VERSION "ChassisFusionCANFD"

NS_ :

BS_:

BU_: ADD BCP BCS EPS FZCU SCU SWM VECU XCD

BO_ 186 BCS_ChassisFusion_0xBA: 32 BCS
 SG_ ABSAvailability : 108|1@0+ (1,0) [0|1] ""  BCP,XCD
 SG_ BCSFxTargetMod : 135|14@0+ (8,-131008) [-131008|0] ""  BCP,XCD
 SG_ BCSModBrakeActType : 101|3@0+ (1,0) [0|4] ""  BCP,XCD
 SG_ BCSRecuFxRedTarget : 118|15@0+ (8,-131008) [-131008|131072] "bar"  BCP,XCD
 SG_ BCSRecuStatusMod : 105|2@0+ (1,0) [0|2] ""  BCP,XCD
 SG_ BrkSysAbsActv : 85|1@0+ (1,0) [0|1] ""  BCP,XCD
 SG_ BrkSysCtrlBkpSigGrpChks : 7|8@0+ (1,0) [0|255] ""  BCP,FZCU,XCD
 SG_ BrkSysCtrlBkpSigGrpCntr : 11|4@0+ (1,0) [0|15] ""  BCP,FZCU,XCD
 SG_ BrkSysDrvrPrsnt : 84|1@0+ (1,0) [0|1] ""  BCP,XCD
 SG_ BrkSysIndcnBkpSigGrpChks : 71|8@0+ (1,0) [0|255] ""  BCP,XCD
 SG_ BrkSysIndcnBkpSigGrpCntr : 75|4@0+ (1,0) [0|15] ""  BCP,XCD
 SG_ BrkSysLdmGlbStsMod : 87|2@0+ (1,0) [0|3] ""  BCP,XCD
 SG_ BrkSysMstCylP : 23|10@0+ (0.3,-30) [-27.3|276.6] "bar"  BCP,FZCU,XCD
 SG_ BrkSysMstCylPVld : 15|3@0+ (1,0) [0|7] ""  BCP,FZCU,XCD
 SG_ BrkSysPEstimnMax : 95|8@0+ (1,0) [0|250] "bar"  BCP,XCD
 SG_ BrkSysPRedActv : 12|1@0+ (1,0) [0|1] ""  BCP,FZCU,XCD
 SG_ BrkSysPSysTar : 40|9@0+ (0.25,0) [0|120] "bar"  BCP,FZCU,XCD
 SG_ BrkSysRntSpprtAvl : 44|1@0+ (1,0) [0|1] ""  BCP,FZCU,XCD
 SG_ BrkSysVehDirInfo : 29|2@0+ (1,0) [0|3] ""  BCP,FZCU,XCD
 SG_ BrkSysVehDirInfoVld : 27|3@0+ (1,0) [0|7] ""  BCP,FZCU,XCD
 SG_ BrkSysVehSpd : 39|8@0+ (0.4,0) [0|100] "m/s"  BCP,FZCU,XCD
 SG_ BrkSysVehSpdVld : 47|3@0+ (1,0) [0|7] ""  BCP,FZCU,XCD
 SG_ BrkSysVolSuctnActv : 43|1@0+ (1,0) [0|1] ""  BCP,FZCU,XCD
 SG_ MaxTarSpdBkpSigGrpChks : 151|8@0+ (1,0) [0|255] ""  FZCU,XCD
 SG_ MaxTarSpdBkpSigGrpCntr : 155|4@0+ (1,0) [0|15] ""  FZCU,XCD
 SG_ MaxTarSpdFrntAxle : 175|15@0+ (1,0) [0|30000] "rpm"  FZCU,XCD
 SG_ MaxTarSpdFrntAxleRels : 165|2@0+ (1,0) [0|3] ""  FZCU,XCD
 SG_ MaxTarSpdReAxle : 191|15@0+ (1,0) [0|30000] "rpm"  FZCU,XCD
 SG_ MaxTarSpdReAxleRels : 167|2@0+ (1,0) [0|3] ""  FZCU,XCD
 SG_ VehicleStandStill : 24|1@0+ (1,0) [0|1] ""  BCP,FZCU,XCD
 SG_ VehicleStandStillQ : 42|2@0+ (1,0) [0|2] ""  BCP,FZCU,XCD
 SG_ VehVrnt : 207|8@0+ (1,0) [0|255] ""  FZCU,XCD

BO_ 190 BCS_ChassisFusion_0xBE: 32 BCS
 SG_ BrkSysAPCBkpStgyReqCom2 : 220|1@0+ (1,0) [0|1] ""  BCP,XCD
 SG_ BrkSysAPCMain2BkpStCom2 : 219|4@0+ (1,0) [0|15] ""  BCP,XCD
 SG_ BrkSysAPCMain2BkpStCom2SigGrpChk : 207|8@0+ (1,0) [0|255] ""  BCP,XCD
 SG_ BrkSysAPCMain2BkpStCom2SigGrpCnt : 211|4@0+ (1,0) [0|15] ""  BCP,XCD
 SG_ RpbCtrlBkpSigGrpChks : 7|8@0+ (1,0) [0|255] ""  BCP,XCD
 SG_ RpbCtrlBkpSigGrpCntr : 11|4@0+ (1,0) [0|15] ""  BCP,XCD
 SG_ RPBHpsAck : 21|1@0+ (1,0) [0|1] ""  BCP,XCD
 SG_ RPBHpsAvl : 20|1@0+ (1,0) [0|1] ""  BCP,XCD
 SG_ RPBMstCylP : 17|10@0+ (0.3,-30) [-30|276.6] "bar"  BCP,XCD
 SG_ RPBMstCylPVld : 23|2@0+ (1,0) [0|3] ""  BCP,XCD
 SG_ RPBWhlPFrntLe : 39|8@0+ (1,0) [0|180] "bar"  BCP,XCD
 SG_ RPBWhlPFrntLeVld : 15|1@0+ (1,0) [0|1] ""  BCP,XCD
 SG_ RPBWhlPFrntRi : 47|8@0+ (1,0) [0|180] "bar"  BCP,XCD
 SG_ RPBWhlPFrntRiVld : 14|1@0+ (1,0) [0|1] ""  BCP,XCD
 SG_ RPBWhlPReLe : 55|8@0+ (1,0) [0|180] "bar"  BCP,XCD
 SG_ RPBWhlPReLeVld : 13|1@0+ (1,0) [0|1] ""  BCP,XCD
 SG_ RPBWhlPReRi : 63|8@0+ (1,0) [0|180] "bar"  BCP,XCD
 SG_ RPBWhlPReRiVld : 12|1@0+ (1,0) [0|1] ""  BCP,XCD
 SG_ RPBWhlSpdFrntLe : 103|16@0+ (0.05625,0) [0|360] "kph"  BCP,FZCU,XCD
 SG_ RPBWhlSpdFrntLeVld : 95|1@0+ (1,0) [0|1] ""  BCP,FZCU,XCD
 SG_ RPBWhlSpdFrntRi : 119|16@0+ (0.05625,0) [0|360] "kph"  BCP,FZCU,XCD
 SG_ RPBWhlSpdFrntRiVld : 94|1@0+ (1,0) [0|1] ""  BCP,FZCU,XCD
 SG_ RPBWhlSpdReLe : 135|16@0+ (0.05625,0) [0|360] "kph"  BCP,FZCU,XCD
 SG_ RPBWhlSpdReLeVld : 93|1@0+ (1,0) [0|1] ""  BCP,FZCU,XCD
 SG_ RPBWhlSpdReRi : 151|16@0+ (0.05625,0) [0|360] "kph"  BCP,FZCU,XCD
 SG_ RPBWhlSpdReRiVld : 92|1@0+ (1,0) [0|1] ""  BCP,FZCU,XCD
 SG_ RPBWhlSpdSigGrpChks : 79|8@0+ (1,0) [0|255] ""  BCP,FZCU,XCD
 SG_ RPBWhlSpdSigGrpCntr : 83|4@0+ (1,0) [0|15] ""  BCP,FZCU,XCD
 SG_ WhlPulFrntLe : 167|8@0+ (1,0) [0|255] ""  BCP,FZCU,XCD
 SG_ WhlPulFrntRi : 175|8@0+ (1,0) [0|255] ""  BCP,FZCU,XCD
 SG_ WhlPulReLe : 183|8@0+ (1,0) [0|255] ""  BCP,FZCU,XCD
 SG_ WhlPulReRi : 191|8@0+ (1,0) [0|255] ""  BCP,FZCU,XCD

BO_ 1315 BCSChassisFusionNMFr: 8 BCS
 SG_ BCSChassisBkpActiveWakeup : 12|1@0+ (1,0) [0|1] "" Vector__XXX
 SG_ BCSChassisBkpNodeAddress : 7|8@0+ (1,0) [0|255] "" Vector__XXX
 SG_ BCSChassisBkpRepeatMsgReq : 8|1@0+ (1,0) [0|1] "" Vector__XXX
 SG_ BCSChassisBkpRepeatMsgSt : 16|1@0+ (1,0) [0|1] "" Vector__XXX
 SG_ NMKeepAwkRsnBCS : 48|9@0+ (1,0) [0|511] "" Vector__XXX
 SG_ UDB17BCS : 17|1@0+ (1,0) [0|1] "" Vector__XXX
 SG_ UDB18BCS : 18|1@0+ (1,0) [0|1] "" Vector__XXX
 SG_ UDB19BCS : 19|1@0+ (1,0) [0|1] "" Vector__XXX
 SG_ UDB20BCS : 20|1@0+ (1,0) [0|1] "" Vector__XXX
 SG_ UDB21BCS : 21|1@0+ (1,0) [0|1] "" Vector__XXX
 SG_ UDB22BCS : 22|1@0+ (1,0) [0|1] "" Vector__XXX
 SG_ UDB23BCS : 23|1@0+ (1,0) [0|1] "" Vector__XXX
 SG_ UDB24BCS : 24|1@0+ (1,0) [0|1] "" Vector__XXX
 SG_ UDB25BCS : 25|1@0+ (1,0) [0|1] "" Vector__XXX
 SG_ UDB26BCS : 26|1@0+ (1,0) [0|1] "" Vector__XXX
 SG_ UDB27BCS : 27|1@0+ (1,0) [0|1] "" Vector__XXX
 SG_ UDB28BCS : 28|1@0+ (1,0) [0|1] "" Vector__XXX
 SG_ UDB29BCS : 29|1@0+ (1,0) [0|1] "" Vector__XXX
 SG_ UDB30BCS : 30|1@0+ (1,0) [0|1] "" Vector__XXX
 SG_ UDB31BCS : 31|1@0+ (1,0) [0|1] "" Vector__XXX
 SG_ UDB32BCS : 32|1@0+ (1,0) [0|1] "" Vector__XXX
 SG_ UDB33BCS : 33|1@0+ (1,0) [0|1] "" Vector__XXX
 SG_ UDB34BCS : 34|1@0+ (1,0) [0|1] "" Vector__XXX
 SG_ UDB35BCS : 35|1@0+ (1,0) [0|1] "" Vector__XXX
 SG_ UDB36BCS : 36|1@0+ (1,0) [0|1] "" Vector__XXX
 SG_ UDB37BCS : 37|1@0+ (1,0) [0|1] "" Vector__XXX
 SG_ UDB38BCS : 38|1@0+ (1,0) [0|1] "" Vector__XXX
 SG_ UDB39BCS : 39|1@0+ (1,0) [0|1] "" Vector__XXX
 SG_ UDB40BCS : 40|1@0+ (1,0) [0|1] "" Vector__XXX
 SG_ UDB41BCS : 41|1@0+ (1,0) [0|1] "" Vector__XXX
 SG_ UDB42BCS : 42|1@0+ (1,0) [0|1] "" Vector__XXX
 SG_ UDB43BCS : 43|1@0+ (1,0) [0|1] "" Vector__XXX
 SG_ UDB44BCS : 44|1@0+ (1,0) [0|1] "" Vector__XXX
 SG_ UDB45BCS : 45|1@0+ (1,0) [0|1] "" Vector__XXX
 SG_ UDB46BCS : 46|1@0+ (1,0) [0|1] "" Vector__XXX
 SG_ UDB47BCS : 47|1@0+ (1,0) [0|1] "" Vector__XXX

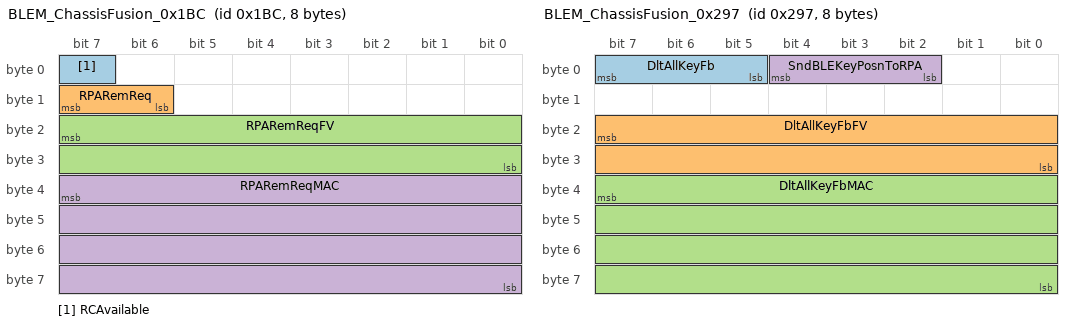
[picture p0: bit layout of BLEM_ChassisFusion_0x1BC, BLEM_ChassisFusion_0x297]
BO_ 444 BLEM_ChassisFusion_0x1BC: 8 XCD
 SG_ RCAvailable : 7|1@0+ (1,0) [0|1] ""  ADD
 SG_ RPARemReq : 15|2@0+ (1,0) [0|3] ""  ADD
 SG_ RPARemReqFV : 23|16@0+ (1,0) [0|65535] ""  ADD
 SG_ RPARemReqMAC : 39|32@0+ (1,0) [0|0] ""  ADD

BO_ 657 BLEM_ChassisFusion_0x291: 64 XCD
 SG_ BLEM2VCCDForLocn10 : 7|32@0+ (1,0) [0|4294967295] ""  ADD
 SG_ BLEM2VCCDForLocn11 : 39|32@0+ (1,0) [0|4294967295] ""  ADD
 SG_ BLEM2VCCDForLocn12 : 71|32@0+ (1,0) [0|4294967295] ""  ADD
 SG_ BLEM2VCCDForLocn13 : 103|32@0+ (1,0) [0|4294967295] ""  ADD
 SG_ BLEM2VCCDForLocn14 : 135|32@0+ (1,0) [0|4294967295] ""  ADD
 SG_ BLEM2VCCDForLocn15 : 167|32@0+ (1,0) [0|4294967295] ""  ADD
 SG_ BLEM2VCCDForLocn16 : 199|32@0+ (1,0) [0|4294967295] ""  ADD
 SG_ BLEM2VCCDForLocn17 : 231|32@0+ (1,0) [0|4294967295] ""  ADD
 SG_ BLEM2VCCDForLocn18 : 263|32@0+ (1,0) [0|4294967295] ""  ADD
 SG_ BLEM2VCCDForLocn19 : 295|32@0+ (1,0) [0|4294967295] ""  ADD
 SG_ BLEM2VCCDForLocn1A : 327|32@0+ (1,0) [0|4294967295] ""  ADD
 SG_ BLEM2VCCDForLocn1B : 359|32@0+ (1,0) [0|4294967295] ""  ADD
 SG_ BLEM2VCCDForLocn1C : 391|32@0+ (1,0) [0|4294967295] ""  ADD
 SG_ BLEM2VCCDForLocn1D : 423|32@0+ (1,0) [0|4294967295] ""  ADD
 SG_ BLEM2VCCDForLocn1F : 455|16@0+ (1,0) [0|65535] ""  ADD
 SG_ BLEM2VCCDForLocn1FV : 471|16@0+ (1,0) [0|65535] ""  ADD
 SG_ BLEM2VCCDForLocn1MAC : 487|32@0+ (1,0) [0|0] ""  ADD

BO_ 663 BLEM_ChassisFusion_0x297: 8 XCD
 SG_ DltAllKeyFb : 7|3@0+ (1,0) [0|7] "" Vector__XXX
 SG_ DltAllKeyFbFV : 23|16@0+ (1,0) [0|65535] ""  ADD
 SG_ DltAllKeyFbMAC : 39|32@0+ (1,0) [0|0] ""  ADD
 SG_ SndBLEKeyPosnToRPA : 4|3@0+ (1,0) [0|7] ""  ADD

BO_ 665 BLEM_ChassisFusion_0x299: 64 XCD
 SG_ BLEM2VCCDForLocn20 : 7|32@0+ (1,0) [0|4294967295] ""  ADD
 SG_ BLEM2VCCDForLocn21 : 39|32@0+ (1,0) [0|4294967295] ""  ADD
 SG_ BLEM2VCCDForLocn22 : 71|32@0+ (1,0) [0|4294967295] ""  ADD
 SG_ BLEM2VCCDForLocn23 : 103|32@0+ (1,0) [0|4294967295] ""  ADD
 SG_ BLEM2VCCDForLocn24 : 135|32@0+ (1,0) [0|4294967295] ""  ADD
 SG_ BLEM2VCCDForLocn25 : 167|32@0+ (1,0) [0|4294967295] ""  ADD
 SG_ BLEM2VCCDForLocn26 : 199|32@0+ (1,0) [0|4294967295] ""  ADD
 SG_ BLEM2VCCDForLocn27 : 231|32@0+ (1,0) [0|4294967295] ""  ADD
 SG_ BLEM2VCCDForLocn28 : 263|32@0+ (1,0) [0|4294967295] ""  ADD
 SG_ BLEM2VCCDForLocn29 : 295|32@0+ (1,0) [0|4294967295] ""  ADD
 SG_ BLEM2VCCDForLocn2A : 327|32@0+ (1,0) [0|4294967295] ""  ADD
 SG_ BLEM2VCCDForLocn2B : 359|32@0+ (1,0) [0|4294967295] ""  ADD
 SG_ BLEM2VCCDForLocn2C : 391|32@0+ (1,0) [0|4294967295] ""  ADD
 SG_ BLEM2VCCDForLocn2D : 423|32@0+ (1,0) [0|4294967295] ""  ADD
 SG_ BLEM2VCCDForLocn2F : 455|16@0+ (1,0) [0|65535] ""  ADD
 SG_ BLEM2VCCDForLocn2FV : 471|16@0+ (1,0) [0|65535] ""  ADD
 SG_ BLEM2VCCDForLocn2MAC : 487|32@0+ (1,0) [0|0] ""  ADD

BO_ 758 BLEM_ChassisFusion_0x2F6: 16 XCD
 SG_ FrntLeTyrePSnsrLoBattWarn : 47|1@0+ (1,0) [0|1] "" Vector__XXX
 SG_ FrntLeTyrePSnsrLostWarn : 46|1@0+ (1,0) [0|1] "" Vector__XXX
 SG_ FrntLeTyrePSnsrLrngSts : 57|2@0+ (1,0) [0|3] "" Vector__XXX
 SG_ FrntLeTyrePVal : 31|8@0+ (2.75,0) [0|698.5] "kpa"  ADD
 SG_ FrntLeTyrePWarn : 19|2@0+ (1,0) [0|3] ""  ADD
 SG_ FrntLeTyreTWarn : 55|2@0+ (1,0) [0|3] "" Vector__XXX
 SG_ FrntRiTyrePSnsrLoBattWarn : 45|1@0+ (1,0) [0|1] "" Vector__XXX
 SG_ FrntRiTyrePSnsrLostWarn : 44|1@0+ (1,0) [0|1] "" Vector__XXX
 SG_ FrntRiTyrePSnsrLrngSts : 63|2@0+ (1,0) [0|3] "" Vector__XXX
 SG_ FrntRiTyrePVal : 39|8@0+ (2.75,0) [0|698.5] "kpa"  ADD
 SG_ FrntRiTyrePWarn : 17|2@0+ (1,0) [0|3] ""  ADD
 SG_ FrntRiTyreTWarn : 53|2@0+ (1,0) [0|3] "" Vector__XXX
 SG_ ReLeTyrePSnsrLoBattWarn : 43|1@0+ (1,0) [0|1] "" Vector__XXX
 SG_ ReLeTyrePSnsrLostWarn : 42|1@0+ (1,0) [0|1] "" Vector__XXX
 SG_ ReLeTyrePSnsrLrngSts : 61|2@0+ (1,0) [0|3] "" Vector__XXX
 SG_ ReLeTyrePVal : 7|8@0+ (2.75,0) [0|698.5] "kpa"  ADD
 SG_ ReLeTyrePWarn : 23|2@0+ (1,0) [0|3] ""  ADD
 SG_ ReLeTyreTWarn : 51|2@0+ (1,0) [0|3] "" Vector__XXX
 SG_ ReRiTyrePSnsrLoBattWarn : 41|1@0+ (1,0) [0|1] "" Vector__XXX
 SG_ ReRiTyrePSnsrLostWarn : 40|1@0+ (1,0) [0|1] "" Vector__XXX
 SG_ ReRiTyrePSnsrLrngSts : 59|2@0+ (1,0) [0|3] "" Vector__XXX
 SG_ ReRiTyrePVal : 15|8@0+ (2.75,0) [0|698.5] "kpa"  ADD
 SG_ ReRiTyrePWarn : 21|2@0+ (1,0) [0|3] ""  ADD
 SG_ ReRiTyreTWarn : 49|2@0+ (1,0) [0|3] "" Vector__XXX
 SG_ TyrePWarnFV : 87|16@0+ (1,0) [0|65535] ""  ADD
 SG_ TyrePWarnMAC : 103|32@0+ (1,0) [0|4294967295] ""  ADD
 SG_ TyrePwarnSts : 71|2@0+ (1,0) [0|3] "" Vector__XXX

BO_ 817 BLEM_ChassisFusion_0x331: 64 XCD
 SG_ BLEM2VCCDForLocn40 : 135|32@0+ (1,0) [0|4294967295] ""  ADD
 SG_ BLEM2VCCDForLocn41 : 167|32@0+ (1,0) [0|4294967295] ""  ADD
 SG_ BLEM2VCCDForLocn42 : 199|32@0+ (1,0) [0|4294967295] ""  ADD
 SG_ BLEM2VCCDForLocn43 : 231|32@0+ (1,0) [0|4294967295] ""  ADD
 SG_ BLEM2VCCDForLocn44 : 7|32@0+ (1,0) [0|4294967295] ""  ADD
 SG_ BLEM2VCCDForLocn45 : 39|32@0+ (1,0) [0|4294967295] ""  ADD
 SG_ BLEM2VCCDForLocn46 : 71|32@0+ (1,0) [0|4294967295] ""  ADD
 SG_ BLEM2VCCDForLocn47 : 103|32@0+ (1,0) [0|4294967295] ""  ADD
 SG_ BLEM2VCCDForLocn48 : 263|32@0+ (1,0) [0|4294967295] ""  ADD
 SG_ BLEM2VCCDForLocn49 : 295|32@0+ (1,0) [0|4294967295] ""  ADD
 SG_ BLEM2VCCDForLocn4A : 327|32@0+ (1,0) [0|4294967295] ""  ADD
 SG_ BLEM2VCCDForLocn4B : 359|32@0+ (1,0) [0|4294967295] ""  ADD
 SG_ BLEM2VCCDForLocn4C : 391|32@0+ (1,0) [0|4294967295] ""  ADD
 SG_ BLEM2VCCDForLocn4D : 423|32@0+ (1,0) [0|4294967295] ""  ADD
 SG_ BLEM2VCCDForLocn4F : 455|16@0+ (1,0) [0|65535] ""  ADD
 SG_ BLEM2VCCDForLocn4FV : 471|16@0+ (1,0) [0|65535] ""  ADD
 SG_ BLEM2VCCDForLocn4MAC : 487|32@0+ (1,0) [0|0] ""  ADD

BO_ 825 BLEM_ChassisFusion_0x339: 32 XCD
 SG_ BLEM2ADDForRPA00 : 7|64@0+ (1,0) [0|1.84467440737096E+019] ""  ADD
 SG_ BLEM2ADDForRPA00FV : 215|16@0+ (1,0) [0|65535] ""  ADD
 SG_ BLEM2ADDForRPA00MAC : 231|32@0+ (1,0) [0|0] ""  ADD
 SG_ BLEM2ADDForRPA01 : 71|64@0+ (1,0) [0|1.84467440737096E+019] ""  ADD
 SG_ BLEM2ADDForRPA02 : 135|64@0+ (1,0) [0|1.84467440737096E+019] ""  ADD
 SG_ BLEM2ADDForRPA03 : 199|16@0+ (1,0) [0|65535] ""  ADD

BO_ 826 BLEM_ChassisFusion_0x33A: 64 XCD
 SG_ BLEM2VCCDForLocn30 : 7|32@0+ (1,0) [0|4294967295] ""  ADD
 SG_ BLEM2VCCDForLocn31 : 39|32@0+ (1,0) [0|4294967295] ""  ADD
 SG_ BLEM2VCCDForLocn32 : 71|32@0+ (1,0) [0|4294967295] ""  ADD
 SG_ BLEM2VCCDForLocn33 : 103|32@0+ (1,0) [0|4294967295] ""  ADD
 SG_ BLEM2VCCDForLocn34 : 135|32@0+ (1,0) [0|4294967295] ""  ADD
 SG_ BLEM2VCCDForLocn35 : 167|32@0+ (1,0) [0|4294967295] ""  ADD
 SG_ BLEM2VCCDForLocn36 : 199|32@0+ (1,0) [0|4294967295] ""  ADD
 SG_ BLEM2VCCDForLocn37 : 231|32@0+ (1,0) [0|4294967295] ""  ADD
 SG_ BLEM2VCCDForLocn38 : 263|32@0+ (1,0) [0|4294967295] ""  ADD
 SG_ BLEM2VCCDForLocn39 : 295|32@0+ (1,0) [0|4294967295] ""  ADD
 SG_ BLEM2VCCDForLocn3A : 327|32@0+ (1,0) [0|4294967295] ""  ADD
 SG_ BLEM2VCCDForLocn3B : 359|32@0+ (1,0) [0|4294967295] ""  ADD
 SG_ BLEM2VCCDForLocn3C : 391|32@0+ (1,0) [0|4294967295] ""  ADD
 SG_ BLEM2VCCDForLocn3D : 423|32@0+ (1,0) [0|4294967295] ""  ADD
 SG_ BLEM2VCCDForLocn3F : 455|16@0+ (1,0) [0|65535] ""  ADD
 SG_ BLEM2VCCDForLocn3FV : 471|16@0+ (1,0) [0|65535] ""  ADD
 SG_ BLEM2VCCDForLocn3MAC : 487|32@0+ (1,0) [0|0] ""  ADD

BO_ 827 BLEM_ChassisFusion_0x33B: 64 XCD
 SG_ BLEM2VCCDForRkeReq00 : 7|32@0+ (1,0) [0|4294967295] ""  ADD,FZCU
 SG_ BLEM2VCCDForRkeReq01 : 39|32@0+ (1,0) [0|4294967295] ""  ADD,FZCU
 SG_ BLEM2VCCDForRkeReq02 : 71|32@0+ (1,0) [0|4294967295] ""  ADD,FZCU
 SG_ BLEM2VCCDForRkeReq03 : 103|32@0+ (1,0) [0|4294967295] ""  ADD,FZCU
 SG_ BLEM2VCCDForRkeReq04 : 135|32@0+ (1,0) [0|4294967295] ""  ADD,FZCU
 SG_ BLEM2VCCDForRkeReq05 : 167|32@0+ (1,0) [0|4294967295] ""  ADD,FZCU
 SG_ BLEM2VCCDForRkeReq06 : 199|32@0+ (1,0) [0|4294967295] ""  ADD,FZCU
 SG_ BLEM2VCCDForRkeReq07 : 231|32@0+ (1,0) [0|4294967295] ""  ADD,FZCU
 SG_ BLEM2VCCDForRkeReq08 : 263|32@0+ (1,0) [0|4294967295] ""  ADD,FZCU
 SG_ BLEM2VCCDForRkeReq09 : 295|32@0+ (1,0) [0|4294967295] ""  ADD,FZCU
 SG_ BLEM2VCCDForRkeReq10 : 327|32@0+ (1,0) [0|4294967295] ""  ADD,FZCU
 SG_ BLEM2VCCDForRkeReq11 : 359|32@0+ (1,0) [0|4294967295] ""  ADD,FZCU
 SG_ BLEM2VCCDForRkeReq12 : 391|32@0+ (1,0) [0|4294967295] ""  ADD,FZCU
 SG_ BLEM2VCCDForRkeReq13 : 423|32@0+ (1,0) [0|4294967295] ""  ADD,FZCU
 SG_ BLEM2VCCDForRkeReq14 : 455|16@0+ (1,0) [0|65535] ""  ADD,FZCU
 SG_ BLEM2VCCDForRkeReqFV : 471|16@0+ (1,0) [0|65535] ""  ADD,FZCU
 SG_ BLEM2VCCDForRkeReqMAC : 487|32@0+ (1,0) [0|0] ""  ADD,FZCU

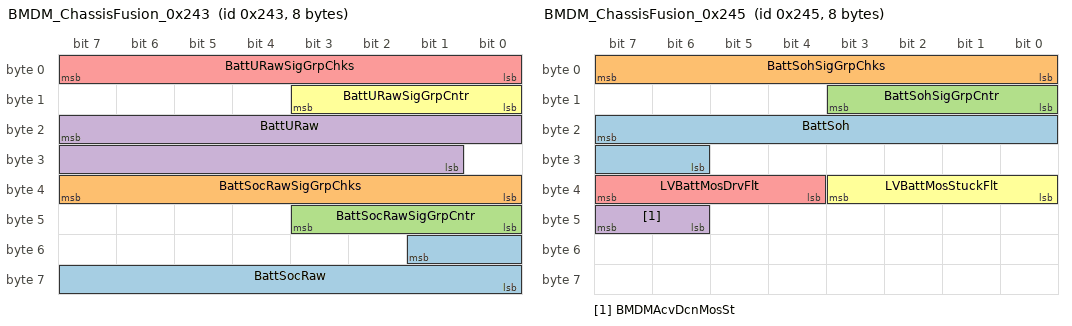
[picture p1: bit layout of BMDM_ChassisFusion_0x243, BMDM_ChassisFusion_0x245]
BO_ 579 BMDM_ChassisFusion_0x243: 8 XCD
 SG_ BattSocRaw : 49|10@0+ (0.1,0) [0|102.3] "%"  SCU,SWM
 SG_ BattSocRawSigGrpChks : 39|8@0+ (1,0) [0|255] ""  SCU,SWM
 SG_ BattSocRawSigGrpCntr : 43|4@0+ (1,0) [0|15] ""  SCU,SWM
 SG_ BattURaw : 23|15@0+ (0.001,0) [0|18] "V"  SCU,SWM
 SG_ BattURawSigGrpChks : 7|8@0+ (1,0) [0|255] ""  SCU,SWM
 SG_ BattURawSigGrpCntr : 11|4@0+ (1,0) [0|15] ""  SCU,SWM

BO_ 581 BMDM_ChassisFusion_0x245: 8 XCD
 SG_ BattSoh : 23|10@0+ (0.1,0) [0|102.3] "%"  ADD
 SG_ BattSohSigGrpChks : 7|8@0+ (1,0) [0|255] ""  ADD
 SG_ BattSohSigGrpCntr : 11|4@0+ (1,0) [0|15] ""  ADD
 SG_ BMDMAcvDcnMosSt : 47|2@0+ (1,0) [0|3] ""  ADD
 SG_ LVBattMosDrvFlt : 39|4@0+ (1,0) [0|15] "" Vector__XXX
 SG_ LVBattMosStuckFlt : 35|4@0+ (1,0) [0|15] "" Vector__XXX

BO_ 912 BMS_ChassisFusion_0x390: 32 XCD
 SG_ BalOnCellNumb : 207|8@0+ (1,0) [0|255] "" Vector__XXX
 SG_ CMU1ComErrTi : 87|8@0+ (0.5,0) [0|127.5] "s" Vector__XXX
 SG_ CMU2ComErrTi : 95|8@0+ (0.5,0) [0|127.5] "s" Vector__XXX
 SG_ CMU3ComErrTi : 103|8@0+ (0.5,0) [0|127.5] "s" Vector__XXX
 SG_ HvBattCellAvrgSocErr : 135|11@0+ (0.05,0) [0|100] "%" Vector__XXX
 SG_ HvBattCellMaxSoc : 114|11@0+ (0.05,0) [0|100] "%" Vector__XXX
 SG_ HvBattCellMaxSocErr : 183|11@0+ (0.05,0) [0|100] "%" Vector__XXX
 SG_ HvBattCellMaxSocErrIdx : 175|8@0+ (1,0) [1|255] "" Vector__XXX
 SG_ HvBattCellMaxSocIdx : 159|8@0+ (1,0) [1|255] "" Vector__XXX
 SG_ HvBattCellMinSoc : 186|11@0+ (0.05,0) [0|100] "%" Vector__XXX
 SG_ HvBattCellMinSocIdx : 167|8@0+ (1,0) [1|255] "" Vector__XXX
 SG_ HvBattEgyAvlForChrgnToTarSoC : 55|13@0+ (20,0) [0|163000] "Wh" Vector__XXX
 SG_ HvBattEgyAvlForDchrgnToTarSoC : 39|13@0+ (20,0) [0|163000] "Wh" Vector__XXX
 SG_ HvBattPressureInsdPack : 71|12@0+ (0.1,0) [0|409.4] "kPa"  SCU
 SG_ HvBattSoCLimMax : 7|11@0+ (0.05,0) [0|100] "%" Vector__XXX
 SG_ HvBattSoCLimMin : 23|11@0+ (0.05,0) [0|100] "%" Vector__XXX
 SG_ HvPrechargeTimer : 140|13@0+ (1,0) [0|8191] "" Vector__XXX

BO_ 355 EPS_ChassisFusion_0x163: 16 EPS
 SG_ AVPHPPCtrlAvlStsBkp : 71|2@0+ (1,0) [0|3] ""  ADD,XCD
 SG_ AVPHPPCtrStsBkp : 56|1@0+ (1,0) [0|1] ""  ADD,XCD
 SG_ AVPHPPReqFbStsBkp : 59|3@0+ (1,0) [0|7] ""  ADD,XCD
 SG_ AVPHPPReqFltStsBkp : 63|4@0+ (1,0) [0|15] ""  ADD,XCD
 SG_ EPSAVPHPPCtrlStsBkpSigGrpChks : 47|8@0+ (1,0) [0|255] ""  ADD,XCD
 SG_ EPSAVPHPPCtrlStsBkpSigGrpCntr : 51|4@0+ (1,0) [0|15] ""  ADD,XCD
 SG_ EPSBkpFaultInfoFlag : 7|1@0+ (1,0) [0|1] ""  XCD
 SG_ FailrStsBkp : 38|3@0+ (1,0) [0|7] ""  ADD,XCD
 SG_ FailrStsBkpSigGrpChks : 31|8@0+ (1,0) [0|255] ""  ADD,XCD
 SG_ FailrStsBkpSigGrpCntr : 35|4@0+ (1,0) [0|15] ""  ADD,XCD

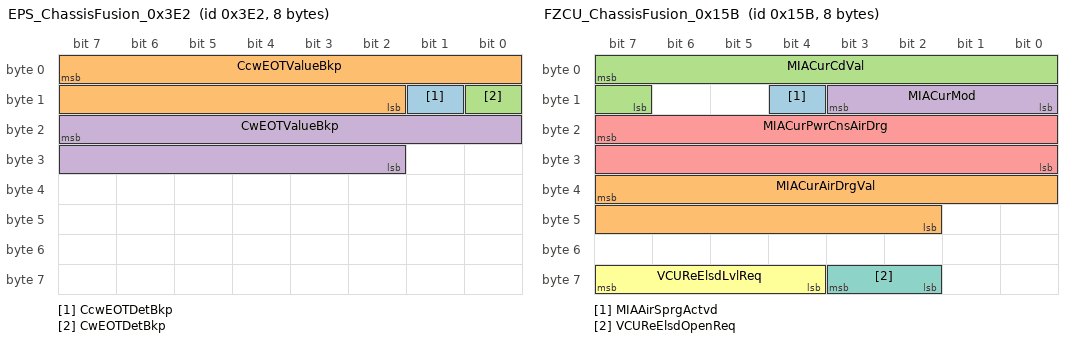
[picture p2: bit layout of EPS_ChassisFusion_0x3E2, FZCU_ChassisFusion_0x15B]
BO_ 994 EPS_ChassisFusion_0x3E2: 8 EPS
 SG_ CcwEOTDetBkp : 9|1@0+ (1,0) [0|1] ""  ADD,XCD
 SG_ CcwEOTValueBkp : 7|14@0+ (0.0625,0) [0|780] ""  ADD,XCD
 SG_ CwEOTDetBkp : 8|1@0+ (1,0) [0|1] ""  ADD,XCD
 SG_ CwEOTValueBkp : 23|14@0+ (0.0625,-780) [-780|0] "deg"  ADD,XCD

BO_ 181 EPS_ChassisFusion_0xB5: 32 XCD
 SG_ AdasReqCtrlADDSigGrpChks : 39|8@0+ (1,0) [0|255] "" Vector__XXX
 SG_ AdasReqCtrlADDSigGrpCntr : 43|4@0+ (1,0) [0|15] "" Vector__XXX
 SG_ ADASReqFbStsADD : 50|3@0+ (1,0) [0|7] "" Vector__XXX
 SG_ ADASReqFltStsADD : 53|3@0+ (1,0) [0|7] "" Vector__XXX
 SG_ ADASReqOvlySteerWhlTqADD : 63|11@0- (0.01,0) [-10.24|10.23] "Nm" Vector__XXX
 SG_ ADASReqOvlyTqADD : 79|14@0- (0.00390625,0) [-30|30] "Nm" Vector__XXX
 SG_ DrvrSteerActvADD : 55|1@0+ (1,0) [0|1] "" Vector__XXX
 SG_ ElecPwrCns : 231|11@0+ (0.1,0) [0|140] "A" Vector__XXX
 SG_ EPSMotTqCmd : 7|11@0- (0.01,0) [-10.24|10.23] "Nm" Vector__XXX
 SG_ EstimdRkF : 247|16@0- (1,0) [-32768|32767] "N" Vector__XXX
 SG_ EstimdRkFVld : 236|1@0+ (1,0) [0|1] "" Vector__XXX
 SG_ PinionAglSpdV2C : 199|12@0- (1,0) [-2048|2047] "deg/s"  SCU
 SG_ PinionSteerAgl : 151|15@0- (0.0625,0) [-780|780] "°(deg)"  SCU
 SG_ PinionSteerAglSpd : 183|12@0- (1,0) [-2048|2047] "deg/s"  SCU
 SG_ PinionSteerAglSpdVld : 187|1@0+ (1,0) [0|1] ""  SCU
 SG_ PinionSteerAglSpdVldV2C : 186|1@0+ (1,0) [0|1] ""  SCU
 SG_ PinionSteerAglV2C : 215|15@0- (0.0625,0) [-780|780] "°（deg）"  SCU
 SG_ PinionSteerAglVld : 152|1@0+ (1,0) [0|1] ""  SCU
 SG_ PinionSteerAglVldV2C : 185|1@0+ (1,0) [0|1] ""  SCU
 SG_ PinionSteerSigGrpChks : 135|8@0+ (1,0) [0|255] ""  SCU
 SG_ PinionSteerSigGrpCntr : 139|4@0+ (1,0) [0|15] ""  SCU
 SG_ SteerWhlTq : 167|11@0- (0.01,0) [-10.24|10.23] "Nm"  SCU
 SG_ SteerWhlTqVld : 172|1@0+ (1,0) [0|1] ""  SCU
 SG_ SteerWhlVibStsADD : 54|1@0+ (1,0) [0|1] "" Vector__XXX
 SG_ VehSpdEPSInUse : 23|16@0+ (0.05625,0) [0|360] "kph" Vector__XXX

BO_ 200 EPS_ChassisFusion_0xC8: 16 EPS
 SG_ PinionAglSpdBkpV2C : 71|12@0- (1,0) [-2048|2047] "deg/s"  ADD,FZCU,VECU
 SG_ PinionSteerAglBkp : 22|15@0- (0.0625,0) [-780|780] "°(deg)"  ADD,FZCU,VECU
 SG_ PinionSteerAglBkpV2C : 87|15@0- (0.0625,0) [-780|780] "°（deg）"  ADD,FZCU,VECU
 SG_ PinionSteerAglSpdBkp : 55|12@0- (1,0) [-2048|2047] "deg/s"  ADD,FZCU,VECU
 SG_ PinionSteerAglSpdVldBkp : 59|1@0+ (1,0) [0|1] ""  ADD,FZCU,VECU
 SG_ PinionSteerAglSpdVldBkpV2C : 75|1@0+ (1,0) [0|1] ""  ADD,FZCU,VECU
 SG_ PinionSteerAglVldBkp : 23|1@0+ (1,0) [0|1] ""  ADD,FZCU,VECU
 SG_ PinionSteerAglVldBkpV2C : 74|1@0+ (1,0) [0|1] ""  ADD,FZCU,VECU
 SG_ SteeringWhlSignalBkpSigGrpChks : 7|8@0+ (1,0) [0|255] ""  ADD,FZCU,VECU
 SG_ SteeringWhlSignalBkpSigGrpCntr : 11|4@0+ (1,0) [0|15] ""  ADD,FZCU,VECU
 SG_ SteerWhlTqBkp : 39|11@0- (0.01,0) [-10.24|10.23] "Nm"  ADD,FZCU,VECU
 SG_ SteerWhlTqVldBkp : 44|1@0+ (1,0) [0|1] ""  ADD,FZCU,VECU

BO_ 1322 EPSChassisFusionNMFr: 8 EPS
 SG_ EPSChassisBkpActiveWakeup : 12|1@0+ (1,0) [0|1] "" Vector__XXX
 SG_ EPSChassisBkpNodeAddress : 7|8@0+ (1,0) [0|255] "" Vector__XXX
 SG_ EPSChassisBkpRepeatMsgReq : 8|1@0+ (1,0) [0|1] "" Vector__XXX
 SG_ EPSChassisBkpRepeatMsgSt : 16|1@0+ (1,0) [0|1] "" Vector__XXX
 SG_ NMKeepAwkRsnEPS : 48|9@0+ (1,0) [0|511] "" Vector__XXX
 SG_ UDB17EPS : 17|1@0+ (1,0) [0|1] "" Vector__XXX
 SG_ UDB18EPS : 18|1@0+ (1,0) [0|1] "" Vector__XXX
 SG_ UDB19EPS : 19|1@0+ (1,0) [0|1] "" Vector__XXX
 SG_ UDB20EPS : 20|1@0+ (1,0) [0|1] "" Vector__XXX
 SG_ UDB21EPS : 21|1@0+ (1,0) [0|1] "" Vector__XXX
 SG_ UDB22EPS : 22|1@0+ (1,0) [0|1] "" Vector__XXX
 SG_ UDB23EPS : 23|1@0+ (1,0) [0|1] "" Vector__XXX
 SG_ UDB24EPS : 24|1@0+ (1,0) [0|1] "" Vector__XXX
 SG_ UDB25EPS : 25|1@0+ (1,0) [0|1] "" Vector__XXX
 SG_ UDB26EPS : 26|1@0+ (1,0) [0|1] "" Vector__XXX
 SG_ UDB27EPS : 27|1@0+ (1,0) [0|1] "" Vector__XXX
 SG_ UDB28EPS : 28|1@0+ (1,0) [0|1] "" Vector__XXX
 SG_ UDB29EPS : 29|1@0+ (1,0) [0|1] "" Vector__XXX
 SG_ UDB30EPS : 30|1@0+ (1,0) [0|1] "" Vector__XXX
 SG_ UDB31EPS : 31|1@0+ (1,0) [0|1] "" Vector__XXX
 SG_ UDB32EPS : 32|1@0+ (1,0) [0|1] "" Vector__XXX
 SG_ UDB33EPS : 33|1@0+ (1,0) [0|1] "" Vector__XXX
 SG_ UDB34EPS : 34|1@0+ (1,0) [0|1] "" Vector__XXX
 SG_ UDB35EPS : 35|1@0+ (1,0) [0|1] "" Vector__XXX
 SG_ UDB36EPS : 36|1@0+ (1,0) [0|1] "" Vector__XXX
 SG_ UDB37EPS : 37|1@0+ (1,0) [0|1] "" Vector__XXX
 SG_ UDB38EPS : 38|1@0+ (1,0) [0|1] "" Vector__XXX
 SG_ UDB39EPS : 39|1@0+ (1,0) [0|1] "" Vector__XXX
 SG_ UDB40EPS : 40|1@0+ (1,0) [0|1] "" Vector__XXX
 SG_ UDB41EPS : 41|1@0+ (1,0) [0|1] "" Vector__XXX
 SG_ UDB42EPS : 42|1@0+ (1,0) [0|1] "" Vector__XXX
 SG_ UDB43EPS : 43|1@0+ (1,0) [0|1] "" Vector__XXX
 SG_ UDB44EPS : 44|1@0+ (1,0) [0|1] "" Vector__XXX
 SG_ UDB45EPS : 45|1@0+ (1,0) [0|1] "" Vector__XXX
 SG_ UDB46EPS : 46|1@0+ (1,0) [0|1] "" Vector__XXX
 SG_ UDB47EPS : 47|1@0+ (1,0) [0|1] "" Vector__XXX

BO_ 1576 EPSToXCDChassisFusionDiagRespFr: 64 EPS
 SG_ EPSToVCCDChassisBkpDiagResp : 7|512@0+ (1,0) [0|0] ""  XCD

BO_ 347 FZCU_ChassisFusion_0x15B: 8 FZCU
 SG_ MIAAirSprgActvd : 12|1@0+ (1,0) [0|1] ""  SCU
 SG_ MIACurAirDrgVal : 39|14@0+ (1,-1000) [-1000|4000] "N"  XCD
 SG_ MIACurCdVal : 7|9@0+ (0.001,0) [0|0.4] ""  XCD
 SG_ MIACurMod : 11|4@0+ (1,0) [0|7] ""  SCU
 SG_ MIACurPwrCnsAirDrg : 23|16@0+ (0.1,-1000) [-1000|5553.5] "W"  XCD
 SG_ VCUReElsdLvlReq : 63|4@0+ (1,0) [0|15] "" Vector__XXX
 SG_ VCUReElsdOpenReq : 59|2@0+ (1,0) [0|3] "" Vector__XXX

BO_ 515 FZCU_ChassisFusion_0x203: 16 FZCU
 SG_ VCUExtmPfmncMod : 28|1@0+ (1,0) [0|1] ""  ADD,SCU,XCD
 SG_ VCULnchPlusSts : 26|2@0+ (1,0) [0|2] ""  SCU
 SG_ VCUTrlrModStSts : 39|1@0+ (1,0) [0|1] ""  ADD,BCP,BCS,SCU,XCD
 SG_ VCUWashModStSts : 27|1@0+ (1,0) [0|1] ""  ADD,BCP,BCS,SCU,XCD
 SG_ VDMMueEstdForADD : 38|4@0+ (0.1,0) [0|1.5] ""  ADD

BO_ 533 FZCU_ChassisFusion_0x215: 8 FZCU
 SG_ FZCUSyncFVReq1 : 7|32@0+ (1,0) [0|4294967295] ""  XCD

BO_ 656 FZCU_ChassisFusion_0x290: 32 FZCU
 SG_ ADDCooltCircFlowEstimd : 119|10@0+ (0.05,0) [0|51.15] "L/min"  ADD
 SG_ AmbTEstimd : 103|16@0+ (0.01,-80) [-80|175] "degC"  ADD,EPS,SCU
 SG_ AmbTEstimdVld : 91|1@0+ (1,0) [0|1] ""  ADD,EPS,SCU
 SG_ AmbTRaw : 135|16@0+ (0.01,-80) [-80|175] "degC"  BCP,BCS,SCU
 SG_ AmbTRawVld : 90|1@0+ (1,0) [0|1] ""  BCP,BCS,SCU
 SG_ EdsCircCooltT : 151|16@0+ (0.01,-80) [-80|175] "degC"  ADD
 SG_ EdsCircCooltTSnsrU : 167|16@0+ (0.1,0) [0|5000] "mV"  ADD
 SG_ EdsCircCooltTVld : 89|1@0+ (1,0) [0|1] ""  ADD
 SG_ InsEgyCnsSigGrpChks : 7|8@0+ (1,0) [0|255] ""  ADD
 SG_ InsEgyCnsSigGrpCntr : 11|4@0+ (1,0) [0|15] ""  ADD
 SG_ LRRLoPwrSplySts : 88|1@0+ (1,0) [0|1] ""  ADD
 SG_ VCUBattOverHeatWarn : 201|1@0+ (1,0) [0|1] ""  ADD
 SG_ VCUChrgnModSts : 95|4@0+ (1,0) [0|15] ""  SCU
 SG_ VCUDrvMotFltWarn : 200|1@0+ (1,0) [0|1] ""  ADD
 SG_ VCUDrvMotOverHeatWarn : 215|1@0+ (1,0) [0|1] ""  ADD
 SG_ VCUDrvSysLimdWarn : 214|1@0+ (1,0) [0|1] ""  ADD
 SG_ VCUEgyCnsInCurDrvCyc : 23|18@0+ (0.01,-200) [-200|200] "kwh"  ADD
 SG_ VCUEstimdCrsRng : 71|11@0+ (1,0) [0|2046] ""  ADD
 SG_ VCUEstimdCrsRngForCltc : 74|11@0+ (1,0) [0|2047] ""  ADD
 SG_ VCUEstimdCrsRngVld : 76|1@0+ (1,0) [0|1] ""  ADD
 SG_ VCUGearChgFailInde : 207|4@0+ (1,0) [0|15] ""  ADD
 SG_ VCUHvBattSysFltIndcr : 213|1@0+ (1,0) [0|1] ""  ADD
 SG_ VCUHvBattSysFltWarn : 212|1@0+ (1,0) [0|1] ""  ADD
 SG_ VCUHvPwrSysCutOff : 211|1@0+ (1,0) [0|1] ""  ADD
 SG_ VCUHVSysFltWarnSts : 199|4@0+ (1,0) [0|15] ""  ADD
 SG_ VCUInsEgyCnsDurgDrvg : 55|11@0+ (0.1,-100) [-100|100] ""  ADD
 SG_ VCUInsEgyCnsDurgStsl : 32|9@0+ (0.1,0) [0|50] ""  ADD
 SG_ VCUInsEgyCnsFlg : 60|1@0+ (1,0) [0|1] ""  ADD
 SG_ VCULoSocWarngMsg : 203|2@0+ (1,0) [0|2] ""  ADD
 SG_ VCUPrpsnPwrDrt : 210|1@0+ (1,0) [0|1] ""  ADD
 SG_ VCUThermRunawayErrAlrm : 209|1@0+ (1,0) [0|1] ""  ADD
 SG_ VCUVehSysFltWarn : 208|1@0+ (1,0) [0|1] ""  ADD
 SG_ VehSysFltWarnSigGrpChks : 191|8@0+ (1,0) [0|255] ""  ADD
 SG_ VehSysFltWarnSigGrpCntr : 195|4@0+ (1,0) [0|15] ""  ADD

BO_ 144 FZCU_ChassisFusion_0x90: 24 FZCU
 SG_ CarModSts : 126|3@0+ (1,0) [0|7] ""  BCP,BCS,EPS,SCU,SWM
 SG_ PwrModSigGrpChks : 7|8@0+ (1,0) [0|255] ""  BCP,BCS,EPS,SCU,SWM
 SG_ PwrModSigGrpCntr : 11|4@0+ (1,0) [0|15] ""  BCP,BCS,EPS,SCU,SWM
 SG_ PwrModSts : 23|3@0+ (1,0) [0|7] ""  BCP,BCS,EPS,SCU,SWM
 SG_ PwrModVld : 20|1@0+ (1,0) [0|1] ""  BCP,BCS,EPS,SCU,SWM
 SG_ VCUAccrPedlRat : 87|15@0+ (0.004,0) [0|100] "pct"  BCP,BCS,SCU
 SG_ VCUAccrPedlRatVld : 111|1@0+ (1,0) [0|1] ""  BCP,BCS,SCU
 SG_ VCUActDrvMod : 123|4@0+ (1,0) [0|15] ""  BCP,BCS,SCU
 SG_ VCUActGearLvr : 55|3@0+ (1,0) [0|7] ""  BCP,BCS,SCU,SWM
 SG_ VCUActGearLvrVld : 52|1@0+ (1,0) [0|1] ""  BCP,BCS,SCU,SWM
 SG_ VCUActGearSigGrpChks : 47|8@0+ (1,0) [0|255] ""  BCP,BCS,SCU,SWM
 SG_ VCUActGearSigGrpCntr : 51|4@0+ (1,0) [0|15] ""  BCP,BCS,SCU,SWM
 SG_ VCUDrvModSteerAsstPrmSts : 143|3@0+ (1,0) [0|7] ""  BCP,BCS,SCU
 SG_ VCUDrvModSuspDampgPrmSts : 140|2@0+ (1,0) [0|3] ""  BCP,BCS,SCU
 SG_ VCUDrvModSuspLvlgPrmSts : 134|3@0+ (1,0) [0|5] ""  SCU
 SG_ VCUDrvOffFcnLim : 119|1@0+ (1,0) [0|1] ""  BCP,BCS,SCU
 SG_ VCUFrntEmTqRdy : 110|1@0+ (1,0) [0|1] ""  BCP,BCS,SCU
 SG_ VCUGearLvrAvail : 118|1@0+ (1,0) [0|1] ""  BCP,BCS,SCU
 SG_ VcuInpSigGrpChks : 63|8@0+ (1,0) [0|255] ""  BCP,BCS,SCU
 SG_ VcuInpSigGrpCntr : 67|4@0+ (1,0) [0|15] ""  BCP,BCS,SCU
 SG_ VCUPrkgBtnPsd : 88|1@0+ (1,0) [0|1] ""  BCP,BCS,SCU
 SG_ VCUPrkgBtnPsdVld : 135|1@0+ (1,0) [0|1] ""  BCP,BCS
 SG_ VCUPtRdyFlg : 127|1@0+ (1,0) [0|1] ""  BCP,BCS,SCU,SWM
 SG_ VCUReEmTqRdy : 109|1@0+ (1,0) [0|1] ""  BCP,BCS,SCU
 SG_ VCURgnTqCorrnFac : 71|4@0+ (0.1,0) [0|1] ""  BCP,BCS,SCU
 SG_ VCUShifterMoveFlg : 104|1@0+ (1,0) [0|1] ""  BCP,BCS,SCU
 SG_ VCUStsModCst : 79|8@0+ (1,0) [0|255] ""  BCP,BCS,SCU
 SG_ VCUTarGearLvr : 108|3@0+ (1,0) [0|7] ""  BCP,BCS,SCU
 SG_ VCUTarGearLvrVld : 96|1@0+ (1,0) [0|1] ""  BCP,BCS,SCU
 SG_ VCUVirtAccrPedl : 103|7@0+ (1,0) [0|100] "%"  BCP,BCS,SCU
 SG_ VCUVirtAccrPedlVld : 105|1@0+ (1,0) [0|1] ""  BCP,BCS,SCU

BO_ 188 FZCU_ChassisFusion_0xBC: 64 FZCU
 SG_ DmcModMonSigGrpChks : 327|8@0+ (1,0) [0|255] ""  BCS,XCD
 SG_ DmcModMonSigGrpCntr : 331|4@0+ (1,0) [0|15] ""  BCS,XCD
 SG_ FrntMotCtrlSigGrpChks : 23|8@0+ (1,0) [0|255] ""  ADD,BCP,BCS,SCU,XCD
 SG_ FrntMotCtrlSigGrpCntr : 27|4@0+ (1,0) [0|15] ""  ADD,BCP,BCS,SCU,XCD
 SG_ PreDampgCtrlReqFL : 511|1@0+ (1,0) [0|1] ""  SCU
 SG_ PreDampgCtrlReqFR : 510|1@0+ (1,0) [0|1] ""  SCU
 SG_ PreDampgCtrlReqRL : 509|1@0+ (1,0) [0|1] ""  SCU
 SG_ PreDampgCtrlReqRR : 508|1@0+ (1,0) [0|1] ""  SCU
 SG_ RdRghnessLvl : 507|3@0+ (1,0) [0|4] ""  SCU
 SG_ ReMotCtrlSigGrpChks : 135|8@0+ (1,0) [0|255] ""  ADD,BCP,BCS,SCU,XCD
 SG_ ReMotCtrlSigGrpCntr : 139|4@0+ (1,0) [0|15] ""  ADD,BCP,BCS,SCU,XCD
 SG_ SuspRoadConditionForADD : 399|8@0+ (1,0) [0|255] ""  ADD
 SG_ VCUAccrPedlRatGrdt : 6|15@0- (0.0625,0) [-1000|1000] ""  SCU
 SG_ VCUFrntDesTqWoIntv : 39|15@0+ (1,-16383) [-16383|16384] "Nm"  ADD,BCP,BCS,SCU,XCD
 SG_ VCUFrntDesTqWoIntvVld : 40|1@0+ (1,0) [0|1] ""  ADD,BCP,BCS,SCU,XCD
 SG_ VCUFrntMotActSpd : 55|16@0+ (1,-32767) [-32767|32768] "rpm"  ADD,BCP,BCS,SCU,XCD
 SG_ VCUFrntMotActSpdVld : 72|1@0+ (1,0) [0|1] ""  ADD,BCP,BCS,SCU,XCD
 SG_ VCUFrntMotActTq : 71|15@0+ (1,-16383) [-16383|16384] "Nm"  ADD,BCP,BCS,SCU,XCD
 SG_ VCUFrntMotActTqVld : 88|1@0+ (1,0) [0|1] ""  ADD,BCP,BCS,SCU,XCD
 SG_ VCUFrntMotWhlTqReq : 87|15@0+ (1,-16383) [-16383|16383] "Nm"  ADD,BCP,BCS,SCU,XCD
 SG_ VCUFrntMotWhlTqReqVld : 104|1@0+ (1,0) [0|1] ""  ADD,BCP,BCS,SCU,XCD
 SG_ VCUFrntWhlTqMaxAvl : 103|14@0+ (1,0) [0|16383] "Nm"  ADD,BCP,BCS,SCU,XCD
 SG_ VCUFrntWhlTqMaxAvlVld : 105|1@0+ (1,0) [0|1] ""  ADD,BCP,BCS,SCU,XCD
 SG_ VCUFrntWhlTqMinAvl : 119|14@0+ (1,-16383) [-16383|0] "Nm"  ADD,BCP,BCS,SCU,XCD
 SG_ VCUFrntWhlTqMinAvlVld : 121|1@0+ (1,0) [0|1] ""  ADD,BCP,BCS,SCU,XCD
 SG_ VCULnchPlusAcvFlg : 504|1@0+ (1,0) [0|1] ""  SCU
 SG_ VCUOperModFAOfDMC : 343|4@0+ (1,0) [0|15] ""  BCS,XCD
 SG_ VCUOperModRAOfDMC : 339|4@0+ (1,0) [0|15] ""  BCS,XCD
 SG_ VCUReDesTqWoIntv : 167|15@0+ (1,-16383) [-16383|16384] "Nm"  ADD,BCP,BCS,SCU,XCD
 SG_ VCUReDesTqWoIntvVld : 168|1@0+ (1,0) [0|1] ""  ADD,BCP,BCS,SCU,XCD
 SG_ VCUReMotActSpd : 183|16@0+ (1,-32767) [-32767|32768] "rpm"  ADD,BCP,BCS,SCU,XCD
 SG_ VCUReMotActSpdVld : 200|1@0+ (1,0) [0|1] ""  ADD,BCP,BCS,SCU,XCD
 SG_ VCUReMotActTq : 199|15@0+ (1,-16383) [-16383|16384] "Nm"  ADD,BCP,BCS,SCU,XCD
 SG_ VCUReMotActTqVld : 216|1@0+ (1,0) [0|1] ""  ADD,BCP,BCS,SCU,XCD
 SG_ VCUReMotWhlTqReq : 215|15@0+ (1,-16383) [-16383|16383] "Nm"  ADD,BCP,BCS,SCU,XCD
 SG_ VCUReMotWhlTqReqVld : 233|1@0+ (1,0) [0|1] ""  ADD,BCP,BCS,SCU,XCD
 SG_ VCUReWhlTqMaxAvl : 231|14@0+ (1,0) [0|16383] "Nm"  ADD,BCP,BCS,SCU,XCD
 SG_ VCUReWhlTqMaxAvlVld : 232|1@0+ (1,0) [0|1] ""  ADD,BCP,BCS,SCU,XCD
 SG_ VCUReWhlTqMinAvl : 151|14@0+ (1,-16383) [-16383|0] "Nm"  ADD,BCP,BCS,SCU,XCD
 SG_ VCUReWhlTqMinAvlVld : 153|1@0+ (1,0) [0|1] ""  ADD,BCP,BCS,SCU,XCD
 SG_ VCUSWVersOfDMC : 351|16@0+ (1,0) [0|65535] ""  BCS,XCD
 SG_ VCUTarTqFAAOfDMC : 367|16@0- (1,0) [-30000|30000] ""  BCS,XCD
 SG_ VCUTarTqRAOfDMC : 383|16@0- (1,0) [-30000|30000] ""  BCS,XCD
 SG_ VCUWhlTqMaxAvl : 311|15@0+ (1,0) [0|32767] "N.m"  ADD,BCP,BCS,SCU,XCD
 SG_ VCUWhlTqMaxAvlVld : 312|1@0+ (1,0) [0|1] ""  ADD,BCP,BCS,SCU,XCD
 SG_ VDMLgtWhlSpdFL : 425|10@0+ (0.1,0) [0|100] "mps"  ADD,EPS,SCU,XCD
 SG_ VDMLgtWhlSpdFR : 447|10@0+ (0.1,0) [0|100] "mps"  ADD,EPS,SCU,XCD
 SG_ VDMLgtWhlSpdRL : 449|10@0+ (0.1,0) [0|100] "mps"  ADD,EPS,SCU,XCD
 SG_ VDMLgtWhlSpdRR : 471|10@0+ (0.1,0) [0|100] "mps"  ADD,EPS,SCU,XCD
 SG_ VDMVehSpdEstmGrpChks : 407|8@0+ (1,0) [0|255] ""  ADD,EPS,SCU,XCD
 SG_ VDMVehSpdEstmGrpCntr : 411|4@0+ (1,0) [0|15] ""  ADD,EPS,SCU,XCD
 SG_ VehBodySideSlipAng : 475|12@0+ (0.01,-6) [-6|6] "deg"  ADD,EPS,SCU,XCD
 SG_ VehLatSpdEstd : 495|10@0+ (0.1,0) [0|100] "m/s"  ADD,EPS,SCU,XCD
 SG_ VehLatSpdEstdVld : 501|1@0+ (1,0) [0|1] ""  ADD,EPS,SCU,XCD
 SG_ VehLgtSpdEstd : 423|10@0+ (0.1,0) [0|100] "m/s"  ADD,EPS,SCU,XCD
 SG_ VehLgtSpdEstdVld : 429|1@0+ (1,0) [0|1] ""  ADD,EPS,SCU,XCD

BO_ 1403 FZCUChassisFusionNMFra: 8 FZCU
 SG_ NMKeepAwkRsnFZCU : 48|9@0+ (1,0) [0|511] "" Vector__XXX
 SG_ UDB17FZCU : 17|1@0+ (1,0) [0|1] "" Vector__XXX
 SG_ UDB18FZCU : 18|1@0+ (1,0) [0|1] "" Vector__XXX
 SG_ UDB19FZCU : 19|1@0+ (1,0) [0|1] "" Vector__XXX
 SG_ UDB20FZCU : 20|1@0+ (1,0) [0|1] "" Vector__XXX
 SG_ UDB21FZCU : 21|1@0+ (1,0) [0|1] "" Vector__XXX
 SG_ UDB22FZCU : 22|1@0+ (1,0) [0|1] "" Vector__XXX
 SG_ UDB23FZCU : 23|1@0+ (1,0) [0|1] "" Vector__XXX
 SG_ UDB24FZCU : 24|1@0+ (1,0) [0|1] "" Vector__XXX
 SG_ UDB25FZCU : 25|1@0+ (1,0) [0|1] "" Vector__XXX
 SG_ UDB26FZCU : 26|1@0+ (1,0) [0|1] "" Vector__XXX
 SG_ UDB27FZCU : 27|1@0+ (1,0) [0|1] "" Vector__XXX
 SG_ UDB28FZCU : 28|1@0+ (1,0) [0|1] "" Vector__XXX
 SG_ UDB29FZCU : 29|1@0+ (1,0) [0|1] "" Vector__XXX
 SG_ UDB30FZCU : 30|1@0+ (1,0) [0|1] "" Vector__XXX
 SG_ UDB31FZCU : 31|1@0+ (1,0) [0|1] "" Vector__XXX
 SG_ UDB32FZCU : 32|1@0+ (1,0) [0|1] "" Vector__XXX
 SG_ UDB33FZCU : 33|1@0+ (1,0) [0|1] "" Vector__XXX
 SG_ UDB34FZCU : 34|1@0+ (1,0) [0|1] "" Vector__XXX
 SG_ UDB35FZCU : 35|1@0+ (1,0) [0|1] "" Vector__XXX
 SG_ UDB36FZCU : 36|1@0+ (1,0) [0|1] "" Vector__XXX
 SG_ UDB37FZCU : 37|1@0+ (1,0) [0|1] "" Vector__XXX
 SG_ UDB38FZCU : 38|1@0+ (1,0) [0|1] "" Vector__XXX
 SG_ UDB39FZCU : 39|1@0+ (1,0) [0|1] "" Vector__XXX
 SG_ UDB40FZCU : 40|1@0+ (1,0) [0|1] "" Vector__XXX
 SG_ UDB41FZCU : 41|1@0+ (1,0) [0|1] "" Vector__XXX
 SG_ UDB42FZCU : 42|1@0+ (1,0) [0|1] "" Vector__XXX
 SG_ UDB43FZCU : 43|1@0+ (1,0) [0|1] "" Vector__XXX
 SG_ UDB44FZCU : 44|1@0+ (1,0) [0|1] "" Vector__XXX
 SG_ UDB45FZCU : 45|1@0+ (1,0) [0|1] "" Vector__XXX
 SG_ UDB46FZCU : 46|1@0+ (1,0) [0|1] "" Vector__XXX
 SG_ UDB47FZCU : 47|1@0+ (1,0) [0|1] "" Vector__XXX

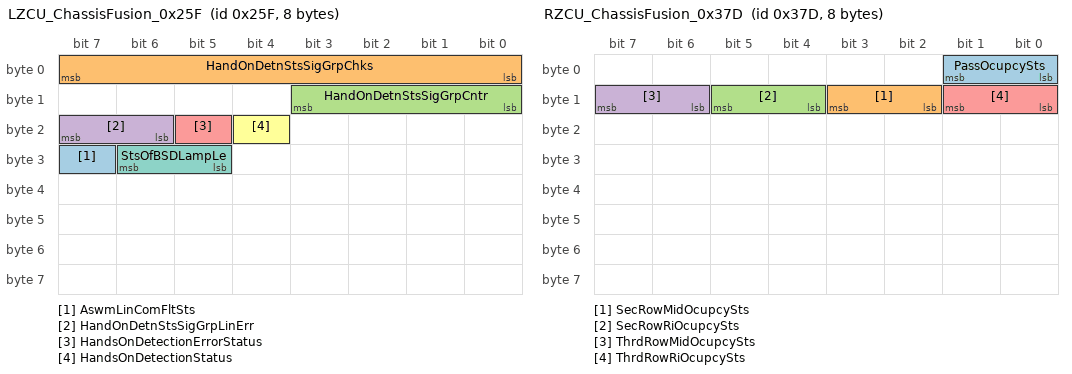
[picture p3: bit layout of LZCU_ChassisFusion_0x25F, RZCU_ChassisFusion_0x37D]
BO_ 607 LZCU_ChassisFusion_0x25F: 8 XCD
 SG_ AswmLinComFltSts : 31|1@0+ (1,0) [0|1] ""  ADD
 SG_ HandOnDetnStsSigGrpChks : 7|8@0+ (1,0) [0|255] ""  ADD
 SG_ HandOnDetnStsSigGrpCntr : 11|4@0+ (1,0) [0|15] ""  ADD
 SG_ HandOnDetnStsSigGrpLinErr : 23|2@0+ (1,0) [0|3] ""  ADD
 SG_ HandsOnDetectionErrorStatus : 21|1@0+ (1,0) [0|1] ""  ADD
 SG_ HandsOnDetectionStatus : 20|1@0+ (1,0) [0|1] ""  ADD
 SG_ StsOfBSDLampLe : 30|2@0+ (1,0) [0|3] ""  ADD

BO_ 892 LZCU_ChassisFusion_0x37C: 32 XCD
 SG_ DrvrOcupcySts : 23|2@0+ (1,0) [0|3] ""  ADD,BCS,SCU
 SG_ DrvrOcupcyStsGroupChks : 7|8@0+ (1,0) [0|255] ""  ADD,BCS,SCU
 SG_ DrvrOcupcyStsGroupCntr : 11|4@0+ (1,0) [0|15] ""  ADD,BCS,SCU
 SG_ HfaftActPosn : 95|16@0+ (1,0) [0|65535] "" Vector__XXX
 SG_ HfaftAdrSts : 47|8@0+ (1,0) [0|255] "" Vector__XXX
 SG_ HfaftApplyHldCurSts : 55|2@0+ (1,0) [0|3] "" Vector__XXX
 SG_ HfaftElecDfctErr : 53|2@0+ (1,0) [0|3] "" Vector__XXX
 SG_ HfaftEmgyRunOccurred : 51|2@0+ (1,0) [0|3] "" Vector__XXX
 SG_ HfaftEmgyRunPosnSts : 49|2@0+ (1,0) [0|3] "" Vector__XXX
 SG_ HfaftEmgyRunRelsSts : 63|2@0+ (1,0) [0|3] "" Vector__XXX
 SG_ HfaftLinComFltSts : 61|2@0+ (1,0) [0|3] "" Vector__XXX
 SG_ HfaftMoveDir : 59|2@0+ (1,0) [0|3] "" Vector__XXX
 SG_ HfaftOverTempErr : 57|2@0+ (1,0) [0|3] "" Vector__XXX
 SG_ HfaftPosnSpcnSts : 71|2@0+ (1,0) [0|3] "" Vector__XXX
 SG_ HfaftRespErr : 69|1@0+ (1,0) [0|1] "" Vector__XXX
 SG_ HfaftRotDirSts : 68|2@0+ (1,0) [0|3] "" Vector__XXX
 SG_ HfaftRst : 66|2@0+ (1,0) [0|3] "" Vector__XXX
 SG_ HfaftSelfHldTq : 79|2@0+ (1,0) [0|3] "" Vector__XXX
 SG_ HfaftSpclFcns : 77|2@0+ (1,0) [0|3] "" Vector__XXX
 SG_ HfaftSpdSts : 75|4@0+ (1,0) [0|15] "" Vector__XXX
 SG_ HfaftSplyVoltErr : 87|2@0+ (1,0) [0|3] "" Vector__XXX
 SG_ HfaftStallDetnRelsSts : 85|2@0+ (1,0) [0|3] "" Vector__XXX
 SG_ HfaftStallOccurred : 83|2@0+ (1,0) [0|3] "" Vector__XXX
 SG_ HfaftStopModSts : 81|2@0+ (1,0) [0|3] "" Vector__XXX
 SG_ SecRowLeOcupcySts : 31|2@0+ (1,0) [0|3] "" Vector__XXX

BO_ 616 RZCU_ChassisFusion_0x268: 24 XCD
 SG_ RlsAutWinWipgSpdCmd : 23|3@0+ (1,0) [0|7] ""  ADD
 SG_ RlsAutWinWipgSpdCmdSigGrpChks : 7|8@0+ (1,0) [0|255] ""  ADD
 SG_ RlsAutWinWipgSpdCmdSigGrpCntr : 11|4@0+ (1,0) [0|15] ""  ADD
 SG_ RlsFwdLiSnsrVal : 47|15@0+ (6,0) [0|196602] ""  ADD
 SG_ RlsFwdLiSnsrValUnit : 87|2@0+ (1,0) [0|3] ""  ADD
 SG_ RlsHudSnsrVal : 63|15@0+ (6,0) [0|196602] ""  ADD
 SG_ RlsHudSnsrValUnit : 85|2@0+ (1,0) [0|3] ""  ADD
 SG_ RlsIRVal : 79|8@0+ (400,0) [0|101600] ""  ADD
 SG_ RlsLiSig1GrpChks : 31|8@0+ (1,0) [0|255] ""  ADD
 SG_ RlsLiSig1GrpCntr : 35|4@0+ (1,0) [0|15] ""  ADD
 SG_ RlsLiSig2GrpChks : 95|8@0+ (1,0) [0|255] ""  ADD
 SG_ RlsLiSig2GrpCntr : 99|4@0+ (1,0) [0|15] ""  ADD
 SG_ RlsLiSigGrpLinErr : 111|2@0+ (1,0) [0|3] ""  ADD
 SG_ RlsLiSnsrFwdFlt : 83|1@0+ (1,0) [0|1] ""  ADD
 SG_ RlsLiSnsrIRFlt : 82|1@0+ (1,0) [0|1] ""  ADD
 SG_ RlsLiSnsrTopFlt : 81|1@0+ (1,0) [0|1] ""  ADD
 SG_ RlsLiSwtReq : 109|2@0+ (1,0) [0|3] ""  ADD
 SG_ RlsOutdBriSts : 107|3@0+ (1,0) [0|7] ""  ADD
 SG_ RlsSts : 135|3@0+ (1,0) [0|7] ""  ADD
 SG_ RlsTopLiSnsrVal : 119|15@0+ (20,0) [0|655340] ""  ADD
 SG_ RlsTopLiSnsrValUnit : 132|2@0+ (1,0) [0|3] ""  ADD
 SG_ StsOfBSDLampRi : 149|2@0+ (1,0) [0|3] ""  ADD

BO_ 893 RZCU_ChassisFusion_0x37D: 8 XCD
 SG_ PassOcupcySts : 1|2@0+ (1,0) [0|3] ""  ADD
 SG_ SecRowMidOcupcySts : 11|2@0+ (1,0) [0|3] "" Vector__XXX
 SG_ SecRowRiOcupcySts : 13|2@0+ (1,0) [0|3] "" Vector__XXX
 SG_ ThrdRowMidOcupcySts : 15|2@0+ (1,0) [0|3] "" Vector__XXX
 SG_ ThrdRowRiOcupcySts : 9|2@0+ (1,0) [0|3] "" Vector__XXX

BO_ 342 SCU_ChassisFusion_0x156: 32 SCU
 SG_ AirPResv : 71|16@0+ (1,0) [0|3000] "KPa"  XCD
 SG_ AirPResvSts : 104|1@0+ (1,0) [0|1] ""  XCD
 SG_ ASCFltSts : 207|2@0+ (1,0) [0|3] ""  ADD,BCS,XCD
 SG_ BatDamprModAllwd : 87|1@0+ (1,0) [0|1] ""  XCD
 SG_ CDCFltSts : 205|2@0+ (1,0) [0|3] ""  ADD,BCS,XCD
 SG_ CmftDamprModAllwd : 141|1@0+ (1,0) [0|1] ""  XCD
 SG_ CurDampgCtrlMod : 124|2@0+ (1,0) [0|3] ""  ADD,XCD
 SG_ EasyEntryEnaSts : 131|1@0+ (1,0) [0|1] ""  XCD
 SG_ EasyEntryHeiSetSts : 127|3@0+ (1,0) [0|7] ""  XCD
 SG_ EasyEntrySts : 130|1@0+ (1,0) [0|1] ""  XCD
 SG_ EasyLoadEnaSts : 129|1@0+ (1,0) [0|1] ""  XCD
 SG_ EasyLoadgFuncCouplAct : 143|1@0+ (1,0) [0|1] ""  XCD
 SG_ EasyLoadSts : 128|1@0+ (1,0) [0|1] ""  XCD
 SG_ ESPEnaReq : 203|1@0+ (1,0) [0|1] ""  ADD,BCS,XCD
 SG_ FrntLeAirSprgP : 7|16@0+ (1,0) [0|3000] "KPa"  XCD
 SG_ FrntLeAirSprgPSts : 115|1@0+ (1,0) [0|1] ""  XCD
 SG_ FrntRiAirSprgP : 23|16@0+ (1,0) [0|3000] "KPa"  XCD
 SG_ FrntRiAirSprgPSts : 116|1@0+ (1,0) [0|1] ""  XCD
 SG_ HiLvlMod1Allwd : 85|1@0+ (1,0) [0|1] ""  XCD
 SG_ HiLvlMod1RestrcnRsn : 151|4@0+ (1,0) [0|15] ""  XCD
 SG_ HiLvlMod2Allwd : 86|1@0+ (1,0) [0|1] ""  XCD
 SG_ HiLvlMod2RestrcnRsn : 147|4@0+ (1,0) [0|15] ""  XCD
 SG_ JackModEnaSts : 114|1@0+ (1,0) [0|1] ""  XCD
 SG_ JackModSts : 113|1@0+ (1,0) [0|1] ""  ADD,XCD
 SG_ LoLvlMod1Allwd : 83|1@0+ (1,0) [0|1] ""  XCD
 SG_ LoLvlMod1RestrcnRsn : 159|4@0+ (1,0) [0|15] ""  XCD
 SG_ LoLvlMod2Allwd : 82|1@0+ (1,0) [0|1] ""  XCD
 SG_ LoLvlMod2RestrcnRsn : 155|4@0+ (1,0) [0|15] ""  XCD
 SG_ LvlAdjmtSts : 91|4@0+ (1,0) [0|15] ""  ADD,XCD
 SG_ LvlCtrlCalCompl : 160|1@0+ (1,0) [0|1] ""  XCD
 SG_ LvlModAct : 135|3@0+ (1,0) [0|7] ""  ADD,XCD
 SG_ NormDamprModAllwd : 142|1@0+ (1,0) [0|1] ""  XCD
 SG_ NormLvlModAllwd : 84|1@0+ (1,0) [0|1] ""  XCD
 SG_ NormLvlModRestrcnRsn : 103|4@0+ (1,0) [0|15] ""  XCD
 SG_ ReLeAirSprgP : 39|16@0+ (1,0) [0|3000] "KPa"  XCD
 SG_ ReLeAirSprgPSts : 117|1@0+ (1,0) [0|1] ""  XCD
 SG_ ReRiAirSprgP : 55|16@0+ (1,0) [0|3000] "KPa"  XCD
 SG_ ReRiAirSprgPSts : 118|1@0+ (1,0) [0|1] ""  XCD
 SG_ SCUExtmHeiSts : 202|2@0+ (1,0) [0|3] ""  ADD,BCS,XCD
 SG_ SCULimSpdTqReq : 215|1@0+ (1,0) [0|1] ""  ADD,BCS,XCD
 SG_ SCUSelfAwkLvlAdjmt : 92|1@0+ (1,0) [0|1] ""  XCD
 SG_ SCUWarnLampReq : 214|2@0+ (1,0) [0|3] ""  ADD,BCS,XCD
 SG_ SCUWarnMsgASC : 212|3@0+ (1,0) [0|7] ""  ADD,BCS,XCD
 SG_ SCUWarnMsgCDC : 209|2@0+ (1,0) [0|3] ""  ADD,BCS,XCD
 SG_ SCUWarnSigGrpChks : 191|8@0+ (1,0) [0|255] ""  ADD,BCS,XCD
 SG_ SCUWarnSigGrpCntr : 195|4@0+ (1,0) [0|15] ""  ADD,BCS,XCD
 SG_ SprgRateSts : 81|2@0+ (1,0) [0|3] ""  XCD
 SG_ SprgRateStsVld : 96|1@0+ (1,0) [0|1] ""  XCD
 SG_ SptDamprModAllwd : 140|1@0+ (1,0) [0|1] ""  XCD
 SG_ StdLvlSpdSwtSts : 165|1@0+ (1,0) [0|1] ""  XCD
 SG_ StdLvlSpdSwtVld : 166|1@0+ (1,0) [0|1] ""  XCD
 SG_ SuspHeiAdjmtReqSrc : 99|3@0+ (1,0) [0|7] ""  XCD
 SG_ SuspHeiSetSts : 139|3@0+ (1,0) [0|7] ""  XCD
 SG_ TarLvlChg : 95|3@0+ (1,0) [0|7] ""  XCD

BO_ 359 SCU_ChassisFusion_0x167: 32 SCU
 SG_ ASCFltSts2 : 207|2@0+ (1,0) [0|3] ""  FZCU
 SG_ BatDamprModAllwd2 : 87|1@0+ (1,0) [0|1] ""  FZCU
 SG_ CDCFltSts2 : 205|2@0+ (1,0) [0|3] ""  FZCU
 SG_ CmftDamprModAllwd2 : 141|1@0+ (1,0) [0|1] ""  FZCU
 SG_ CurDampgCtrlMod2 : 124|2@0+ (1,0) [0|3] ""  FZCU
 SG_ ESPEnaReq2 : 203|1@0+ (1,0) [0|1] ""  FZCU
 SG_ LvlCtrlCalCompl2 : 160|1@0+ (1,0) [0|1] ""  FZCU
 SG_ LvlModAct2 : 135|3@0+ (1,0) [0|7] ""  FZCU
 SG_ NormDamprModAllwd2 : 142|1@0+ (1,0) [0|1] ""  FZCU
 SG_ SCUActvAwakeReq : 119|1@0+ (1,0) [0|1] ""  FZCU
 SG_ SCUExtmHeiSts2 : 202|2@0+ (1,0) [0|3] ""  FZCU
 SG_ SCULimSpdTqReq2 : 215|1@0+ (1,0) [0|1] ""  FZCU
 SG_ SCUWarnLampReq2 : 214|2@0+ (1,0) [0|3] ""  FZCU
 SG_ SCUWarnMsgASC2 : 212|3@0+ (1,0) [0|7] ""  FZCU
 SG_ SCUWarnMsgCDC2 : 209|2@0+ (1,0) [0|3] ""  FZCU
 SG_ SCUWarnSigGrp2Chks : 191|8@0+ (1,0) [0|255] ""  FZCU
 SG_ SCUWarnSigGrp2Cntr : 195|4@0+ (1,0) [0|15] ""  FZCU
 SG_ SprgRateSts2 : 81|2@0+ (1,0) [0|3] ""  FZCU
 SG_ SprgRateStsVld2 : 96|1@0+ (1,0) [0|1] ""  FZCU
 SG_ SptDamprModAllwd2 : 140|1@0+ (1,0) [0|1] ""  FZCU

BO_ 699 SCU_ChassisFusion_0x2BB: 8 SCU
 SG_ SCUBFaultInfoFlag : 15|1@0+ (1,0) [0|1] ""  XCD

BO_ 1000 SCU_ChassisFusion_0x3E8: 64 SCU
 SG_ AccumIntkAirM : 7|12@0+ (1,0) [0|4095] "barL"  XCD
 SG_ AccumNrFillg : 39|10@0+ (1,0) [0|1023] ""  XCD
 SG_ AccumWtrIntkWght : 31|8@0+ (0.1,0) [0|25.5] "g"  XCD
 SG_ AsuCrtlDataClctReq : 463|1@0+ (1,0) [0|1] ""  XCD
 SG_ AsuCrtlDataClctSts : 439|3@0+ (1,0) [0|7] ""  XCD
 SG_ ASULftDataClctReq : 462|1@0+ (1,0) [0|1] ""  XCD
 SG_ CmpOperModCntrDwnLvlg : 335|16@0+ (1,0) [0|65535] ""  XCD
 SG_ CmpOperModCntrOvfDwnLvlg : 367|14@0+ (1,0) [0|16383] ""  XCD
 SG_ CmpOperModCntrOvfUpLvlg : 383|14@0+ (1,0) [0|16383] ""  XCD
 SG_ CmpOperModCntrResvFillg : 399|11@0+ (1,0) [0|2047] ""  XCD
 SG_ CmpOperModCntrUpLvlg : 351|16@0+ (1,0) [0|65535] ""  XCD
 SG_ CmpRtCntrDwnLvlg : 287|9@0+ (1,0) [0|511] "h"  XCD
 SG_ CmpRtCntrTot : 289|10@0+ (1,0) [0|1023] "h"  XCD
 SG_ CmpRtCntrTotResvFillg : 311|9@0+ (1,0) [0|511] "h"  XCD
 SG_ CmpRtCntrUpLvlg : 312|9@0+ (1,0) [0|511] "h"  XCD
 SG_ CtrlActnFbAvFL : 436|1@0+ (1,0) [0|1] ""  XCD
 SG_ CtrlActnFbAvFR : 435|1@0+ (1,0) [0|1] ""  XCD
 SG_ CtrlActnFbAvRL : 434|1@0+ (1,0) [0|1] ""  XCD
 SG_ CtrlActnFbAvRR : 433|1@0+ (1,0) [0|1] ""  XCD
 SG_ CtrlActnFbEv : 432|1@0+ (1,0) [0|1] ""  XCD
 SG_ CtrlActnFbMot : 455|1@0+ (1,0) [0|1] ""  XCD
 SG_ CtrlActnFbSv1 : 454|1@0+ (1,0) [0|1] ""  XCD
 SG_ CtrlActnFbSv2 : 453|1@0+ (1,0) [0|1] ""  XCD
 SG_ CtrlActnFbSv3 : 452|1@0+ (1,0) [0|1] ""  XCD
 SG_ CtrlActnFbSv4 : 451|1@0+ (1,0) [0|1] ""  XCD
 SG_ NrActvnAv1Vlv : 103|20@0+ (1,0) [0|1048575] ""  XCD
 SG_ NrActvnAv2Vlv : 115|20@0+ (1,0) [0|1048575] ""  XCD
 SG_ NrActvnAv3Vlv : 143|20@0+ (1,0) [0|1048575] ""  XCD
 SG_ NrActvnAv4Vlv : 155|20@0+ (1,0) [0|1048575] ""  XCD
 SG_ NrActvnCmp : 415|18@0+ (1,0) [0|262143] ""  XCD
 SG_ NrActvnEvVlv : 183|20@0+ (1,0) [0|1048575] ""  XCD
 SG_ NrActvnSv1Vlv : 195|20@0+ (1,0) [0|1048575] ""  XCD
 SG_ NrActvnSv2Vlv : 223|20@0+ (1,0) [0|1048575] ""  XCD
 SG_ NrActvnSv3Vlv : 235|20@0+ (1,0) [0|1048575] ""  XCD
 SG_ NrActvnSv4Vlv : 263|20@0+ (1,0) [0|1048575] ""  XCD
 SG_ PrsntAirMData : 41|11@0+ (0.1,0) [0|204.7] "barL"  XCD
 SG_ PrsntLoadData : 11|12@0+ (1,0) [0|4095] "kg"  XCD
 SG_ ScuAcMode : 447|8@0+ (1,0) [0|255] ""  XCD
 SG_ SuspAirMDataClctReq : 461|1@0+ (1,0) [0|1] ""  XCD
 SG_ SuspAirMDataClctSts : 45|4@0+ (1,0) [0|15] ""  XCD
 SG_ SuspClctCurAmbHum : 62|7@0+ (1,0) [0|100] "%"  XCD
 SG_ SuspClctCurAmbPSOA : 79|7@0+ (1,0) [0|120] "kPa"  XCD
 SG_ SuspClctCurAmbT : 71|8@0+ (1,-80) [-80|99] "°C"  XCD
 SG_ SuspClctCurAmbTSOA : 87|8@0+ (1,-80) [-80|99] "°C"  XCD
 SG_ SuspWthrFcstAuthnSts : 72|1@0+ (1,0) [0|1] ""  XCD

BO_ 1446 SCU_ChassisFusion_0x5A6: 32 SCU
 SG_ SCUEvntTrackFrame1Byte0to3 : 7|32@0+ (1,0) [0|4294967295] ""  XCD
 SG_ SCUEvntTrackFrame1Byte12to15 : 103|32@0+ (1,0) [0|4294967295] ""  XCD
 SG_ SCUEvntTrackFrame1Byte16to19 : 135|32@0+ (1,0) [0|4294967295] ""  XCD
 SG_ SCUEvntTrackFrame1Byte20to23 : 167|32@0+ (1,0) [0|4294967295] ""  XCD
 SG_ SCUEvntTrackFrame1Byte24to27 : 199|32@0+ (1,0) [0|4294967295] ""  XCD
 SG_ SCUEvntTrackFrame1Byte28to31 : 231|32@0+ (1,0) [0|4294967295] ""  XCD
 SG_ SCUEvntTrackFrame1Byte4to7 : 39|32@0+ (1,0) [0|4294967295] ""  XCD
 SG_ SCUEvntTrackFrame1Byte8to11 : 71|32@0+ (1,0) [0|4294967295] ""  XCD

BO_ 156 SCU_ChassisFusion_0x9C: 32 SCU
 SG_ RtcWake1AjustStsFL : 0|1@0+ (1,0) [0|1] ""  XCD
 SG_ RtcWake1AjustStsFR : 1|1@0+ (1,0) [0|1] ""  XCD
 SG_ RtcWake1AjustStsRL : 2|1@0+ (1,0) [0|1] ""  XCD
 SG_ RtcWake1AjustStsRR : 3|1@0+ (1,0) [0|1] ""  XCD
 SG_ RtcWake1DateTimeDay : 12|5@0+ (1,0) [0|31] ""  XCD
 SG_ RtcWake1DateTimeHr : 20|5@0+ (1,0) [0|23] ""  XCD
 SG_ RtcWake1DateTimeMins : 29|6@0+ (1,0) [0|59] ""  XCD
 SG_ RtcWake1DateTimeMth : 35|4@0+ (1,0) [0|12] ""  XCD
 SG_ RtcWake1DateTimeYr : 47|8@0+ (1,2000) [2000|2254] ""  XCD
 SG_ RtcWake1HeightFL : 55|8@0+ (1,-127) [-127|128] "mm"  XCD
 SG_ RtcWake1HeightFR : 63|8@0+ (1,-127) [-127|128] "mm"  XCD
 SG_ RtcWake1HeightRL : 71|8@0+ (1,-127) [-127|128] "mm"  XCD
 SG_ RtcWake1HeightRR : 79|8@0+ (1,-127) [-127|128] "mm"  XCD
 SG_ RtcWake1Valid : 36|1@0+ (1,0) [0|1] ""  XCD
 SG_ RtcWake2AjustStsFL : 37|1@0+ (1,0) [0|1] ""  XCD
 SG_ RtcWake2AjustStsFR : 80|1@0+ (1,0) [0|1] ""  XCD
 SG_ RtcWake2AjustStsRL : 81|1@0+ (1,0) [0|1] ""  XCD
 SG_ RtcWake2AjustStsRR : 82|1@0+ (1,0) [0|1] ""  XCD
 SG_ RtcWake2DateTimeDay : 87|5@0+ (1,0) [0|31] ""  XCD
 SG_ RtcWake2DateTimeHr : 92|5@0+ (1,0) [0|23] ""  XCD
 SG_ RtcWake2DateTimeMins : 101|6@0+ (1,0) [0|59] ""  XCD
 SG_ RtcWake2DateTimeMth : 107|4@0+ (1,0) [0|12] ""  XCD
 SG_ RtcWake2DateTimeYr : 119|8@0+ (1,2000) [2000|2254] ""  XCD
 SG_ RtcWake2HeightFL : 127|8@0+ (1,-127) [-127|128] "mm"  XCD
 SG_ RtcWake2HeightFR : 135|8@0+ (1,-127) [-127|128] "mm"  XCD
 SG_ RtcWake2HeightRL : 143|8@0+ (1,-127) [-127|128] "mm"  XCD
 SG_ RtcWake2HeightRR : 151|8@0+ (1,-127) [-127|128] "mm"  XCD
 SG_ RtcWake2Valid : 152|1@0+ (1,0) [0|1] ""  XCD
 SG_ RtcWake3AjustStsFL : 153|1@0+ (1,0) [0|1] ""  XCD
 SG_ RtcWake3AjustStsFR : 154|1@0+ (1,0) [0|1] ""  XCD
 SG_ RtcWake3AjustStsRL : 160|1@0+ (1,0) [0|1] ""  XCD
 SG_ RtcWake3AjustStsRR : 161|1@0+ (1,0) [0|1] ""  XCD
 SG_ RtcWake3DateTimeDay : 159|5@0+ (1,0) [0|31] ""  XCD
 SG_ RtcWake3DateTimeHr : 167|5@0+ (1,0) [0|23] ""  XCD
 SG_ RtcWake3DateTimeMins : 213|6@0+ (1,0) [0|59] ""  XCD
 SG_ RtcWake3DateTimeMth : 219|4@0+ (1,0) [0|12] ""  XCD
 SG_ RtcWake3DateTimeYr : 175|8@0+ (1,2000) [2000|2254] ""  XCD
 SG_ RtcWake3HeightFL : 183|8@0+ (1,-127) [-127|128] "mm"  XCD
 SG_ RtcWake3HeightFR : 191|8@0+ (1,-127) [-127|128] "mm"  XCD
 SG_ RtcWake3HeightRL : 199|8@0+ (1,-127) [-127|128] "mm"  XCD
 SG_ RtcWake3HeightRR : 207|8@0+ (1,-127) [-127|128] "mm"  XCD
 SG_ RtcWake3Valid : 162|1@0+ (1,0) [0|1] ""  XCD

BO_ 157 SCU_ChassisFusion_0x9D: 16 SCU
 SG_ ScuIGOffDateTimeDay : 4|5@0+ (1,0) [0|31] ""  XCD
 SG_ ScuIGOffDateTimeHr : 12|5@0+ (1,0) [0|23] ""  XCD
 SG_ ScuIGOffDateTimeMins : 21|6@0+ (1,0) [0|59] ""  XCD
 SG_ ScuIGOffDateTimeMth : 28|4@0+ (1,0) [0|12] ""  XCD
 SG_ ScuIGOffDateTimeYr : 39|8@0+ (1,2000) [2000|2254] ""  XCD
 SG_ ScuIGOffTargetFront : 47|8@0+ (1,-127) [-127|128] "mm"  XCD
 SG_ ScuIGOffTargetRear : 55|8@0+ (1,-127) [-127|128] "mm"  XCD
 SG_ ScuIGOffTime : 63|18@0+ (0.125,0) [0|32767] "min"  XCD

BO_ 182 SCU_ChassisFusion_0xB6: 32 SCU
 SG_ AccrSnsrAzFrntLe : 87|10@0+ (0.01,-1.6) [-1.6|1.6] ""  XCD
 SG_ AccrSnsrAzFrntRi : 103|10@0+ (0.01,-1.6) [-1.6|1.6] ""  XCD
 SG_ AccrSnsrAzRe : 119|10@0+ (0.01,-1.6) [-1.6|1.6] ""  XCD
 SG_ BodyVertVFL : 175|13@0+ (0.001,-4) [-4|4] "mps"  XCD
 SG_ BodyVertVFR : 191|13@0+ (0.001,-4) [-4|4] "mps"  XCD
 SG_ BodyVertVRL : 207|13@0+ (0.001,-4) [-4|4] "mps"  XCD
 SG_ BodyVertVRR : 223|13@0+ (0.001,-4) [-4|4] "mps"  XCD
 SG_ CurHeiSigGrpChks : 7|8@0+ (1,0) [0|255] ""  XCD
 SG_ CurHeiSigGrpCntr : 11|4@0+ (1,0) [0|15] ""  XCD
 SG_ DamprCurFrntLe : 135|8@0+ (0.01,0) [0|2] "A"  XCD
 SG_ DamprCurFrntRi : 143|8@0+ (0.01,0) [0|2] "A"  XCD
 SG_ DamprCurReLe : 151|8@0+ (0.01,0) [0|2] "A"  XCD
 SG_ DamprCurReqFL : 159|8@0+ (0.01,0) [0|2] "A"  XCD
 SG_ DamprCurReqFR : 167|8@0+ (0.01,0) [0|2] "A"  XCD
 SG_ DamprCurReqRL : 239|8@0+ (0.01,0) [0|2] "A"  XCD
 SG_ DamprCurReqRR : 247|8@0+ (0.01,0) [0|2] ""  XCD
 SG_ DamprCurReRi : 255|8@0+ (0.01,0) [0|2] "A"  XCD
 SG_ FrntLeCurHei : 23|8@0+ (1,-127) [-127|128] "mm"  XCD
 SG_ FrntLeCurHeiSts : 15|1@0+ (1,0) [0|1] ""  XCD
 SG_ FrntRiCurHei : 39|8@0+ (1,-127) [-127|128] "mm"  XCD
 SG_ FrntRiCurHeiSts : 13|1@0+ (1,0) [0|1] ""  XCD
 SG_ ReLeCurHei : 31|8@0+ (1,-127) [-127|128] "mm"  XCD
 SG_ ReLeCurHeiSts : 14|1@0+ (1,0) [0|1] ""  XCD
 SG_ ReRiCurHei : 47|8@0+ (1,-127) [-127|128] "mm"  XCD
 SG_ ReRiCurHeiSts : 12|1@0+ (1,0) [0|1] ""  XCD
 SG_ SCUAccrSnsrChks : 71|8@0+ (1,0) [0|255] ""  XCD
 SG_ SCUAccrSnsrCntr : 75|4@0+ (1,0) [0|15] ""  XCD

BO_ 192 SCU_ChassisFusion_0xC0: 32 SCU
 SG_ BodyVertVFL2 : 175|13@0+ (0.001,-4) [-4|4] "mps"  FZCU
 SG_ BodyVertVFR2 : 191|13@0+ (0.001,-4) [-4|4] "mps"  FZCU
 SG_ BodyVertVRL2 : 207|13@0+ (0.001,-4) [-4|4] "mps"  FZCU
 SG_ BodyVertVRR2 : 223|13@0+ (0.001,-4) [-4|4] "mps"  FZCU
 SG_ CurHeiSigGrp2Chks : 7|8@0+ (1,0) [0|255] ""  FZCU
 SG_ CurHeiSigGrp2Cntr : 11|4@0+ (1,0) [0|15] ""  FZCU
 SG_ FrntLeCurHei2 : 23|8@0+ (1,-127) [-127|128] "mm"  FZCU
 SG_ FrntLeCurHeiSts2 : 15|1@0+ (1,0) [0|1] ""  FZCU
 SG_ FrntRiCurHei2 : 39|8@0+ (1,-127) [-127|128] "mm"  FZCU
 SG_ FrntRiCurHeiSts2 : 13|1@0+ (1,0) [0|1] ""  FZCU
 SG_ ReLeCurHei2 : 31|8@0+ (1,-127) [-127|128] "mm"  FZCU
 SG_ ReLeCurHeiSts2 : 14|1@0+ (1,0) [0|1] ""  FZCU
 SG_ ReRiCurHei2 : 47|8@0+ (1,-127) [-127|128] "mm"  FZCU
 SG_ ReRiCurHeiSts2 : 12|1@0+ (1,0) [0|1] ""  FZCU

BO_ 1323 SCUChassisFusionNMFr: 8 SCU
 SG_ NMKeepAwkRsnSCUB : 48|9@0+ (1,0) [0|511] "" Vector__XXX
 SG_ SCUChassisCanfdActiveWakeup : 12|1@0+ (1,0) [0|1] "" Vector__XXX
 SG_ SCUChassisCanfdNodeAddress : 7|8@0+ (1,0) [0|255] "" Vector__XXX
 SG_ SCUChassisCanfdRepeatMsgReq : 8|1@0+ (1,0) [0|1] "" Vector__XXX
 SG_ SCUChassisCanfdRepeatMsgSt : 16|1@0+ (1,0) [0|1] "" Vector__XXX
 SG_ UDB17SCU : 17|1@0+ (1,0) [0|1] "" Vector__XXX
 SG_ UDB18SCU : 18|1@0+ (1,0) [0|1] "" Vector__XXX
 SG_ UDB19SCU : 19|1@0+ (1,0) [0|1] "" Vector__XXX
 SG_ UDB20SCU : 20|1@0+ (1,0) [0|1] "" Vector__XXX
 SG_ UDB21SCU : 21|1@0+ (1,0) [0|1] "" Vector__XXX
 SG_ UDB22SCU : 22|1@0+ (1,0) [0|1] "" Vector__XXX
 SG_ UDB23SCU : 23|1@0+ (1,0) [0|1] "" Vector__XXX
 SG_ UDB24SCU : 24|1@0+ (1,0) [0|1] "" Vector__XXX
 SG_ UDB25SCU : 25|1@0+ (1,0) [0|1] "" Vector__XXX
 SG_ UDB26SCU : 26|1@0+ (1,0) [0|1] "" Vector__XXX
 SG_ UDB27SCU : 27|1@0+ (1,0) [0|1] "" Vector__XXX
 SG_ UDB28SCU : 28|1@0+ (1,0) [0|1] "" Vector__XXX
 SG_ UDB29SCU : 29|1@0+ (1,0) [0|1] "" Vector__XXX
 SG_ UDB30SCU : 30|1@0+ (1,0) [0|1] "" Vector__XXX
 SG_ UDB31SCU : 31|1@0+ (1,0) [0|1] "" Vector__XXX
 SG_ UDB32SCU : 32|1@0+ (1,0) [0|1] "" Vector__XXX
 SG_ UDB33SCU : 33|1@0+ (1,0) [0|1] "" Vector__XXX
 SG_ UDB34SCU : 34|1@0+ (1,0) [0|1] "" Vector__XXX
 SG_ UDB35SCU : 35|1@0+ (1,0) [0|1] "" Vector__XXX
 SG_ UDB36SCU : 36|1@0+ (1,0) [0|1] "" Vector__XXX
 SG_ UDB37SCU : 37|1@0+ (1,0) [0|1] "" Vector__XXX
 SG_ UDB38SCU : 38|1@0+ (1,0) [0|1] "" Vector__XXX
 SG_ UDB39SCU : 39|1@0+ (1,0) [0|1] "" Vector__XXX
 SG_ UDB40SCU : 40|1@0+ (1,0) [0|1] "" Vector__XXX
 SG_ UDB41SCU : 41|1@0+ (1,0) [0|1] "" Vector__XXX
 SG_ UDB42SCU : 42|1@0+ (1,0) [0|1] "" Vector__XXX
 SG_ UDB43SCU : 43|1@0+ (1,0) [0|1] "" Vector__XXX
 SG_ UDB44SCU : 44|1@0+ (1,0) [0|1] "" Vector__XXX
 SG_ UDB45SCU : 45|1@0+ (1,0) [0|1] "" Vector__XXX
 SG_ UDB46SCU : 46|1@0+ (1,0) [0|1] "" Vector__XXX
 SG_ UDB47SCU : 47|1@0+ (1,0) [0|1] "" Vector__XXX

BO_ 1572 SCUToXCDChassisFusionDiagRespFr: 64 SCU
 SG_ SCUToVCCDDiagResp : 7|512@0+ (1,0) [0|0] ""  XCD

BO_ 419 SWM_ChassisFusion_0x1A3: 16 SWM
 SG_ ColShiftLvrDiagc : 2|3@0+ (1,0) [0|7] ""  BCP,BCS,FZCU,XCD
 SG_ DrvrGearShiftParkReq : 105|2@0+ (1,0) [0|3] ""  BCP,BCS,FZCU,XCD
 SG_ DrvrGearShiftParkReqSigGrpChks : 95|8@0+ (1,0) [0|255] ""  BCP,BCS,FZCU,XCD
 SG_ DrvrGearShiftParkReqSigGrpCntr : 99|4@0+ (1,0) [0|15] ""  BCP,BCS,FZCU,XCD
 SG_ GearShiftPosReq : 74|3@0+ (1,0) [0|7] ""  FZCU,XCD
 SG_ GearShiftPosReqSigGrpChks : 63|8@0+ (1,0) [0|255] ""  FZCU,XCD
 SG_ GearShiftPosReqSigGrpCntr : 67|4@0+ (1,0) [0|15] ""  FZCU,XCD
 SG_ RearWiprPushSwt : 13|4@0+ (1,0) [0|15] ""  XCD
 SG_ SWMFaultInfoFlag : 7|1@0+ (1,0) [0|1] ""  XCD
 SG_ SwtHiBeam : 6|2@0+ (1,0) [0|3] ""  FZCU,XCD
 SG_ SwtIndcrRaw : 42|3@0+ (1,0) [0|7] ""  FZCU,XCD
 SG_ SwtIndcrRawSigGrpChks : 31|8@0+ (1,0) [0|255] ""  FZCU,XCD
 SG_ SwtIndcrRawSigGrpCntr : 35|4@0+ (1,0) [0|15] ""  FZCU,XCD
 SG_ WiprPushSwt : 9|2@0+ (1,0) [0|3] ""  FZCU,XCD

BO_ 1319 SWMChassisFusionNMFr: 8 SWM
 SG_ NMKeepAwkRsnSWM : 48|9@0+ (1,0) [0|511] ""  VECU
 SG_ SWMActiveWakeup : 12|1@0+ (1,0) [0|1] ""  VECU
 SG_ SWMNodeAddress : 7|8@0+ (1,0) [0|255] ""  VECU
 SG_ SWMRepeatMsgReq : 8|1@0+ (1,0) [0|1] ""  VECU
 SG_ SWMRepeatMsgSt : 16|1@0+ (1,0) [0|1] ""  VECU
 SG_ UDB17SWM : 17|1@0+ (1,0) [0|1] ""  VECU
 SG_ UDB18SWM : 18|1@0+ (1,0) [0|1] ""  VECU
 SG_ UDB19SWM : 19|1@0+ (1,0) [0|1] ""  VECU
 SG_ UDB20SWM : 20|1@0+ (1,0) [0|1] ""  VECU
 SG_ UDB21SWM : 21|1@0+ (1,0) [0|1] ""  VECU
 SG_ UDB22SWM : 22|1@0+ (1,0) [0|1] ""  VECU
 SG_ UDB23SWM : 23|1@0+ (1,0) [0|1] ""  VECU
 SG_ UDB24SWM : 24|1@0+ (1,0) [0|1] ""  VECU
 SG_ UDB25SWM : 25|1@0+ (1,0) [0|1] ""  VECU
 SG_ UDB26SWM : 26|1@0+ (1,0) [0|1] ""  VECU
 SG_ UDB27SWM : 27|1@0+ (1,0) [0|1] ""  VECU
 SG_ UDB28SWM : 28|1@0+ (1,0) [0|1] ""  VECU
 SG_ UDB29SWM : 29|1@0+ (1,0) [0|1] ""  VECU
 SG_ UDB30SWM : 30|1@0+ (1,0) [0|1] ""  VECU
 SG_ UDB31SWM : 31|1@0+ (1,0) [0|1] ""  VECU
 SG_ UDB32SWM : 32|1@0+ (1,0) [0|1] ""  VECU
 SG_ UDB33SWM : 33|1@0+ (1,0) [0|1] ""  VECU
 SG_ UDB34SWM : 34|1@0+ (1,0) [0|1] ""  VECU
 SG_ UDB35SWM : 35|1@0+ (1,0) [0|1] ""  VECU
 SG_ UDB36SWM : 36|1@0+ (1,0) [0|1] ""  VECU
 SG_ UDB37SWM : 37|1@0+ (1,0) [0|1] ""  VECU
 SG_ UDB38SWM : 38|1@0+ (1,0) [0|1] ""  VECU
 SG_ UDB39SWM : 39|1@0+ (1,0) [0|1] ""  VECU
 SG_ UDB40SWM : 40|1@0+ (1,0) [0|1] ""  VECU
 SG_ UDB41SWM : 41|1@0+ (1,0) [0|1] ""  VECU
 SG_ UDB42SWM : 42|1@0+ (1,0) [0|1] ""  VECU
 SG_ UDB43SWM : 43|1@0+ (1,0) [0|1] ""  VECU
 SG_ UDB44SWM : 44|1@0+ (1,0) [0|1] ""  VECU
 SG_ UDB45SWM : 45|1@0+ (1,0) [0|1] ""  VECU
 SG_ UDB46SWM : 46|1@0+ (1,0) [0|1] ""  VECU
 SG_ UDB47SWM : 47|1@0+ (1,0) [0|1] ""  VECU

BO_ 1573 SWMToXCDChassisFusionDiagRespFr: 64 SWM
 SG_ SWMToVCCDDiagResp : 7|512@0+ (1,0) [0|0] ""  XCD

BO_ 1761 SWMToXCDRespFr: 64 SWM
 SG_ SWMToVCCDResp : 7|512@0+ (1,0) [0|0] ""  XCD

BO_ 1286 VECUChassisFusionNMFr: 8 VECU

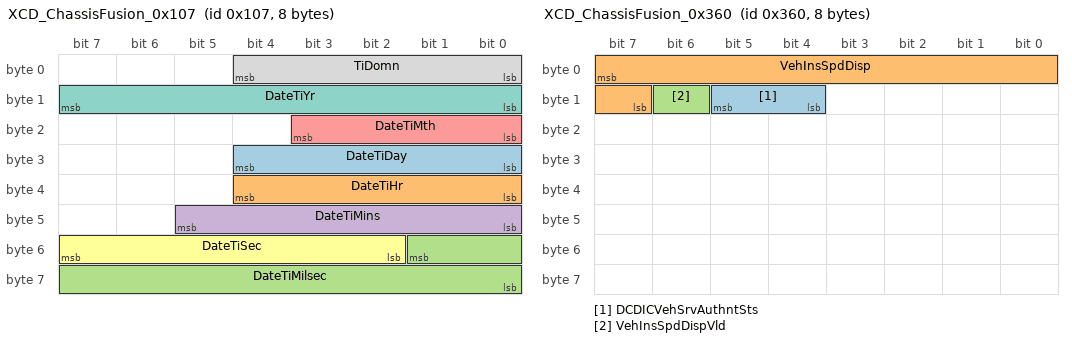
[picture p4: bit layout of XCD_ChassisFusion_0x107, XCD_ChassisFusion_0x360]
BO_ 263 XCD_ChassisFusion_0x107: 8 XCD
 SG_ DateTiDay : 28|5@0+ (1,0) [0|31] ""  SCU,SWM
 SG_ DateTiHr : 36|5@0+ (1,0) [0|24] "hour"  SCU,SWM
 SG_ DateTiMilsec : 49|10@0+ (1,0) [0|1000] "Msec"  SCU,SWM
 SG_ DateTiMins : 45|6@0+ (1,0) [0|59] "minute"  SCU,SWM
 SG_ DateTiMth : 19|4@0+ (1,0) [0|12] ""  SCU,SWM
 SG_ DateTiSec : 55|6@0+ (1,0) [0|59] "second"  SCU,SWM
 SG_ DateTiYr : 15|8@0+ (1,2000) [2000|2254] "year"  SCU,SWM
 SG_ TiDomn : 4|5@0+ (1,0) [0|31] ""  SCU

BO_ 345 XCD_ChassisFusion_0x159: 8 XCD
 SG_ DiagcExtActv : 6|1@0+ (1,0) [0|1] ""  ADD,FZCU
 SG_ profileRestoreFactoryReqSoa : 7|1@0+ (1,0) [0|1] ""  SCU

BO_ 529 XCD_ChassisFusion_0x211: 16 XCD
 SG_ SecOCMAC1 : 47|32@0+ (1,0) [0|4294967295] ""  ADD,FZCU
 SG_ SecOCMAC2 : 79|32@0+ (1,0) [0|4294967295] ""  ADD,FZCU
 SG_ SecOCMAC3 : 111|24@0+ (1,0) [0|16777215] ""  ADD,FZCU
 SG_ SecOCResetCnt : 31|16@0+ (1,0) [0|65535] ""  ADD,FZCU
 SG_ SecOCTripCnt : 7|24@0+ (1,0) [0|16777215] ""  ADD,FZCU

BO_ 549 XCD_ChassisFusion_0x225: 16 XCD
 SG_ ADSELKSwtSet : 46|2@0+ (1,0) [0|3] ""  ADD
 SG_ ADSFltQuitReqFrmDCD : 44|2@0+ (1,0) [0|3] ""  ADD
 SG_ DCDAvmCamE2ESigGrpChks : 55|8@0+ (1,0) [0|255] ""  ADD
 SG_ DCDAvmCamE2ESigGrpCntr : 59|4@0+ (1,0) [0|15] ""  ADD
 SG_ DCDAvmFrCamSts : 62|3@0+ (1,0) [0|7] ""  ADD
 SG_ DCDAvmLeCamSts : 71|3@0+ (1,0) [0|7] ""  ADD
 SG_ DCDAvmReCamSts : 68|3@0+ (1,0) [0|7] ""  ADD
 SG_ DCDAvmRiCamSts : 79|3@0+ (1,0) [0|7] ""  ADD
 SG_ DCDDisplayFailSts : 42|3@0+ (1,0) [0|7] ""  ADD
 SG_ DCDDltAllKeyCmd : 47|1@0+ (1,0) [0|1] "" Vector__XXX
 SG_ DCDDltAllKeyCmdFV : 87|16@0+ (1,0) [0|65535] ""  ADD
 SG_ DCDDltAllKeyCmdMAC : 103|32@0+ (1,0) [0|0] ""  ADD
 SG_ ExtrLiFcnSet : 23|3@0+ (1,0) [0|4] ""  VECU
 SG_ ExtrLiFcnSetSigGrpChks : 7|8@0+ (1,0) [0|255] ""  VECU
 SG_ ExtrLiFcnSetSigGrpCntr : 11|4@0+ (1,0) [0|15] ""  VECU
 SG_ WiprSpdAdjCfgSet : 20|5@0+ (1,0) [0|31] ""  VECU

BO_ 864 XCD_ChassisFusion_0x360: 8 XCD
 SG_ DCDICVehSrvAuthntSts : 13|2@0+ (1,0) [0|3] ""  SCU
 SG_ VehInsSpdDisp : 7|9@0+ (1,0) [0|504] "kph"  SCU
 SG_ VehInsSpdDispVld : 14|1@0+ (1,0) [0|1] ""  SCU

BO_ 910 XCD_ChassisFusion_0x38E: 8 XCD
 SG_ SuspHeiSetSoa : 7|4@0+ (1,0) [0|15] ""  SCU

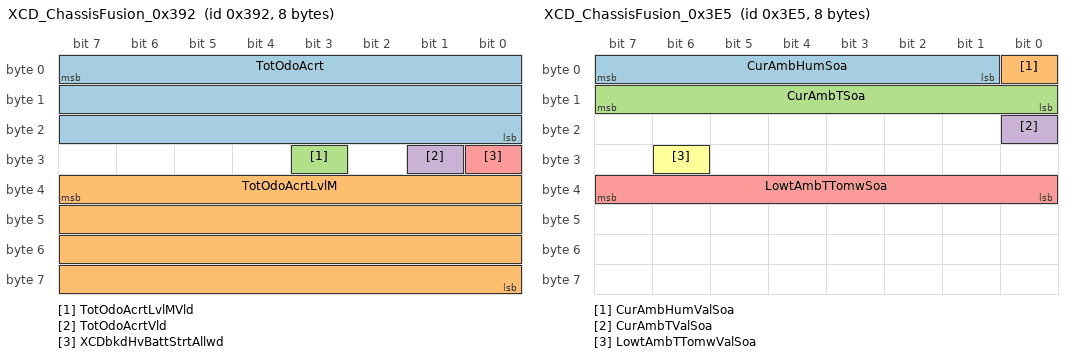
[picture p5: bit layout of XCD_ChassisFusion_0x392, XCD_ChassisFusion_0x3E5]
BO_ 914 XCD_ChassisFusion_0x392: 8 XCD
 SG_ TotOdoAcrt : 7|24@0+ (0.1,0) [0|1677721.5] "km"  SCU,SWM
 SG_ TotOdoAcrtLvlM : 39|32@0+ (1,0) [0|4294967295] "m" Vector__XXX
 SG_ TotOdoAcrtLvlMVld : 27|1@0+ (1,0) [0|1] "" Vector__XXX
 SG_ TotOdoAcrtVld : 25|1@0+ (1,0) [0|1] ""  SCU
 SG_ XCDbkdHvBattStrtAllwd : 24|1@0+ (1,0) [0|1] "" Vector__XXX

BO_ 931 XCD_ChassisFusion_0x3A3: 16 XCD
 SG_ AVHBtn : 0|1@0+ (1,0) [0|1] ""  BCS
 SG_ AVHSet : 5|2@0+ (1,0) [0|3] ""  BCS
 SG_ CSTOnOffBtn : 8|1@0+ (1,0) [0|1] ""  BCS
 SG_ CSTOnOffSet : 13|2@0+ (1,0) [0|3] ""  BCS
 SG_ DCDBattHlthMngtFcnSwt : 7|2@0+ (1,0) [0|3] "" Vector__XXX
 SG_ DCDEasyEntryHeiSet : 20|3@0+ (1,0) [0|7] ""  SCU
 SG_ DCDHDCSet : 31|2@0+ (1,0) [0|3] ""  BCS
 SG_ DCDJackModSet : 61|2@0+ (1,0) [0|3] ""  SCU
 SG_ DCDStdLvlSpdSwt : 22|2@0+ (1,0) [0|3] ""  SCU
 SG_ EasyEntryModReqBtn : 40|1@0+ (1,0) [0|1] ""  SCU
 SG_ EasyEntryModSet : 45|2@0+ (1,0) [0|3] ""  SCU
 SG_ EasyLoadgFuncCouplSet : 49|2@0+ (1,0) [0|3] ""  SCU
 SG_ EasyLoadgModReqBtn : 32|1@0+ (1,0) [0|1] ""  SCU
 SG_ EasyLoadgModSet : 37|2@0+ (1,0) [0|3] ""  SCU
 SG_ EPBSwtSet : 17|2@0+ (1,0) [0|3] ""  BCP,BCS
 SG_ ESCOffSet : 25|2@0+ (1,0) [0|3] ""  BCS
 SG_ SuspHeiSet : 59|4@0+ (1,0) [0|15] ""  SCU

BO_ 997 XCD_ChassisFusion_0x3E5: 8 XCD
 SG_ CurAmbHumSoa : 7|7@0+ (1,0) [0|100] "%"  FZCU,SCU
 SG_ CurAmbHumValSoa : 0|1@0+ (1,0) [0|1] ""  FZCU,SCU
 SG_ CurAmbTSoa : 15|8@0+ (1,-80) [-80|99] "°C"  FZCU,SCU
 SG_ CurAmbTValSoa : 16|1@0+ (1,0) [0|1] ""  FZCU,SCU
 SG_ LowtAmbTTomwSoa : 39|8@0+ (1,-80) [-80|99] "°C"  SCU
 SG_ LowtAmbTTomwValSoa : 30|1@0+ (1,0) [0|1] ""  SCU

BO_ 1023 XCD_ChassisFusion_0x3FF: 16 XCD
 SG_ VidBlkId : 71|8@0+ (1,0) [0|255] ""  ADD
 SG_ VidSignalPos1 : 79|8@0+ (1,0) [0|255] ""  ADD
 SG_ VidSignalPos2 : 87|8@0+ (1,0) [0|255] ""  ADD
 SG_ VidSignalPos3 : 95|8@0+ (1,0) [0|255] ""  ADD
 SG_ VidSignalPos4 : 103|8@0+ (1,0) [0|255] ""  ADD
 SG_ VidSignalPos5 : 111|8@0+ (1,0) [0|255] ""  ADD
 SG_ VidSignalPos6 : 119|8@0+ (1,0) [0|255] ""  ADD
 SG_ VidSignalPos7 : 127|8@0+ (1,0) [0|255] ""  ADD
 SG_ VinVINBlkID : 7|8@0+ (1,0) [0|255] ""  ADD
 SG_ VinVINSignalPos1 : 15|8@0+ (1,0) [0|255] ""  ADD
 SG_ VinVINSignalPos2 : 23|8@0+ (1,0) [0|255] ""  ADD
 SG_ VinVINSignalPos3 : 31|8@0+ (1,0) [0|255] ""  ADD
 SG_ VinVINSignalPos4 : 39|8@0+ (1,0) [0|255] ""  ADD
 SG_ VinVINSignalPos5 : 47|8@0+ (1,0) [0|255] ""  ADD
 SG_ VinVINSignalPos6 : 55|8@0+ (1,0) [0|255] ""  ADD
 SG_ VinVINSignalPos7 : 63|8@0+ (1,0) [0|255] ""  ADD

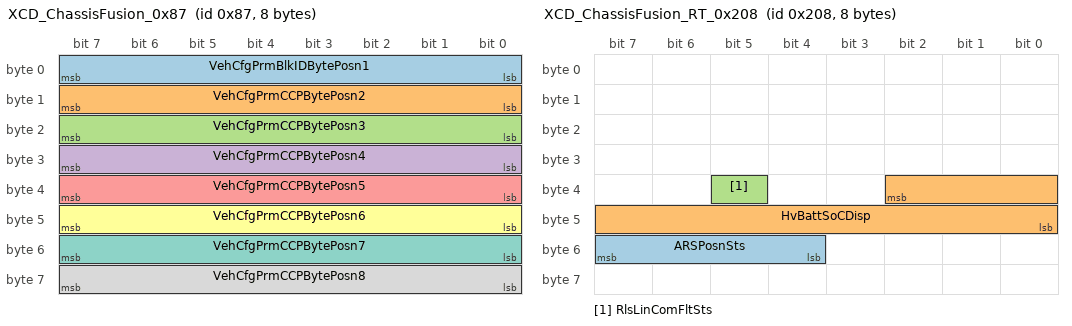
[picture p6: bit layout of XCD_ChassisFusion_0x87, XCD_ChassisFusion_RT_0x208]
BO_ 135 XCD_ChassisFusion_0x87: 8 XCD
 SG_ VehCfgPrmBlkIDBytePosn1 : 7|8@0+ (1,0) [0|150] ""  ADD,SCU,SWM
 SG_ VehCfgPrmCCPBytePosn2 : 15|8@0+ (1,0) [0|255] ""  ADD,SCU,SWM
 SG_ VehCfgPrmCCPBytePosn3 : 23|8@0+ (1,0) [0|255] ""  ADD,SCU,SWM
 SG_ VehCfgPrmCCPBytePosn4 : 31|8@0+ (1,0) [0|255] ""  ADD,SCU,SWM
 SG_ VehCfgPrmCCPBytePosn5 : 39|8@0+ (1,0) [0|255] ""  ADD,SCU,SWM
 SG_ VehCfgPrmCCPBytePosn6 : 47|8@0+ (1,0) [0|255] ""  ADD,SCU,SWM
 SG_ VehCfgPrmCCPBytePosn7 : 55|8@0+ (1,0) [0|255] ""  ADD,SCU,SWM
 SG_ VehCfgPrmCCPBytePosn8 : 63|8@0+ (1,0) [0|255] ""  ADD,SCU,SWM

BO_ 389 XCD_ChassisFusion_RT_0x185: 16 XCD
 SG_ AdasSwt : 23|2@0+ (1,0) [0|3] ""  ADD
 SG_ AdasSwtSigGrpChks : 7|8@0+ (1,0) [0|255] ""  ADD
 SG_ AdasSwtSigGrpCntr : 11|4@0+ (1,0) [0|15] ""  ADD
 SG_ AdasSwtSigGrpLinErr : 21|2@0+ (1,0) [0|3] ""  ADD
 SG_ ChrgLidSts : 53|2@0+ (1,0) [0|3] ""  SCU
 SG_ DoorDrvrSts : 63|2@0+ (1,0) [0|3] ""  SCU
 SG_ DoorLeReSts : 61|2@0+ (1,0) [0|3] ""  SCU
 SG_ DoorPassSts : 59|2@0+ (1,0) [0|3] ""  SCU
 SG_ DoorRiReSts : 57|2@0+ (1,0) [0|3] ""  SCU
 SG_ HoodOpenClsSts : 51|2@0+ (1,0) [0|3] ""  ADD,SCU
 SG_ LeKnobCounter : 39|8@0+ (1,0) [0|254] ""  ADD
 SG_ LeKnobRotDir : 47|2@0+ (1,0) [0|3] ""  ADD
 SG_ LeMFctActSgCe : 45|2@0+ (1,0) [0|3] ""  ADD
 SG_ LeMFctActSgLe : 43|2@0+ (1,0) [0|3] ""  ADD
 SG_ LeMFctActSgRi : 41|2@0+ (1,0) [0|3] ""  ADD
 SG_ RiMFctActSgCe : 55|2@0+ (1,0) [0|3] ""  ADD
 SG_ TrOpenClsSts : 71|2@0+ (1,0) [0|3] ""  ADD,SCU

BO_ 520 XCD_ChassisFusion_RT_0x208: 8 XCD
 SG_ ARSPosnSts : 55|4@0+ (1,0) [0|15] ""  ADD,SCU
 SG_ HvBattSoCDisp : 34|11@0+ (0.05,0) [0|100] "%"  ADD
 SG_ RlsLinComFltSts : 37|1@0+ (1,0) [0|1] ""  ADD

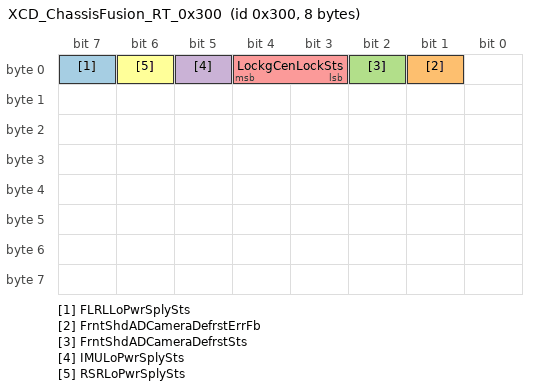
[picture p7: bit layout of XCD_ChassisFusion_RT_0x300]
BO_ 768 XCD_ChassisFusion_RT_0x300: 8 XCD
 SG_ FLRLLoPwrSplySts : 7|1@0+ (1,0) [0|1] ""  ADD
 SG_ FrntShdADCameraDefrstErrFb : 1|1@0+ (1,0) [0|1] ""  ADD
 SG_ FrntShdADCameraDefrstSts : 2|1@0+ (1,0) [0|1] ""  ADD
 SG_ IMULoPwrSplySts : 5|1@0+ (1,0) [0|1] ""  ADD
 SG_ LockgCenLockSts : 4|2@0+ (1,0) [0|3] ""  ADD,SCU
 SG_ RSRLoPwrSplySts : 6|1@0+ (1,0) [0|1] ""  ADD

BO_ 1313 XCDChassisFusionNMFr: 8 XCD
 SG_ NMKeepAwkRsnVCCD : 48|9@0+ (1,0) [0|511] ""  BCP,BCS,EPS,FZCU,SCU,SWM,VECU
 SG_ UDB17VCCD : 17|1@0+ (1,0) [0|1] ""  ADD,BCP,BCS,EPS,FZCU,SCU,SWM,VECU
 SG_ UDB18VCCD : 18|1@0+ (1,0) [0|1] ""  BCP,BCS,EPS,FZCU,SCU,SWM,VECU
 SG_ UDB19VCCD : 19|1@0+ (1,0) [0|1] ""  BCP,BCS,EPS,FZCU,SCU,SWM,VECU
 SG_ UDB20VCCD : 20|1@0+ (1,0) [0|1] ""  BCP,BCS,EPS,FZCU,SCU,SWM,VECU
 SG_ UDB21VCCD : 21|1@0+ (1,0) [0|1] ""  BCP,BCS,EPS,FZCU,SCU,SWM,VECU
 SG_ UDB22VCCD : 22|1@0+ (1,0) [0|1] ""  BCP,BCS,EPS,FZCU,SCU,SWM,VECU
 SG_ UDB23VCCD : 23|1@0+ (1,0) [0|1] ""  BCP,BCS,EPS,FZCU,SCU,SWM,VECU
 SG_ UDB24VCCD : 24|1@0+ (1,0) [0|1] ""  BCP,BCS,EPS,FZCU,SCU,SWM,VECU
 SG_ UDB25VCCD : 25|1@0+ (1,0) [0|1] ""  BCP,BCS,EPS,FZCU,SCU,SWM,VECU
 SG_ UDB26VCCD : 26|1@0+ (1,0) [0|1] ""  BCP,BCS,EPS,FZCU,SCU,SWM,VECU
 SG_ UDB27VCCD : 27|1@0+ (1,0) [0|1] ""  BCP,BCS,EPS,FZCU,SCU,SWM,VECU
 SG_ UDB28VCCD : 28|1@0+ (1,0) [0|1] ""  BCP,BCS,EPS,FZCU,SCU,SWM,VECU
 SG_ UDB29VCCD : 29|1@0+ (1,0) [0|1] ""  BCP,BCS,EPS,FZCU,SCU,SWM,VECU
 SG_ UDB30VCCD : 30|1@0+ (1,0) [0|1] ""  BCP,BCS,EPS,FZCU,SCU,SWM,VECU
 SG_ UDB31VCCD : 31|1@0+ (1,0) [0|1] ""  ADD,BCP,BCS,EPS,FZCU,SCU,SWM,VECU
 SG_ UDB32VCCD : 32|1@0+ (1,0) [0|1] ""  BCP,BCS,EPS,FZCU,SCU,SWM,VECU
 SG_ UDB33VCCD : 33|1@0+ (1,0) [0|1] ""  BCP,BCS,EPS,FZCU,SCU,SWM,VECU
 SG_ UDB34VCCD : 34|1@0+ (1,0) [0|1] ""  BCP,BCS,EPS,FZCU,SCU,SWM,VECU
 SG_ UDB35VCCD : 35|1@0+ (1,0) [0|1] ""  BCP,BCS,EPS,FZCU,SCU,SWM,VECU
 SG_ UDB36VCCD : 36|1@0+ (1,0) [0|1] ""  BCP,BCS,EPS,FZCU,SCU,SWM,VECU
 SG_ UDB37VCCD : 37|1@0+ (1,0) [0|1] ""  BCP,BCS,EPS,FZCU,SCU,SWM,VECU
 SG_ UDB38VCCD : 38|1@0+ (1,0) [0|1] ""  BCP,BCS,EPS,FZCU,SCU,SWM,VECU
 SG_ UDB39VCCD : 39|1@0+ (1,0) [0|1] ""  BCP,BCS,EPS,FZCU,SCU,SWM,VECU
 SG_ UDB40VCCD : 40|1@0+ (1,0) [0|1] ""  BCP,BCS,EPS,FZCU,SCU,SWM,VECU
 SG_ UDB41VCCD : 41|1@0+ (1,0) [0|1] ""  BCP,BCS,EPS,FZCU,SCU,SWM,VECU
 SG_ UDB42VCCD : 42|1@0+ (1,0) [0|1] ""  BCP,BCS,EPS,FZCU,SCU,SWM,VECU
 SG_ UDB43VCCD : 43|1@0+ (1,0) [0|1] ""  ADD,BCP,BCS,EPS,FZCU,SCU,SWM,VECU
 SG_ UDB44VCCD : 44|1@0+ (1,0) [0|1] ""  BCP,BCS,EPS,FZCU,SCU,SWM,VECU
 SG_ UDB45VCCD : 45|1@0+ (1,0) [0|1] ""  BCP,BCS,EPS,FZCU,SCU,SWM,VECU
 SG_ UDB46VCCD : 46|1@0+ (1,0) [0|1] ""  BCP,BCS,EPS,FZCU,SCU,SWM,VECU
 SG_ UDB47VCCD : 47|1@0+ (1,0) [0|1] ""  BCP,BCS,EPS,FZCU,SCU,SWM,VECU
 SG_ UDB49VCCD : 49|1@0+ (1,0) [0|1] ""  BCP,BCS,EPS,FZCU,SCU,SWM,VECU
 SG_ UDB50VCCD : 50|1@0+ (1,0) [0|1] ""  BCP,BCS,EPS,FZCU,SCU,SWM,VECU
 SG_ UDB51VCCD : 51|1@0+ (1,0) [0|1] ""  BCP,BCS,EPS,FZCU,SCU,SWM,VECU
 SG_ UDB52VCCD : 52|1@0+ (1,0) [0|1] ""  BCP,BCS,EPS,FZCU,SCU,SWM,VECU
 SG_ UDB53VCCD : 53|1@0+ (1,0) [0|1] ""  BCP,BCS,EPS,FZCU,SCU,SWM,VECU
 SG_ VCCDChassisBkpActiveWakeup : 12|1@0+ (1,0) [0|1] ""  BCP,BCS,EPS,FZCU,SCU,SWM,VECU
 SG_ VCCDChassisBkpNodeAddress : 7|8@0+ (1,0) [0|255] ""  BCP,BCS,EPS,FZCU,SCU,SWM,VECU
 SG_ VCCDChassisBkpRepeatMsgReq : 8|1@0+ (1,0) [0|1] ""  BCP,BCS,EPS,FZCU,SCU,SWM,VECU
 SG_ VCCDChassisBkpRepeatMsgSt : 16|1@0+ (1,0) [0|1] ""  BCP,BCS,EPS,FZCU,SCU,SWM,VECU

BO_ 2047 XCDToChassisFusionFuncDiagReqFr: 8 XCD
 SG_ VCCDToChassisBkpFuncDiagReq : 7|64@0+ (1,0) [0|1.84467440737096E+019] ""  EPS,SCU,SWM

BO_ 1832 XCDToEPSChassisFusionDiagReqFr: 64 XCD
 SG_ VCCDToEPSChassisBkpDiagReq : 7|512@0+ (1,0) [0|0] ""  EPS

BO_ 1828 XCDToSCUChassisFusionDiagReqFr: 64 XCD
 SG_ VCCDToSCUDiagReq : 7|512@0+ (1,0) [0|0] ""  SCU

BO_ 1829 XCDToSWMChassisFusionDiagReqFr: 64 XCD
 SG_ VCCDToSWMReq : 7|512@0+ (1,0) [0|0] ""  SWM

BO_ 1760 XCDToSWMDiagReqFr: 64 XCD
 SG_ VCCDToSWMDiagReq : 7|512@0+ (1,0) [0|0] ""  SWM

CM_ SG_ 186 ABSAvailability "ABS is available or not";
CM_ SG_ 186 BCSFxTargetMod "Signal shall show arbitrated brake request which will dominate the brake request with recuperation";
CM_ SG_ 186 BCSModBrakeActType "Actuation type of the final brake request is sent from Modulation to Actuation";
CM_ SG_ 186 BCSRecuFxRedTarget "Target pressure reduction";
CM_ SG_ 186 BCSRecuStatusMod "This signal shall provide the status of CRB in the secondary actuator";
CM_ SG_ 186 BrkSysAbsActv "Indicates that at least one wheel ABS is in control.";
CM_ SG_ 186 BrkSysDrvrPrsnt "Indicate whether driver is present";
CM_ SG_ 186 BrkSysLdmGlbStsMod "status from BCS LDM";
CM_ SG_ 186 BrkSysMstCylP "Pressure of master cylinder in the BCS. (without offset
 compensation)";
CM_ SG_ 186 BrkSysMstCylPVld "Qualifier for Pressure of master cylinder in the BCS signal";
CM_ SG_ 186 BrkSysPEstimnMax "Maximum of the estimated wheel pressures";
CM_ SG_ 186 BrkSysPRedActv "CRB Pressure Reduction Active";
CM_ SG_ 186 BrkSysPSysTar "Target brake system pressure";
CM_ SG_ 186 BrkSysRntSpprtAvl "Whether BCS have runout support capacity";
CM_ SG_ 186 BrkSysVehDirInfo "Vehicle speed direction for brake system used";
CM_ SG_ 186 BrkSysVehDirInfoVld "Qualifier for Vehicle speed direction for brake system used signal";
CM_ SG_ 186 BrkSysVehSpd "Averaged wheel speed";
CM_ SG_ 186 BrkSysVehSpdVld "Qualifier for BCS_BCP2_VehSpd signal";
CM_ SG_ 186 BrkSysVolSuctnActv "BCS is doing an active pressure build up";
CM_ SG_ 186 MaxTarSpdFrntAxle "Max speed for front axle  an absolute value irrespective of forward or reverse driving direction";
CM_ SG_ 186 MaxTarSpdFrntAxleRels "Release state of front axle speed control";
CM_ SG_ 186 MaxTarSpdReAxle "Max speed for rear axle  an absolute value irrespective of forward or reverse driving direction";
CM_ SG_ 186 MaxTarSpdReAxleRels "Release state of rear axle speed control";
CM_ SG_ 186 VehicleStandStill "the vehicle is not moving";
CM_ SG_ 186 VehicleStandStillQ "input qualify";
CM_ SG_ 186 VehVrnt "BCS variant info  mainly used for handshake check.";
CM_ SG_ 190 BrkSysAPCBkpStgyReqCom2 "APC Backup Strategy Request from main actuator to backup actuator on Com2";
CM_ SG_ 190 BrkSysAPCMain2BkpStCom2 "Parking function status from Main controller to backup controller";
CM_ SG_ 190 RPBHpsAck "Confirmation that hydraulic pressure support  HPS  is achieved by the hydraulics";
CM_ SG_ 190 RPBHpsAvl "Availability of hydraulic pressure support  HPS";
CM_ SG_ 190 RPBMstCylP "Current pressure of the master cylinder in the BCS for RPB used";
CM_ SG_ 190 RPBMstCylPVld "Qualifier for pressure of the master cylinder in the BCS";
CM_ SG_ 190 RPBWhlPFrntLe "Estimated or modeled wheel pressure of front left wheel brake for RPB used";
CM_ SG_ 190 RPBWhlPFrntLeVld "Qualifier for estimated front left wheel pressure signals";
CM_ SG_ 190 RPBWhlPFrntRi "Estimated or modeled wheel pressure of front right wheel brake for RPB used";
CM_ SG_ 190 RPBWhlPFrntRiVld "Qualifier for estimated front right wheel pressure signals";
CM_ SG_ 190 RPBWhlPReLe "Estimated or modeled wheel pressure of rear left wheel brake for RPB used";
CM_ SG_ 190 RPBWhlPReLeVld "Qualifier for estimated rear left wheel pressure signals";
CM_ SG_ 190 RPBWhlPReRi "Estimated or modeled wheel pressure of rear right wheel brake for RPB used";
CM_ SG_ 190 RPBWhlPReRiVld "Qualifier for estimated rear right wheel pressure signals";
CM_ SG_ 190 RPBWhlSpdFrntLe "Wheelspeedfrontleft";
CM_ SG_ 190 RPBWhlSpdFrntLeVld "Statusofwheelspeedfrontleft";
CM_ SG_ 190 RPBWhlSpdFrntRi "Wheelspeedfrontright";
CM_ SG_ 190 RPBWhlSpdFrntRiVld "Statusofwheelspeedfrontright";
CM_ SG_ 190 RPBWhlSpdReLe "Wheelspeedrearleft";
CM_ SG_ 190 RPBWhlSpdReLeVld "Statusofwheelspeedrearleft";
CM_ SG_ 190 RPBWhlSpdReRi "Wheelspeedrearright";
CM_ SG_ 190 RPBWhlSpdReRiVld "Statusofwheelspeedrearright";
CM_ SG_ 190 WhlPulFrntLe "Wheelplusefrontleft";
CM_ SG_ 190 WhlPulFrntRi "Wheelplusefrontright";
CM_ SG_ 190 WhlPulReLe "Wheelpluserearleft";
CM_ SG_ 190 WhlPulReRi "Wheelpluserearright";
CM_ SG_ 1315 BCSChassisBkpActiveWakeup "Active Wakeup Bit";
CM_ SG_ 1315 BCSChassisBkpNodeAddress "Node source address";
CM_ SG_ 1315 BCSChassisBkpRepeatMsgReq "Repeat Message Request Bit";
CM_ SG_ 1315 BCSChassisBkpRepeatMsgSt "Repeat Message State indication";
CM_ SG_ 444 RCAvailable "远控设备可用";
CM_ SG_ 444 RPARemReq "遥控泊车APP开关";
CM_ SG_ 657 BLEM2VCCDForLocn10 "BLEM to VCCD For Phone1 location";
CM_ SG_ 657 BLEM2VCCDForLocn11 "BLEM to VCCD For Phone1 location";
CM_ SG_ 657 BLEM2VCCDForLocn12 "BLEM to VCCD For Phone1 location";
CM_ SG_ 657 BLEM2VCCDForLocn13 "BLEM to VCCD For Phone1 location";
CM_ SG_ 657 BLEM2VCCDForLocn14 "BLEM to VCCD For Phone1 location";
CM_ SG_ 657 BLEM2VCCDForLocn15 "BLEM to VCCD For Phone1 location";
CM_ SG_ 657 BLEM2VCCDForLocn16 "BLEM to VCCD For Phone1 location";
CM_ SG_ 657 BLEM2VCCDForLocn17 "BLEM to VCCD For Phone1 location";
CM_ SG_ 657 BLEM2VCCDForLocn18 "BLEM to VCCD For Phone1 location";
CM_ SG_ 657 BLEM2VCCDForLocn19 "BLEM to VCCD For Phone1 location";
CM_ SG_ 657 BLEM2VCCDForLocn1A "BLEM to VCCD For Phone1 location";
CM_ SG_ 657 BLEM2VCCDForLocn1B "BLEM to VCCD For Phone1 location";
CM_ SG_ 657 BLEM2VCCDForLocn1C "BLEM to VCCD For Phone1 location";
CM_ SG_ 657 BLEM2VCCDForLocn1D "BLEM to VCCD For Phone1 location";
CM_ SG_ 657 BLEM2VCCDForLocn1F "BLEM to VCCD For Phone1 location";
CM_ SG_ 663 DltAllKeyFb "Delete all key feedback";
CM_ SG_ 663 SndBLEKeyPosnToRPA "Send BLE key message to RPA module";
CM_ SG_ 665 BLEM2VCCDForLocn20 "BLEM to VCCD For Phone2 location";
CM_ SG_ 665 BLEM2VCCDForLocn21 "BLEM to VCCD For Phone2 location";
CM_ SG_ 665 BLEM2VCCDForLocn22 "BLEM to VCCD For Phone2 location";
CM_ SG_ 665 BLEM2VCCDForLocn23 "BLEM to VCCD For Phone2  location";
CM_ SG_ 665 BLEM2VCCDForLocn24 "BLEM to VCCD For Phone2 location";
CM_ SG_ 665 BLEM2VCCDForLocn25 "BLEM to VCCD For Phone2 location";
CM_ SG_ 665 BLEM2VCCDForLocn26 "BLEM to VCCD For Phone2 location";
CM_ SG_ 665 BLEM2VCCDForLocn27 "BLEM to VCCD For Phone2 location";
CM_ SG_ 665 BLEM2VCCDForLocn28 "BLEM to VCCD For Phone2 location";
CM_ SG_ 665 BLEM2VCCDForLocn29 "BLEM to VCCD For Phone2 location";
CM_ SG_ 665 BLEM2VCCDForLocn2A "BLEM to VCCD For Phone2 location";
CM_ SG_ 665 BLEM2VCCDForLocn2B "BLEM to VCCD For Phone2 location";
CM_ SG_ 665 BLEM2VCCDForLocn2C "BLEM to VCCD For Phone2 location";
CM_ SG_ 665 BLEM2VCCDForLocn2D "BLEM to VCCD For Phone2 location";
CM_ SG_ 665 BLEM2VCCDForLocn2F "BLEM to VCCD For Phone2 location";
CM_ SG_ 758 FrntLeTyrePSnsrLoBattWarn "FrontLeftTyrePressureSensorLowBatteryWarning";
CM_ SG_ 758 FrntLeTyrePSnsrLostWarn "FrontLeftTyrePressureSensorLostWarning";
CM_ SG_ 758 FrntLeTyrePSnsrLrngSts "FrontLeftTyrePressureSensorLearningStatus";
CM_ SG_ 758 FrntLeTyrePVal "FrontLeftTyrePressureValue";
CM_ SG_ 758 FrntLeTyrePWarn "FrontLeftTyrePressureWarning";
CM_ SG_ 758 FrntLeTyreTWarn "FrontLeftTyreTemperatureWarning";
CM_ SG_ 758 FrntRiTyrePSnsrLoBattWarn "FrontRightTyrePressureSensorLowBatteryWarning";
CM_ SG_ 758 FrntRiTyrePSnsrLostWarn "FrontRightTyrePressureSensorLostWarning";
CM_ SG_ 758 FrntRiTyrePSnsrLrngSts "FrontRightTyrePressureSensorLearningStatus";
CM_ SG_ 758 FrntRiTyrePVal "FrontRightTyrePressureValue";
CM_ SG_ 758 FrntRiTyrePWarn "FrontRightTyrePressureWarning";
CM_ SG_ 758 FrntRiTyreTWarn "FrontRightTyreTemperatureWarning";
CM_ SG_ 758 ReLeTyrePSnsrLoBattWarn "RearLeftTyrePressureSensorLowBatteryWarning";
CM_ SG_ 758 ReLeTyrePSnsrLostWarn "RearLeftTyrePressureSensorLostWarning";
CM_ SG_ 758 ReLeTyrePSnsrLrngSts "RearLeftTyrePressureSensorLearningStatus";
CM_ SG_ 758 ReLeTyrePVal "RearLeftTyrePressureValue";
CM_ SG_ 758 ReLeTyrePWarn "RearLeftTyrePressureWarning";
CM_ SG_ 758 ReLeTyreTWarn "RearLeftTyreTemperatureWarning";
CM_ SG_ 758 ReRiTyrePSnsrLoBattWarn "RearRightTyrePressureSensorLowBatteryWarning";
CM_ SG_ 758 ReRiTyrePSnsrLostWarn "RearRightTyrePressureSensorLostWarning";
CM_ SG_ 758 ReRiTyrePSnsrLrngSts "RearRightTyrePressureSensorLearningStatus";
CM_ SG_ 758 ReRiTyrePVal "RearRightTyrePressureValue";
CM_ SG_ 758 ReRiTyrePWarn "RearRightTyrePressureWarning";
CM_ SG_ 758 ReRiTyreTWarn "RearRightTyreTemperatureWarning";
CM_ SG_ 758 TyrePwarnSts "TyrePwarn Status
轮胎压力报警状态";
CM_ SG_ 817 BLEM2VCCDForLocn40 "BLEM to VCCD For Phone4 location";
CM_ SG_ 817 BLEM2VCCDForLocn41 "BLEM to VCCD For Phone4 location";
CM_ SG_ 817 BLEM2VCCDForLocn42 "BLEM to VCCD For Phone4 location";
CM_ SG_ 817 BLEM2VCCDForLocn43 "BLEM to VCCD For Phone4 location";
CM_ SG_ 817 BLEM2VCCDForLocn44 "BLEM to VCCD For Phone4 location";
CM_ SG_ 817 BLEM2VCCDForLocn45 "BLEM to VCCD For Phone4 location";
CM_ SG_ 817 BLEM2VCCDForLocn46 "BLEM to VCCD For Phone4 location";
CM_ SG_ 817 BLEM2VCCDForLocn47 "BLEM to VCCD For Phone4 location";
CM_ SG_ 817 BLEM2VCCDForLocn48 "BLEM to VCCD For Phone4 location";
CM_ SG_ 817 BLEM2VCCDForLocn49 "BLEM to VCCD For Phone4 location";
CM_ SG_ 817 BLEM2VCCDForLocn4A "BLEM to VCCD For Phone4 location";
CM_ SG_ 817 BLEM2VCCDForLocn4B "BLEM to VCCD For Phone4 location";
CM_ SG_ 817 BLEM2VCCDForLocn4C "BLEM to VCCD For Phone4 location";
CM_ SG_ 817 BLEM2VCCDForLocn4D "BLEM to VCCD For Phone4 location";
CM_ SG_ 817 BLEM2VCCDForLocn4F "BLEM to VCCD For Phone4 location";
CM_ SG_ 825 BLEM2ADDForRPA00 "RPA路由功能";
CM_ SG_ 825 BLEM2ADDForRPA01 "RPA路由功能";
CM_ SG_ 825 BLEM2ADDForRPA02 "RPA路由功能";
CM_ SG_ 825 BLEM2ADDForRPA03 "RPA路由功能";
CM_ SG_ 826 BLEM2VCCDForLocn30 "BLEM to VCCD For Phone3 location";
CM_ SG_ 826 BLEM2VCCDForLocn31 "BLEM to VCCD For Phone3 location";
CM_ SG_ 826 BLEM2VCCDForLocn32 "BLEM to VCCD For Phone3 location";
CM_ SG_ 826 BLEM2VCCDForLocn33 "BLEM to VCCD For Phone3 location";
CM_ SG_ 826 BLEM2VCCDForLocn34 "BLEM to VCCD For Phone3 location";
CM_ SG_ 826 BLEM2VCCDForLocn35 "BLEM to VCCD For Phone3 location";
CM_ SG_ 826 BLEM2VCCDForLocn36 "BLEM to VCCD For Phone3 location";
CM_ SG_ 826 BLEM2VCCDForLocn37 "BLEM to VCCD For Phone3 location";
CM_ SG_ 826 BLEM2VCCDForLocn38 "BLEM to VCCD For Phone3 location";
CM_ SG_ 826 BLEM2VCCDForLocn39 "BLEM to VCCD For Phone3 location";
CM_ SG_ 826 BLEM2VCCDForLocn3A "BLEM to VCCD For Phone3 location";
CM_ SG_ 826 BLEM2VCCDForLocn3B "BLEM to VCCD For Phone3 location";
CM_ SG_ 826 BLEM2VCCDForLocn3C "BLEM to VCCD For Phone3 location";
CM_ SG_ 826 BLEM2VCCDForLocn3D "BLEM to VCCD For Phone3 location";
CM_ SG_ 826 BLEM2VCCDForLocn3F "BLEM to VCCD For Phone3 location";
CM_ SG_ 827 BLEM2VCCDForRkeReq00 "BLEM发送RKE请求";
CM_ SG_ 827 BLEM2VCCDForRkeReq01 "BLEM发送RKE请求";
CM_ SG_ 827 BLEM2VCCDForRkeReq02 "BLEM发送RKE请求";
CM_ SG_ 827 BLEM2VCCDForRkeReq03 "BLEM发送RKE请求";
CM_ SG_ 827 BLEM2VCCDForRkeReq08 "BLEM发送RKE请求";
CM_ SG_ 827 BLEM2VCCDForRkeReq09 "BLEM发送RKE请求";
CM_ SG_ 827 BLEM2VCCDForRkeReq10 "BLEM发送RKE请求";
CM_ SG_ 827 BLEM2VCCDForRkeReq11 "BLEM发送RKE请求";
CM_ SG_ 827 BLEM2VCCDForRkeReq12 "BLEM发送RKE请求";
CM_ SG_ 827 BLEM2VCCDForRkeReq13 "BLEM发送RKE请求";
CM_ SG_ 827 BLEM2VCCDForRkeReq14 "BLEM发送RKE请求";
CM_ SG_ 579 BattSocRaw "Battery State of charge raw
电池SOC";
CM_ SG_ 579 BattURaw "Battery Voltage raw
电池电压";
CM_ SG_ 581 BattSoh "Battery State of health
电池SOH";
CM_ SG_ 581 BMDMAcvDcnMosSt "BMDM active disconnect Mosfet State
BMDM主动断电Mos状态";
CM_ SG_ 581 LVBattMosDrvFlt "Low Voltage Battery Mosfet Drive Fault 
低压电池Mos粘连故障";
CM_ SG_ 581 LVBattMosStuckFlt "Low Voltage Battery Mosfet Stuck Fault 
低压电池Mos卡滞故障";
CM_ SG_ 912 BalOnCellNumb "当前开启均衡单体数目";
CM_ SG_ 912 CMU1ComErrTi "Accumulated duration of communication error of any AFE on CMU 1";
CM_ SG_ 912 CMU2ComErrTi "Accumulated duration of communication error of any AFE on CMU 2";
CM_ SG_ 912 CMU3ComErrTi "Accumulated duration of communication error of any AFE on CMU 3";
CM_ SG_ 912 HvBattCellAvrgSocErr "单体平均SOC计算误差";
CM_ SG_ 912 HvBattCellMaxSoc "单体最大SOC";
CM_ SG_ 912 HvBattCellMaxSocErr "单体最大SOC计算误差";
CM_ SG_ 912 HvBattCellMaxSocErrIdx "单体最大SOC计算误差 index";
CM_ SG_ 912 HvBattCellMaxSocIdx "单体最大SOC index";
CM_ SG_ 912 HvBattCellMinSoc "单体最小SOC";
CM_ SG_ 912 HvBattCellMinSocIdx "单体最小SOC index";
CM_ SG_ 912 HvBattEgyAvlForChrgnToTarSoC "HV battery energy available for charging to target SoC referring to a user defined charging target SOC 
用于充电场景 最大允许充电SoC在100%";
CM_ SG_ 912 HvBattEgyAvlForDchrgnToTarSoC "HV battery energy available for discharging to target SoC referring to a user defined discharging target SOC 
用于V2X场景 最小允许放电SoC在20%";
CM_ SG_ 912 HvBattPressureInsdPack "HV battery pressure inside the pack.";
CM_ SG_ 912 HvBattSoCLimMax "HV battery state of charge limit max  用于说明DOD的上限";
CM_ SG_ 912 HvBattSoCLimMin "HV battery state of charge limit min 用于说明DOD的下限";
CM_ SG_ 912 HvPrechargeTimer "最近一次预充时间";
CM_ SG_ 355 AVPHPPCtrlAvlStsBkp "EPS AVP/HPP Feature Control Avaliable Status Back Up
EPS对于 AVP/HPP 功能的控制可用状态备份信号";
CM_ SG_ 355 AVPHPPCtrStsBkp "What channel of the EPS is in control back up.
表征EPS目前正在响应的通道备份信号";
CM_ SG_ 355 AVPHPPReqFbStsBkp "EPS feedback for AVP/HPP request back up
EPS 对于AVP/HPP的请求反馈备份信号";
CM_ SG_ 355 AVPHPPReqFltStsBkp "EPS fault status related to execution of AVP/HPP back up
EPS反馈AVP/HPP当前的故障状态备份信号";
CM_ SG_ 355 FailrStsBkp "EPS 故障状态 备份CAN 
EPS Failure Status
 back up";
CM_ SG_ 994 CcwEOTDetBkp "Bkp CANFD:
Counter Clock wise End of Stop Value Learned Flag. 逆时针软止点(末端)位置学习成功标志位";
CM_ SG_ 994 CcwEOTValueBkp "Bkp CANFD:Counter Clock wise End of Stop Value, Direction:Counter Clock wise is.逆时针软止点(末端)位置, 方向:逆时针为正";
CM_ SG_ 994 CwEOTDetBkp "Bkp CANFD:
Clock wise End of Stop Value Learned Flag. 顺时针软止点(末端)位置学习成功标志位";
CM_ SG_ 994 CwEOTValueBkp "BkpCANFD:Clock wise End of Stop Value, Direction: Clock wise is.顺时针软止点(末端)位置, 方向:顺时针为负";
CM_ SG_ 181 ADASReqFbStsADD "Feedback status to ADD driving lateral control request";
CM_ SG_ 181 ADASReqFltStsADD "Feedback fault status to ADD driving lateral control request";
CM_ SG_ 181 ADASReqOvlySteerWhlTqADD "Equivalent steering wheel torque from ADD driving lateral control request
'+' as the equivalent torque generate Anti Clockwise of steering wheel
' ' as the equivalent torque generate Clockwise of steering wheel";
CM_ SG_ 181 ADASReqOvlyTqADD "Overlay Torque  Motor Torque  from ADD driving lateral control request
方向 
顺时针转动方向盘请求  
逆时针转动方向盘请求";
CM_ SG_ 181 DrvrSteerActvADD "Indicate if the driver override or not to ADD driving lateral control request";
CM_ SG_ 181 ElecPwrCns "EPS 电流
EPS battery consumption";
CM_ SG_ 181 EPSMotTqCmd "转向电机请求扭矩 EPS Motor Torque Command 方向：Clockwise: -; Anti-Clockwise: +；
";
CM_ SG_ 181 EstimdRkF "EPS内部估算的齿条力
EPS internal estimated rack force";
CM_ SG_ 181 EstimdRkFVld "EPS内部估算的齿条力有效位
EPS internal estimated rack force valid flag";
CM_ SG_ 181 PinionAglSpdV2C "Convert VGR Pinion Velocity to CGR Velocity. Direction: Clockwise; Counter Clockwise.VGR方向盘转速转成CGR转速.顺时针为负,逆时针为正";
CM_ SG_ 181 PinionSteerAgl "方向盘转角
Steering Wheel Angle
方向 
Anticlockwise direction of steering wheel increase angle output.
Clockwise direction of steering wheel decrease angle output.";
CM_ SG_ 181 PinionSteerAglSpd "方向盘转速
Steering Wheel Velocity
方向  Clockwise     Anti Clockwise";
CM_ SG_ 181 PinionSteerAglSpdVld "方向盘转速有效位
Steering Wheel Velocity Valid Flag";
CM_ SG_ 181 PinionSteerAglSpdVldV2C "Pinion Velocity Valid Flag
方向盘转速有效位";
CM_ SG_ 181 PinionSteerAglV2C "Convert Variable Gear Ratio(VGR) PinionAngle to a Constant Gear Ratio(CGR) Pinion Angle.将VGR方向盘转角转成CGR 转角";
CM_ SG_ 181 PinionSteerAglVld "方向盘转角有效位
Steering Wheel Angle Valid Flag";
CM_ SG_ 181 PinionSteerAglVldV2C "PinionAngle Valid Flag
方向盘转交有效位";
CM_ SG_ 181 SteerWhlTq "方向盘扭矩
Steering Wheel Torque
方向  Clockwise     Anti Clockwise";
CM_ SG_ 181 SteerWhlTqVld "方向盘扭矩有效位
Steering Wheel torque Valid Flag";
CM_ SG_ 181 SteerWhlVibStsADD "Indicate the steering wheel vibration active or not to ADD";
CM_ SG_ 181 VehSpdEPSInUse "Vehicle Speed EPS Internal Use 转向内部使用车速";
CM_ SG_ 200 PinionAglSpdBkpV2C "For BkpCAN: Convert VGR Pinion Velocity to CGR Pinion Velocity.用于备份CAN:将VGR方向盘转速转成CGR转速.方向:顺时针为负,逆时针为正";
CM_ SG_ 200 PinionSteerAglBkp "方向盘转角 备份CAN 
Steering Wheel Angle back up
方向  
Anticlockwise direction of steering wheel increase angle output.
Clockwise direction of steering wheel decrease angle output.";
CM_ SG_ 200 PinionSteerAglBkpV2C "For BkpCAN:Convert VGR pinion angle to CGR pinion angle.用于备份CAN:将VGR方向盘转角转成CGR转角";
CM_ SG_ 200 PinionSteerAglSpdBkp "方向盘转速 备份CAN 
Steering Wheel Velocity back up
方向  Clockwise     Anti Clockwise";
CM_ SG_ 200 PinionSteerAglSpdVldBkp "方向盘转速有效位 备份CAN 
Steering Wheel Velocity Valid Flag back up";
CM_ SG_ 200 PinionSteerAglSpdVldBkpV2C "BkpCAN:PinionVelocity Valid Flag.备份CAN:方向盘转速有效位";
CM_ SG_ 200 PinionSteerAglVldBkp "方向盘转角有效位 备份CAN 
Steering Wheel Angle Valid Flag back up";
CM_ SG_ 200 PinionSteerAglVldBkpV2C "BkpCAN: PinionAngle Valid Flag
备份CAN: 方向盘转交有效位";
CM_ SG_ 200 SteerWhlTqBkp "方向盘扭矩 备份CAN 
Steering Wheel Torque back up
方向  Clockwise     Anti Clockwise";
CM_ SG_ 200 SteerWhlTqVldBkp "方向盘扭矩有效位 备份CAN 
Steering Wheel torque Valid Flag back up";
CM_ SG_ 1322 EPSChassisBkpActiveWakeup "Active Wakeup Bit";
CM_ SG_ 1322 EPSChassisBkpNodeAddress "Node source address";
CM_ SG_ 1322 EPSChassisBkpRepeatMsgReq "Repeat Message Request Bit";
CM_ SG_ 1322 EPSChassisBkpRepeatMsgSt "Repeat Message State indication";
CM_ SG_ 1576 EPSToVCCDChassisBkpDiagResp "EPSToVCCDChassisBkpCanfdDiagRespNpdu";
CM_ SG_ 347 MIAAirSprgActvd "MIA Active Air Spring Control
MIA请求激活空簧随速调节信号";
CM_ SG_ 347 MIACurAirDrgVal "Current Air Drag
实时空气阻力 PE触发后更新";
CM_ SG_ 347 MIACurCdVal "Current Coefficient of Drag
当前车辆形态下的风阻系数Cd";
CM_ SG_ 347 MIACurMod "Micar Intelligent Aerodynamic Current Operating Mode
米车智能空气动力学当前工作模式";
CM_ SG_ 347 MIACurPwrCnsAirDrg "Micar Intelligent Aerodynamic Current Power Consumption of Air Drag
米车智能空气动力学功能结合当前车速 天气 当前AGS开度 尾翼开度计算的实时风阻功耗";
CM_ SG_ 347 VCUReElsdLvlReq "VCU Rear e-LSD Level Request";
CM_ SG_ 347 VCUReElsdOpenReq "VCU Rear e-LSD Clutch Open Request";
CM_ SG_ 515 VCUExtmPfmncMod "VCU extreme performance mode
VCU狂暴模式";
CM_ SG_ 515 VCULnchPlusSts "VCU Launch plus status
VCU弹射模式状态";
CM_ SG_ 515 VCUTrlrModStSts "VCU Trailer Mode Setting Status
VCU反馈拖车模式设置状态";
CM_ SG_ 515 VCUWashModStSts "VCU wash mode setting status 
VCU洗车模式设定状态";
CM_ SG_ 515 VDMMueEstdForADD "Road Mue Estimated for ADD
车端感知道路附着系数";
CM_ SG_ 533 FZCUSyncFVReq1 "1";
CM_ SG_ 656 ADDCooltCircFlowEstimd "Estimated coolant flowrate for ADD coolant circuit.";
CM_ SG_ 656 AmbTEstimd "Estimated ambient temperature.";
CM_ SG_ 656 AmbTEstimdVld "Estimated ambient temperature valid value.";
CM_ SG_ 656 AmbTRaw "Raw ambient temperature";
CM_ SG_ 656 AmbTRawVld "Raw ambient temperature valid value";
CM_ SG_ 656 EdsCircCooltT "Coolant temperature at EDS coolant circuit";
CM_ SG_ 656 EdsCircCooltTSnsrU "Coolant temperature sensor voltage at EDS coolant circuit";
CM_ SG_ 656 EdsCircCooltTVld "Coolant temperature at EDS coolant circuit valid value";
CM_ SG_ 656 LRRLoPwrSplySts "LRR low Power Supply Status
前向毫米波雷达配电状态";
CM_ SG_ 656 VCUBattOverHeatWarn "电池过温时 仪表点亮电池过温报警灯";
CM_ SG_ 656 VCUChrgnModSts "Charging Mode Status";
CM_ SG_ 656 VCUDrvMotFltWarn "当驱动电机发生故障时 仪表点亮驱动电机故障灯";
CM_ SG_ 656 VCUDrvMotOverHeatWarn "驱动电机过热报警";
CM_ SG_ 656 VCUDrvSysLimdWarn "VCU发送点亮跛行故障灯信号 仪表点灯";
CM_ SG_ 656 VCUEgyCnsInCurDrvCyc "显示本次行程的电耗量";
CM_ SG_ 656 VCUEstimdCrsRng "Estimated range
续航里程值显示";
CM_ SG_ 656 VCUEstimdCrsRngForCltc "Cltc公告续航预测值";
CM_ SG_ 656 VCUEstimdCrsRngVld "Estimated range Validty
续航里程有效性";
CM_ SG_ 656 VCUGearChgFailInde "换挡失败提醒";
CM_ SG_ 656 VCUHvBattSysFltIndcr "动力电池故障报警灯 低级";
CM_ SG_ 656 VCUHvBattSysFltWarn "动力电池故障报警灯 严重";
CM_ SG_ 656 VCUHvPwrSysCutOff "VCU发送动力系统切断故障telltale";
CM_ SG_ 656 VCUHVSysFltWarnSts "高压系统故障 分等级";
CM_ SG_ 656 VCUInsEgyCnsDurgDrvg "瞬时电耗 行车状态";
CM_ SG_ 656 VCUInsEgyCnsDurgStsl "瞬时电耗 停车状态";
CM_ SG_ 656 VCUInsEgyCnsFlg "瞬时电耗标志位";
CM_ SG_ 656 VCULoSocWarngMsg "高压电池低电量报警
HV Battery low SOC warnning";
CM_ SG_ 656 VCUPrpsnPwrDrt "VCU发送动力性能降级故障 仪表进行文字显示和声音提醒";
CM_ SG_ 656 VCUThermRunawayErrAlrm "热失控报警";
CM_ SG_ 656 VCUVehSysFltWarn "VCU发送点亮整车系统故障灯信号 仪表点灯";
CM_ SG_ 144 CarModSts "CarMode状态信号";
CM_ SG_ 144 PwrModSts "PowerMode Status";
CM_ SG_ 144 PwrModVld "PowerMode Validty";
CM_ SG_ 144 VCUAccrPedlRat "加速油门踏板开度";
CM_ SG_ 144 VCUAccrPedlRatVld "加速踏板有效性";
CM_ SG_ 144 VCUActDrvMod "VCU actual drive mode 
VCU实际驾驶模式";
CM_ SG_ 144 VCUActGearLvr "Actual gear level 车辆实际档位
P R N D挡位";
CM_ SG_ 144 VCUActGearLvrVld "车辆实际档位有效位";
CM_ SG_ 144 VCUDrvModSteerAsstPrmSts "VCU Drive mode steering assistance parameter Status
驾驶模式转向助力特性参数设置";
CM_ SG_ 144 VCUDrvModSuspDampgPrmSts "VCU Drive mode suspension damping parameter Status
驾驶模式悬架阻尼参数设置";
CM_ SG_ 144 VCUDrvModSuspLvlgPrmSts "VCU Drive mode suspension level parameter Status
驾驶模式悬架高度参数设置";
CM_ SG_ 144 VCUDrvOffFcnLim "VCU send to BCS to identify whether vehcile can drive off or not as powertrain has fault and power limited.
VCU发送给BCS系统,用于判断整车动力系统是否存在故障动力受限不能起步的判断";
CM_ SG_ 144 VCUFrntEmTqRdy "The Front Motor  can be ready to response chassis torque request.
前电机可以响应扭矩请求.";
CM_ SG_ 144 VCUGearLvrAvail "Vehicle Gear Response is available for ADAS
给智驾反馈的挡位可用标志位";
CM_ SG_ 144 VCUPrkgBtnPsd "驾驶员按下P档";
CM_ SG_ 144 VCUPrkgBtnPsdVld "驾驶员长按P挡有效性";
CM_ SG_ 144 VCUPtRdyFlg "驾驶使能";
CM_ SG_ 144 VCUReEmTqRdy "Rear EM is ready to response chassis Torque Request
后电机是否处于Ready状态";
CM_ SG_ 144 VCURgnTqCorrnFac "Regeneration Torque Correction Factor";
CM_ SG_ 144 VCUShifterMoveFlg "驾驶员拨动了换挡杆的标志位";
CM_ SG_ 144 VCUStsModCst "energy recuperation end mode.
能量回收状态模式";
CM_ SG_ 144 VCUTarGearLvr "目标档位  P R N D挡位";
CM_ SG_ 144 VCUTarGearLvrVld "目标档位有效位";
CM_ SG_ 144 VCUVirtAccrPedl "虚拟油门开度 当前模式的pedal map反算";
CM_ SG_ 144 VCUVirtAccrPedlVld "虚拟油门开度有效位";
CM_ SG_ 188 PreDampgCtrlReqFL "Preview suspension damping control request front left
左前悬架阻尼预判控制请求";
CM_ SG_ 188 PreDampgCtrlReqFR "Preview suspension damping control request front right
右前悬架阻尼预判控制请求";
CM_ SG_ 188 PreDampgCtrlReqRL "Preview suspension damping control request rear left
左后悬架阻尼预判控制请求";
CM_ SG_ 188 PreDampgCtrlReqRR "Preview suspension damping control request rear right
右后悬架阻尼预判控制请求";
CM_ SG_ 188 RdRghnessLvl "Road roughness level
路面粗糙度等级";
CM_ SG_ 188 SuspRoadConditionForADD "Road Conditions detected by suspension  transfer to ADD
悬架感知的道路工况";
CM_ SG_ 188 VCUAccrPedlRatGrdt "加速油门踏板开度变化率";
CM_ SG_ 188 VCUFrntDesTqWoIntv "前轴未干预需求扭矩";
CM_ SG_ 188 VCUFrntDesTqWoIntvVld "前轴未干预需求扭矩有效性";
CM_ SG_ 188 VCUFrntMotActSpd "前电机实际转速";
CM_ SG_ 188 VCUFrntMotActSpdVld "前电机实际转速有效位";
CM_ SG_ 188 VCUFrntMotActTq "前电机实际扭矩 明确为轴端扭矩 非电机端扭矩";
CM_ SG_ 188 VCUFrntMotActTqVld "前电机实际扭矩有效位";
CM_ SG_ 188 VCUFrntMotWhlTqReq "Front motor torque request";
CM_ SG_ 188 VCUFrntMotWhlTqReqVld "Front motor torque request Valid";
CM_ SG_ 188 VCUFrntWhlTqMaxAvl "前轮最大可用扭矩";
CM_ SG_ 188 VCUFrntWhlTqMaxAvlVld "前轮最大可用扭矩有效位";
CM_ SG_ 188 VCUFrntWhlTqMinAvl "前轮最小可用扭矩";
CM_ SG_ 188 VCUFrntWhlTqMinAvlVld "前轮最小可用扭矩有效位";
CM_ SG_ 188 VCULnchPlusAcvFlg "Launch Plus function is active
弹射起步功能激活标志位";
CM_ SG_ 188 VCUOperModFAOfDMC "Indicates the status of the DMC.";
CM_ SG_ 188 VCUOperModRAOfDMC "Indicates the status of the DMC.";
CM_ SG_ 188 VCUReDesTqWoIntv "后轴未干预需求扭矩";
CM_ SG_ 188 VCUReDesTqWoIntvVld "后轴未干预需求扭矩有效性";
CM_ SG_ 188 VCUReMotActSpd "后电机实际转速";
CM_ SG_ 188 VCUReMotActSpdVld "后电机实际转速有效位";
CM_ SG_ 188 VCUReMotActTq "后电机实际扭矩 明确为轴端扭矩 非电机端扭矩";
CM_ SG_ 188 VCUReMotActTqVld "后电机实际扭矩有效位";
CM_ SG_ 188 VCUReMotWhlTqReq "Rear motor torque request";
CM_ SG_ 188 VCUReMotWhlTqReqVld "Rear motor torque request Valid";
CM_ SG_ 188 VCUReWhlTqMaxAvl "后轮最大可用扭矩";
CM_ SG_ 188 VCUReWhlTqMaxAvlVld "后轮最大可用扭矩有效位";
CM_ SG_ 188 VCUReWhlTqMinAvl "后轮最小可用扭矩";
CM_ SG_ 188 VCUReWhlTqMinAvlVld "后轮最小可用扭矩有效位";
CM_ SG_ 188 VCUSWVersOfDMC "DMC SWInfo including variant info  mainly used for handshake check.";
CM_ SG_ 188 VCUTarTqFAAOfDMC "DMC torque target FA";
CM_ SG_ 188 VCUTarTqRAOfDMC "DMC torque target RA";
CM_ SG_ 188 VCUWhlTqMaxAvl "Vehicle Total Axle Max ability of Wheel Torque.
整车前后轴总的最大可用扭矩";
CM_ SG_ 188 VCUWhlTqMaxAvlVld "The validation of Vehicle total axle max ability of Wheel Torque.
整车前后轴总的可用回收扭矩的有效位";
CM_ SG_ 188 VDMLgtWhlSpdFL "VDM longitudinal wheel speed front left
左前轮纵向速度";
CM_ SG_ 188 VDMLgtWhlSpdFR "VDM longitudinal wheel speed front right
右前轮纵向速度";
CM_ SG_ 188 VDMLgtWhlSpdRL "VDM longitudinal wheel speed real left
左后轮纵向速度";
CM_ SG_ 188 VDMLgtWhlSpdRR "VDM longitudinal wheel speed rear right
右后轮纵向速度";
CM_ SG_ 188 VehBodySideSlipAng "vehicle body side slip angle";
CM_ SG_ 188 VehLatSpdEstd "lateral vehicle speed estemsted
横向车速";
CM_ SG_ 188 VehLatSpdEstdVld "vehicle lateral speed estimated valid
横向车速有效性";
CM_ SG_ 188 VehLgtSpdEstd "longitudinal vehicle speed estemsted
纵向车速";
CM_ SG_ 188 VehLgtSpdEstdVld "Vehicle longitudinal speed estimated valid
纵向车速有效性";
CM_ SG_ 607 AswmLinComFltSts "ASWM LIN node communication fault status.";
CM_ SG_ 607 HandOnDetnStsSigGrpLinErr "HandOnDetnStsSigGrp LIN communication Error";
CM_ SG_ 607 HandsOnDetectionErrorStatus "方向盘离手检测故障状态";
CM_ SG_ 607 HandsOnDetectionStatus "方向盘离手检测状态";
CM_ SG_ 607 StsOfBSDLampLe "Status Of Left BSD Lamp
左BSD 灯状态";
CM_ SG_ 892 DrvrOcupcySts "Driver Occupancy Sensor Status
主驾座椅占位传感器检测状态";
CM_ SG_ 892 HfaftActPosn "Actual position of actuator";
CM_ SG_ 892 HfaftAdrSts "Actuator address";
CM_ SG_ 892 HfaftApplyHldCurSts "Applied holding current";
CM_ SG_ 892 HfaftElecDfctErr "Electric defect";
CM_ SG_ 892 HfaftEmgyRunOccurred "Emergency run occurred";
CM_ SG_ 892 HfaftEmgyRunPosnSts "Emergency run position";
CM_ SG_ 892 HfaftEmgyRunRelsSts "Emergency run release";
CM_ SG_ 892 HfaftLinComFltSts "Hfaft LIN node communication fault status";
CM_ SG_ 892 HfaftMoveDir "Movement direction";
CM_ SG_ 892 HfaftOverTempErr "Over temperature";
CM_ SG_ 892 HfaftPosnSpcnSts "Position specification status";
CM_ SG_ 892 HfaftRespErr "Response error";
CM_ SG_ 892 HfaftRotDirSts "Rotation direction";
CM_ SG_ 892 HfaftRst "Reset";
CM_ SG_ 892 HfaftSelfHldTq "Self holding torque";
CM_ SG_ 892 HfaftSpclFcns "Special functions";
CM_ SG_ 892 HfaftSpdSts "Speed status";
CM_ SG_ 892 HfaftSplyVoltErr "Supply voltage";
CM_ SG_ 892 HfaftStallDetnRelsSts "Stall detection release";
CM_ SG_ 892 HfaftStallOccurred "Stall occurred";
CM_ SG_ 892 HfaftStopModSts "Stop mode";
CM_ SG_ 892 SecRowLeOcupcySts "Second Row Left Ocupcy Sensor Status
二排左侧座椅占位传感器检测状态";
CM_ SG_ 616 RlsAutWinWipgSpdCmd "雨刮速度请求";
CM_ SG_ 616 RlsFwdLiSnsrVal "前向光线亮度";
CM_ SG_ 616 RlsFwdLiSnsrValUnit "前向光线亮度单位";
CM_ SG_ 616 RlsHudSnsrVal "Hud亮度";
CM_ SG_ 616 RlsHudSnsrValUnit "Hud亮度单位";
CM_ SG_ 616 RlsIRVal "红外光值输出";
CM_ SG_ 616 RlsLiSigGrpLinErr "RlsLiSigGrp LIN communication Error";
CM_ SG_ 616 RlsLiSnsrFwdFlt "RLS光线传感器 前向 故障";
CM_ SG_ 616 RlsLiSnsrIRFlt "RLS光线传感器 IR红外 故障";
CM_ SG_ 616 RlsLiSnsrTopFlt "RLS光线传感器 顶向 故障";
CM_ SG_ 616 RlsOutdBriSts "白天 黑夜 隧道检测";
CM_ SG_ 616 RlsSts "雨量阳光传感器状态";
CM_ SG_ 616 RlsTopLiSnsrVal "Top Light Value
顶向光线亮度";
CM_ SG_ 616 RlsTopLiSnsrValUnit "顶部光线亮度单位";
CM_ SG_ 616 StsOfBSDLampRi "Status Of Right BSD Lamp
右BSD灯状态";
CM_ SG_ 893 PassOcupcySts "Passenger Occupancy Sensor  Status
副驾座椅占位传感器检测状态";
CM_ SG_ 893 SecRowMidOcupcySts "Second Row Middle Ocupcy Sensor Status
二排中间座椅占位传感器检测状态";
CM_ SG_ 893 SecRowRiOcupcySts "Second Row Right Ocupcy Sensor Status
二排右侧座椅占位传感器检测状态";
CM_ SG_ 893 ThrdRowMidOcupcySts "Third Row Left Ocupcy Sensor Status 
三排左侧座椅占位传感器检测状态";
CM_ SG_ 893 ThrdRowRiOcupcySts "Third Row Right Ocupcy Sensor Status
后排右侧座椅占位传感器检测状态";
CM_ SG_ 342 AirPResv "Air Pressure Reservoir";
CM_ SG_ 342 AirPResvSts "Air Pressure Reservoir status";
CM_ SG_ 342 ASCFltSts "Air spring control fault status";
CM_ SG_ 342 BatDamprModAllwd "Battle Damping Mode Allowed";
CM_ SG_ 342 CDCFltSts "Continuous Daming control fault status";
CM_ SG_ 342 CmftDamprModAllwd "Comfort Damping Mode Allowed";
CM_ SG_ 342 CurDampgCtrlMod "Current active damping control mode";
CM_ SG_ 342 EasyEntryEnaSts "Easy entry Request Enable Status";
CM_ SG_ 342 EasyEntryHeiSetSts "Easy Entry Height Set Status";
CM_ SG_ 342 EasyEntrySts "Easy entry Request Status";
CM_ SG_ 342 EasyLoadEnaSts "Easy load Request Enable Status";
CM_ SG_ 342 EasyLoadgFuncCouplAct "Easy loading couple function actual status";
CM_ SG_ 342 EasyLoadSts "Easy loading Request Status";
CM_ SG_ 342 ESPEnaReq "ESC OFF NOT ALLOWED";
CM_ SG_ 342 FrntLeAirSprgP "Front Left Air spring pressure";
CM_ SG_ 342 FrntLeAirSprgPSts "Front Left Air spring pressure status";
CM_ SG_ 342 FrntRiAirSprgP "Front Right Air spring pressure";
CM_ SG_ 342 FrntRiAirSprgPSts "Front Right Air spring pressure status";
CM_ SG_ 342 HiLvlMod1Allwd "HL1 Level Mode Allowed";
CM_ SG_ 342 HiLvlMod1RestrcnRsn "HL1 Level Mode Restriction Reason";
CM_ SG_ 342 HiLvlMod2Allwd "HL2 Level Mode Allowed";
CM_ SG_ 342 HiLvlMod2RestrcnRsn "HL2 Level Mode Restriction Reason";
CM_ SG_ 342 JackModEnaSts "Level Control deactivation request Enable status  Jack Mode";
CM_ SG_ 342 JackModSts "Level Control deactivation request status  Jack Mode";
CM_ SG_ 342 LoLvlMod1Allwd "LL1 Level Mode Allowed";
CM_ SG_ 342 LoLvlMod1RestrcnRsn "LL1 Level Mode Restriction Reason";
CM_ SG_ 342 LoLvlMod2Allwd "LL2 Level Mode Allowed";
CM_ SG_ 342 LoLvlMod2RestrcnRsn "LL2 Level Mode Restriction Reason";
CM_ SG_ 342 LvlAdjmtSts "level control mode adjustment status  ie. Lowering from Normal to Low";
CM_ SG_ 342 LvlCtrlCalCompl "Level control  HeightSensor  calibration completed";
CM_ SG_ 342 LvlModAct "Height Level Mode Actual";
CM_ SG_ 342 NormDamprModAllwd "Normal Damping Mode Allowed";
CM_ SG_ 342 NormLvlModAllwd "Normal Level Mode Allowed";
CM_ SG_ 342 NormLvlModRestrcnRsn "NL Level Mode Restriction Reason";
CM_ SG_ 342 ReLeAirSprgP "Rear Left Air spring pressure";
CM_ SG_ 342 ReLeAirSprgPSts "Rear Left Air spring pressure status";
CM_ SG_ 342 ReRiAirSprgP "Rear Right Air spring pressure";
CM_ SG_ 342 ReRiAirSprgPSts "Rear Right Air spring pressure status";
CM_ SG_ 342 SCUExtmHeiSts "SCU Extreme Height Status
SCU 悬架极高极低状态";
CM_ SG_ 342 SCULimSpdTqReq "SCU 限速限扭请求
SCU Limit Speed Torque Request";
CM_ SG_ 342 SCUSelfAwkLvlAdjmt "SCU Self Awakening Level Adjustment
SCU 自唤醒高度调节";
CM_ SG_ 342 SCUWarnLampReq "SCU Warning Lamp Request
SCU 故障灯请求";
CM_ SG_ 342 SCUWarnMsgASC "SCU Warning Message ASC
空气悬架故障警示信号";
CM_ SG_ 342 SCUWarnMsgCDC "SCU Warning Message CDC
电控减震器故障警示信号";
CM_ SG_ 342 SprgRateSts "Spring Rate Status of Dual Chamber Air Spring";
CM_ SG_ 342 SprgRateStsVld "Spring Rate Status Valid 
空簧刚度有效性";
CM_ SG_ 342 SptDamprModAllwd "Sport Damping Mode Allowed";
CM_ SG_ 342 StdLvlSpdSwtSts "Standard Level Speed depending Switch status
随速调节功能开关状态";
CM_ SG_ 342 StdLvlSpdSwtVld "Standard Level Speed depending Switch available to select or not  随速调节功能是否可用";
CM_ SG_ 342 SuspHeiAdjmtReqSrc "Suspension Height Adjustment Request Source
悬架高度调节源";
CM_ SG_ 342 SuspHeiSetSts "Suspension Height Set Status
悬架高度设定状态 (座舱高度设置反馈)";
CM_ SG_ 342 TarLvlChg "New target level based on manual or automatic level change";
CM_ SG_ 359 ASCFltSts2 "Air spring control fault status";
CM_ SG_ 359 BatDamprModAllwd2 "Battle Damping Mode Allowed";
CM_ SG_ 359 CDCFltSts2 "Continuous Daming control fault status";
CM_ SG_ 359 CmftDamprModAllwd2 "Comfort Damping Mode Allowed";
CM_ SG_ 359 CurDampgCtrlMod2 "Current active damping control mode";
CM_ SG_ 359 ESPEnaReq2 "ESC OFF NOT ALLOWED";
CM_ SG_ 359 LvlCtrlCalCompl2 "Level control (HeightSensor) calibration completed";
CM_ SG_ 359 LvlModAct2 "Height Level Mode Actual";
CM_ SG_ 359 NormDamprModAllwd2 "Normal Damping Mode Allowed";
CM_ SG_ 359 SCUActvAwakeReq "SCU active powermode awake request.
SCU请求电源模式awake";
CM_ SG_ 359 SCUExtmHeiSts2 "SCU Extreme Height Status
SCU 悬架极高极低状态";
CM_ SG_ 359 SCULimSpdTqReq2 "SCU 限速限扭请求
SCU Limit Speed Torque Request";
CM_ SG_ 359 SCUWarnLampReq2 "SCU Warning Lamp Request
SCU 故障灯请求";
CM_ SG_ 359 SCUWarnMsgASC2 "SCU Warning Message ASC
空气悬架故障警示信号";
CM_ SG_ 359 SCUWarnMsgCDC2 "SCU Warning Message CDC
电控减震器故障警示信号";
CM_ SG_ 359 SprgRateSts2 "Spring Rate Status of Dual Chamber Air Spring";
CM_ SG_ 359 SprgRateStsVld2 "Spring Rate Status Valid 
空簧刚度有效性";
CM_ SG_ 359 SptDamprModAllwd2 "Sport Damping Mode Allowed";
CM_ SG_ 699 SCUBFaultInfoFlag "SCUB Fault Information Flag";
CM_ SG_ 1000 AccumIntkAirM "Accumulated intake airmass
累计进入系统的气量";
CM_ SG_ 1000 AccumNrFillg "Accumulated number of filling
累计补气次数";
CM_ SG_ 1000 AccumWtrIntkWght "Accumulated water intake weight
累计进入系统的水量";
CM_ SG_ 1000 AsuCrtlDataClctReq "ASU control data big data collect request
ASU控制大数据采集请求";
CM_ SG_ 1000 AsuCrtlDataClctSts "ASU control big data collect status
ASU控制大数据采集状态";
CM_ SG_ 1000 ASULftDataClctReq "ASU Lifetime data collect request
ASU 关键零部件大数据采集请求";
CM_ SG_ 1000 CmpOperModCntrDwnLvlg "Compressor operating mode counter of down leveling
压缩机运行在悬架下降调节模式中的次数";
CM_ SG_ 1000 CmpOperModCntrOvfDwnLvlg "Compressor operating mode counter of down leveling
压缩机运行在悬架Overflow下降调节模式中的次数";
CM_ SG_ 1000 CmpOperModCntrOvfUpLvlg "Compressor operating mode counter of up leveling
压缩机运行在悬架Overflow上升调节模式中的次数";
CM_ SG_ 1000 CmpOperModCntrResvFillg "Compressor operating mode counter of reservoir filling
压缩机运行在储气罐充气模式中的次数";
CM_ SG_ 1000 CmpOperModCntrUpLvlg "Compressor operating mode counter of up leveling
压缩机运行在悬架上升调节模式中的次数";
CM_ SG_ 1000 CmpRtCntrDwnLvlg "Compressor runtime counter of down leveling
压缩机运行在悬架下降调节总时长";
CM_ SG_ 1000 CmpRtCntrTot "Compressor runtime counter total
压缩机运行总时长";
CM_ SG_ 1000 CmpRtCntrTotResvFillg "Compressor runtime counter of reservoir filling
压缩机运行在储气罐充气总时长";
CM_ SG_ 1000 CmpRtCntrUpLvlg "Compressor runtime counter of up leveling
压缩机运行在悬架上升调节总时长";
CM_ SG_ 1000 CtrlActnFbAvFL "Control Action Feedback of air valve FL 
左前空气阀动作反馈";
CM_ SG_ 1000 CtrlActnFbAvFR "Control Action Feedback of air valve FR 
右前空气阀动作反馈";
CM_ SG_ 1000 CtrlActnFbAvRL "Control Action Feedback of air valve RL 
左后空气阀动作反馈";
CM_ SG_ 1000 CtrlActnFbAvRR "Control Action Feedback of air valve RR 
右后空气阀动作反馈";
CM_ SG_ 1000 CtrlActnFbEv "Control Action Feedback of exhaust valve 
EV排气阀动作反馈";
CM_ SG_ 1000 CtrlActnFbMot "Control Action Feedback of motor 
电机控制动作反馈";
CM_ SG_ 1000 CtrlActnFbSv1 "Control Action Feedback of switch valve 1 
SV1换向阀动作反馈";
CM_ SG_ 1000 CtrlActnFbSv2 "Control Action Feedback of switch valve 2 
SV2换向阀动作反馈";
CM_ SG_ 1000 CtrlActnFbSv3 "Control Action Feedback of switch valve 3 
SV3换向阀动作反馈";
CM_ SG_ 1000 CtrlActnFbSv4 "Control Action Feedback of switch valve 4 
SV4换向阀动作反馈";
CM_ SG_ 1000 NrActvnAv1Vlv "Number of activations of AV1 valve
AV1 阀开启次数统计";
CM_ SG_ 1000 NrActvnAv2Vlv "Number of activations of AV2 valve
AV2 阀开启次数统计";
CM_ SG_ 1000 NrActvnAv3Vlv "Number of activations of AV3 valve
AV3 阀开启次数统计";
CM_ SG_ 1000 NrActvnAv4Vlv "Number of activations of AV4 valve
AV4 阀开启次数统计";
CM_ SG_ 1000 NrActvnCmp "Number of activations of Compressor
压缩机开启次数统计";
CM_ SG_ 1000 NrActvnEvVlv "Number of activations of EV valve
EV 阀开启次数统计";
CM_ SG_ 1000 NrActvnSv1Vlv "Number of activations of SV1 valve
SV1 阀开启次数统计";
CM_ SG_ 1000 NrActvnSv2Vlv "Number of activations of SV2 valve
SV3 阀开启次数统计";
CM_ SG_ 1000 NrActvnSv3Vlv "Number of activations of SV3 valve
SV3 阀开启次数统计";
CM_ SG_ 1000 NrActvnSv4Vlv "Number of activations of SV4 valve
SV4 阀开启次数统计";
CM_ SG_ 1000 PrsntAirMData "Present airmass data
当前空簧系统气量";
CM_ SG_ 1000 PrsntLoadData "Present load data
当前车辆计算载荷";
CM_ SG_ 1000 ScuAcMode "SCU Actuator Mode
SCU执行器模式";
CM_ SG_ 1000 SuspAirMDataClctReq "Suspension air mass data big data collect request
空簧系统气量大数据采集请求";
CM_ SG_ 1000 SuspAirMDataClctSts "Suspension airmass data big data collect status
空簧系统Airmass管理大数据采集状态";
CM_ SG_ 1000 SuspClctCurAmbHum "Suspension collected current ambient humidity
悬架系统采集的当前环境湿度";
CM_ SG_ 1000 SuspClctCurAmbPSOA "Suspension collected current atmosphere pressure from SOA
天气预报大气压";
CM_ SG_ 1000 SuspClctCurAmbT "Suspension collected current ambient temperature
悬架系统采集的当前环境温度";
CM_ SG_ 1000 SuspClctCurAmbTSOA "Suspension collected current ambient temperature from SOA
天气预报温度情况";
CM_ SG_ 1000 SuspWthrFcstAuthnSts "Suspension weather forecast authorization status
悬架天气预报授权信号";
CM_ SG_ 1446 SCUEvntTrackFrame1Byte0to3 "SCU Event Tracking Frame 1 Byte 0 to 3";
CM_ SG_ 1446 SCUEvntTrackFrame1Byte12to15 "SCU Event Tracking Frame 1 Byte 12 to 15";
CM_ SG_ 1446 SCUEvntTrackFrame1Byte16to19 "SCU Event Tracking Frame 1 Byte 16 to 19";
CM_ SG_ 1446 SCUEvntTrackFrame1Byte20to23 "SCU Event Tracking Frame 1 Byte 20 to 23";
CM_ SG_ 1446 SCUEvntTrackFrame1Byte24to27 "SCU Event Tracking Frame 1 Byte 24 to 27";
CM_ SG_ 1446 SCUEvntTrackFrame1Byte28to31 "SCU Event Tracking Frame 1 Byte 28 to 31";
CM_ SG_ 1446 SCUEvntTrackFrame1Byte4to7 "SCU Event Tracking Frame 1 Byte 4 to 7";
CM_ SG_ 1446 SCUEvntTrackFrame1Byte8to11 "SCU Event Tracking Frame 1 Byte 8 to 11";
CM_ SG_ 156 RtcWake1AjustStsFL "RTC第1次唤醒是否调节 FL";
CM_ SG_ 156 RtcWake1AjustStsFR "RTC第1次唤醒是否调节 FR";
CM_ SG_ 156 RtcWake1AjustStsRL "RTC第1次唤醒是否调节 RL";
CM_ SG_ 156 RtcWake1AjustStsRR "RTC第1次唤醒是否调节 RR";
CM_ SG_ 156 RtcWake1DateTimeDay "RTC第1次唤醒时间日";
CM_ SG_ 156 RtcWake1DateTimeHr "RTC第1次唤醒时间小时";
CM_ SG_ 156 RtcWake1DateTimeMins "RTC第1次唤醒时间分钟";
CM_ SG_ 156 RtcWake1DateTimeMth "RTC第1次唤醒时间月";
CM_ SG_ 156 RtcWake1DateTimeYr "RTC第1次唤醒时间年";
CM_ SG_ 156 RtcWake1HeightFL "RTC第1次唤醒空簧高度FL";
CM_ SG_ 156 RtcWake1HeightFR "RTC第1次唤醒空簧高度FR";
CM_ SG_ 156 RtcWake1HeightRL "RTC第1次唤醒空簧高度RL";
CM_ SG_ 156 RtcWake1HeightRR "RTC第1次唤醒空簧高度RR";
CM_ SG_ 156 RtcWake1Valid "RTC第1次唤醒有效位";
CM_ SG_ 156 RtcWake2AjustStsFL "RTC第2次唤醒是否调节 FL";
CM_ SG_ 156 RtcWake2AjustStsFR "RTC第2次唤醒是否调节 FR";
CM_ SG_ 156 RtcWake2AjustStsRL "RTC第2次唤醒是否调节 RL";
CM_ SG_ 156 RtcWake2AjustStsRR "RTC第2次唤醒是否调节 RR";
CM_ SG_ 156 RtcWake2DateTimeDay "RTC第2次唤醒时间日";
CM_ SG_ 156 RtcWake2DateTimeHr "RTC第2次唤醒时间小时";
CM_ SG_ 156 RtcWake2DateTimeMins "RTC第2次唤醒时间分钟";
CM_ SG_ 156 RtcWake2DateTimeMth "RTC第2次唤醒时间月";
CM_ SG_ 156 RtcWake2DateTimeYr "RTC第2次唤醒时间年";
CM_ SG_ 156 RtcWake2HeightFL "RTC第2次唤醒空簧高度FL";
CM_ SG_ 156 RtcWake2HeightFR "RTC第2次唤醒空簧高度FR";
CM_ SG_ 156 RtcWake2HeightRL "RTC第2次唤醒空簧高度RL";
CM_ SG_ 156 RtcWake2HeightRR "RTC第2次唤醒空簧高度RR";
CM_ SG_ 156 RtcWake2Valid "RTC第2次唤醒有效位";
CM_ SG_ 156 RtcWake3AjustStsFL "RTC第3次唤醒是否调节 FL";
CM_ SG_ 156 RtcWake3AjustStsFR "RTC第3次唤醒是否调节 FR";
CM_ SG_ 156 RtcWake3AjustStsRL "RTC第3次唤醒是否调节 RL";
CM_ SG_ 156 RtcWake3AjustStsRR "RTC第3次唤醒是否调节 RR";
CM_ SG_ 156 RtcWake3DateTimeDay "RTC第3次唤醒时间日";
CM_ SG_ 156 RtcWake3DateTimeHr "RTC第3次唤醒时间小时";
CM_ SG_ 156 RtcWake3DateTimeMins "RTC第3次唤醒时间分钟";
CM_ SG_ 156 RtcWake3DateTimeMth "RTC第3次唤醒时间月";
CM_ SG_ 156 RtcWake3DateTimeYr "RTC第3次唤醒时间年";
CM_ SG_ 156 RtcWake3HeightFL "RTC第3次唤醒空簧高度FL";
CM_ SG_ 156 RtcWake3HeightFR "RTC第3次唤醒空簧高度FR";
CM_ SG_ 156 RtcWake3HeightRL "RTC第3次唤醒空簧高度RL";
CM_ SG_ 156 RtcWake3HeightRR "RTC第3次唤醒空簧高度RR";
CM_ SG_ 156 RtcWake3Valid "RTC第3次唤醒有效位";
CM_ SG_ 157 ScuIGOffDateTimeDay "SCU上次驾驶循环下电时间日";
CM_ SG_ 157 ScuIGOffDateTimeHr "SCU上次驾驶循环下电时间小时";
CM_ SG_ 157 ScuIGOffDateTimeMins "SCU上次驾驶循环下电时间分钟";
CM_ SG_ 157 ScuIGOffDateTimeMth "SCU上次驾驶循环下电时间月";
CM_ SG_ 157 ScuIGOffDateTimeYr "SCU上次驾驶循环下电时间年";
CM_ SG_ 157 ScuIGOffTargetFront "SCU上驾驶循环下电空簧前轴目标高度";
CM_ SG_ 157 ScuIGOffTargetRear "SCU上驾驶循环下电空簧后轴目标高度";
CM_ SG_ 157 ScuIGOffTime "SCU上次循环下电休眠总时间";
CM_ SG_ 182 AccrSnsrAzFrntLe "Front left sensor vertical acceleration";
CM_ SG_ 182 AccrSnsrAzFrntRi "Front right sensor vertical acceleration";
CM_ SG_ 182 AccrSnsrAzRe "Rear sensor vertical acceleration";
CM_ SG_ 182 BodyVertVFL "Body vertical velocity front left corner
左前车身垂向速度";
CM_ SG_ 182 BodyVertVFR "Body vertical velocity front right corner
右前车身垂向速度";
CM_ SG_ 182 BodyVertVRL "Body vertical velocity rear left corner
左后车身垂向速度";
CM_ SG_ 182 BodyVertVRR "Body vertical velocity rear right corner
右后车身垂向速度";
CM_ SG_ 182 DamprCurFrntLe "Suspension damper current Front Left";
CM_ SG_ 182 DamprCurFrntRi "Suspension damper current Front Right";
CM_ SG_ 182 DamprCurReLe "Suspension damper current Rear Left";
CM_ SG_ 182 DamprCurReqFL "Damper current request front left";
CM_ SG_ 182 DamprCurReqFR "Damper current request front right";
CM_ SG_ 182 DamprCurReqRL "Damper current request rear left";
CM_ SG_ 182 DamprCurReqRR "Damper current request rear right";
CM_ SG_ 182 DamprCurReRi "Suspension damper current Rear Right";
CM_ SG_ 182 FrntLeCurHei "Front Left Current Height";
CM_ SG_ 182 FrntLeCurHeiSts "Front Left Current Height status";
CM_ SG_ 182 FrntRiCurHei "Front Right Current Height";
CM_ SG_ 182 FrntRiCurHeiSts "Front Right Current Height status";
CM_ SG_ 182 ReLeCurHei "Rear Left Current Height";
CM_ SG_ 182 ReLeCurHeiSts "Rear Left Current Height status";
CM_ SG_ 182 ReRiCurHei "Rear Right Current Height";
CM_ SG_ 182 ReRiCurHeiSts "Rear Right Current Height status";
CM_ SG_ 192 BodyVertVFL2 "Body vertical velocity front left corner
左前车身垂向速度";
CM_ SG_ 192 BodyVertVFR2 "Body vertical velocity front right corner
右前车身垂向速度";
CM_ SG_ 192 BodyVertVRL2 "Body vertical velocity rear left corner
左后车身垂向速度";
CM_ SG_ 192 BodyVertVRR2 "Body vertical velocity rear right corner
右后车身垂向速度";
CM_ SG_ 192 FrntLeCurHei2 "Front Left Current Height";
CM_ SG_ 192 FrntLeCurHeiSts2 "Front Left Current Height status";
CM_ SG_ 192 FrntRiCurHei2 "Front Right Current Height";
CM_ SG_ 192 FrntRiCurHeiSts2 "Front Right Current Height status";
CM_ SG_ 192 ReLeCurHei2 "Rear Left Current Height";
CM_ SG_ 192 ReLeCurHeiSts2 "Rear Left Current Height status";
CM_ SG_ 192 ReRiCurHei2 "Rear Right Current Height";
CM_ SG_ 192 ReRiCurHeiSts2 "Rear Right Current Height status";
CM_ SG_ 1323 SCUChassisCanfdActiveWakeup "Active Wakeup Bit";
CM_ SG_ 1323 SCUChassisCanfdNodeAddress "Node source address";
CM_ SG_ 1323 SCUChassisCanfdRepeatMsgReq "Repeat Message Request Bit";
CM_ SG_ 1323 SCUChassisCanfdRepeatMsgSt "Repeat Message State indication";
CM_ SG_ 419 ColShiftLvrDiagc "组合开关档位有效性";
CM_ SG_ 419 DrvrGearShiftParkReq "组合开关P档Push请求";
CM_ SG_ 419 GearShiftPosReq "组合开关怀挡拨杆位置";
CM_ SG_ 419 RearWiprPushSwt "后雨刮硬开关";
CM_ SG_ 419 SWMFaultInfoFlag "SWM Fault Information Flag";
CM_ SG_ 419 SwtHiBeam "组合开关远光灯请求命令";
CM_ SG_ 419 SwtIndcrRaw "组合开关转向灯请求命令";
CM_ SG_ 419 WiprPushSwt "组合开关雨刮Push按键";
CM_ SG_ 1319 SWMActiveWakeup "Active Wakeup Bit";
CM_ SG_ 1319 SWMNodeAddress "Node source address";
CM_ SG_ 1319 SWMRepeatMsgReq "Repeat Message Request Bit";
CM_ SG_ 1319 SWMRepeatMsgSt "Repeat Message State indication";
CM_ SG_ 263 DateTiDay "date time day";
CM_ SG_ 263 DateTiHr "date time hour";
CM_ SG_ 263 DateTiMilsec "date time millisecond";
CM_ SG_ 263 DateTiMins "date time minute";
CM_ SG_ 263 DateTiMth "date time month";
CM_ SG_ 263 DateTiSec "date time second";
CM_ SG_ 263 DateTiYr "date time year";
CM_ SG_ 263 TiDomn "time domain";
CM_ SG_ 345 DiagcExtActv "diagnostic external connection activation";
CM_ SG_ 345 profileRestoreFactoryReqSoa "Restore factory Settings signals from Soa
Soa的恢复出厂设置信号";
CM_ SG_ 529 SecOCMAC1 "消息认证码1";
CM_ SG_ 529 SecOCMAC2 "消息认证码2";
CM_ SG_ 529 SecOCMAC3 "消息认证码3";
CM_ SG_ 529 SecOCResetCnt "重置计数器";
CM_ SG_ 529 SecOCTripCnt "同步计数器";
CM_ SG_ 549 ADSELKSwtSet "紧急车道保持开关
ADS ELK switch set";
CM_ SG_ 549 ADSFltQuitReqFrmDCD "路面感知系统 SR 监控上游模块失活,请求智驾功能降级";
CM_ SG_ 549 DCDAvmFrCamSts "DCD AVM Front Camera Status";
CM_ SG_ 549 DCDAvmLeCamSts "DCD AVM Left Camera Status";
CM_ SG_ 549 DCDAvmReCamSts "DCD AVM Rear Camera Status";
CM_ SG_ 549 DCDAvmRiCamSts "DCD AVM Rear Camera Status";
CM_ SG_ 549 DCDDisplayFailSts "Center Display Fail Status
座舱中控显示失效状态";
CM_ SG_ 549 DCDDltAllKeyCmd "Delete all Mobile NFC or BLE key";
CM_ SG_ 549 ExtrLiFcnSet "Exterior Light Function Set
外灯功能设定";
CM_ SG_ 549 WiprSpdAdjCfgSet "Wiper Control adjust configuration Set
雨刮控制设定";
CM_ SG_ 864 DCDICVehSrvAuthntSts "网联车系统服务授权状态
Intelligent Connected Vehicle  Service Authorization status";
CM_ SG_ 864 VehInsSpdDisp "Vehicle instantaneous speed display";
CM_ SG_ 864 VehInsSpdDispVld "Vehicle instantaneous speed display Valid";
CM_ SG_ 910 SuspHeiSetSoa "Suspension Height Set
 悬架高度设定";
CM_ SG_ 914 TotOdoAcrt "ODO";
CM_ SG_ 914 TotOdoAcrtLvlM "Total odometer accurate for meter level
米级精确总里程
其中，有效范围：0x0~0x?3B9AC9FF?，表示0~999,999,999";
CM_ SG_ 914 TotOdoAcrtLvlMVld "Total odometer accurate for meter level valid
米级精确总里程有效性";
CM_ SG_ 914 TotOdoAcrtVld "The valid signal of TotOdoAcrt";
CM_ SG_ 914 XCDbkdHvBattStrtAllwd "Arriving HV batter book heating time flag
到达电池预热时间使能标志位";
CM_ SG_ 931 AVHBtn "AVH Button
AVH控制按键";
CM_ SG_ 931 AVHSet "AVH function set
AVH功能设定";
CM_ SG_ 931 CSTOnOffBtn "CST On Off Button
舒适制动功能按键状态";
CM_ SG_ 931 CSTOnOffSet "CST function set
舒适制动功能设定";
CM_ SG_ 931 DCDBattHlthMngtFcnSwt "DCD Battery Health Management Function Switch";
CM_ SG_ 931 DCDEasyEntryHeiSet "Suspension height set for EasyEntry mode.
轻松进入悬架高度设置.";
CM_ SG_ 931 DCDHDCSet "HDC function set";
CM_ SG_ 931 DCDJackModSet "Level Control deactivation  Jack mode  set. 
千斤顶模式设置.";
CM_ SG_ 931 DCDStdLvlSpdSwt "Standard Level Speed depending switch.
悬架高度随速调节功能开关.";
CM_ SG_ 931 EasyEntryModReqBtn "Easy Entry Mode Request Button
轻松进入模式按键";
CM_ SG_ 931 EasyEntryModSet "Easy Entry Mode Set
轻松进入模式设定";
CM_ SG_ 931 EasyLoadgFuncCouplSet "Easy Loading Function Coupling with back door set
轻松载物与后背门功能联动设定";
CM_ SG_ 931 EasyLoadgModReqBtn "Easy Loading Mode Request Button
轻松载物模式按键";
CM_ SG_ 931 EasyLoadgModSet "Easy Loading Mode Set
轻松载物模式设定";
CM_ SG_ 931 EPBSwtSet "EPB Switch set";
CM_ SG_ 931 ESCOffSet "Set ESC Off
ESC功能关闭设定";
CM_ SG_ 931 SuspHeiSet "Suspension Height Set
悬架高度设定";
CM_ SG_ 997 CurAmbHumSoa "Current ambient humidity from internet based on vehicle location.
根据车辆位置从云端获取的环境湿度";
CM_ SG_ 997 CurAmbHumValSoa "Validity of Current ambient humidity from internet based on vehicle location.
根据车辆位置从云端获取的环境湿度可用性";
CM_ SG_ 997 CurAmbTSoa "Current ambient temperature from internet based on vehicle location.
根据车辆位置从云端获取的当前环境温度";
CM_ SG_ 997 CurAmbTValSoa "Validity of Current ambient temperature from internet based on vehicle location.
根据车辆位置从云端获取的当前环境温度可用性";
CM_ SG_ 997 LowtAmbTTomwSoa "Lowest ambient temperature from internet based on vehicle location  for tomorrow
根据车辆位置从云端获取的明天环境最低温度";
CM_ SG_ 997 LowtAmbTTomwValSoa "Validity of Lowest ambient temperature from internet based on vehicle location  for tomorrow
根据车辆位置从云端获取的明天环境最低温度值可用性";
CM_ SG_ 1023 VidBlkId "Block ID for VID Signal sequence";
CM_ SG_ 1023 VidSignalPos1 "1st position in VID Signal - Block ID dependant";
CM_ SG_ 1023 VidSignalPos2 "2st position in VID Signal - Block ID dependant";
CM_ SG_ 1023 VidSignalPos3 "3st position in VID Signal - Block ID dependant";
CM_ SG_ 1023 VidSignalPos4 "4st position in VID Signal - Block ID dependant";
CM_ SG_ 1023 VidSignalPos5 "5st position in VID Signal - Block ID dependant";
CM_ SG_ 1023 VidSignalPos6 "6st position in VID Signal - Block ID dependant";
CM_ SG_ 1023 VidSignalPos7 "7st position in VID Signal - Block ID dependant";
CM_ SG_ 1023 VinVINBlkID "Block ID for VIN Signal sequence";
CM_ SG_ 1023 VinVINSignalPos1 "1st position in VIN Signal    Block ID dependant";
CM_ SG_ 1023 VinVINSignalPos2 "2nd position in VIN Signal   Block ID dependant";
CM_ SG_ 1023 VinVINSignalPos3 "3rd position in VIN Signal   Block ID dependant";
CM_ SG_ 1023 VinVINSignalPos4 "4th position in VIN Signal   Block ID dependant";
CM_ SG_ 1023 VinVINSignalPos5 "5th position in VIN Signal   Block ID dependant";
CM_ SG_ 1023 VinVINSignalPos6 "6th position in VIN Signal   Block ID dependant";
CM_ SG_ 1023 VinVINSignalPos7 "7th position in VIN Signal   Block ID dependant";
CM_ SG_ 135 VehCfgPrmBlkIDBytePosn1 "Block ID for specific Car Configuration parameter sequence";
CM_ SG_ 135 VehCfgPrmCCPBytePosn2 "1st position in specific CCP number sequence   Block ID dependant";
CM_ SG_ 135 VehCfgPrmCCPBytePosn3 "2nd position in specific CCP number sequence   Block ID dependant";
CM_ SG_ 135 VehCfgPrmCCPBytePosn4 "3rd position in specific CCP number sequence   Block ID dependant";
CM_ SG_ 135 VehCfgPrmCCPBytePosn5 "4th position in specific CCP number sequence   Block ID dependant";
CM_ SG_ 135 VehCfgPrmCCPBytePosn6 "5th position in specific CCP number sequence   Block ID dependant";
CM_ SG_ 135 VehCfgPrmCCPBytePosn7 "6th position in specific CCP number sequence   Block ID dependant";
CM_ SG_ 135 VehCfgPrmCCPBytePosn8 "7th position in specific CCP number sequence   Block ID dependant";
CM_ SG_ 389 AdasSwt "一键智驾开关";
CM_ SG_ 389 AdasSwtSigGrpLinErr "AdasSwtSigGrp LIN communication Error";
CM_ SG_ 389 ChrgLidSts "充电口盖打开状态显示";
CM_ SG_ 389 DoorDrvrSts "驾驶侧门状态";
CM_ SG_ 389 DoorLeReSts "左后侧门状态";
CM_ SG_ 389 DoorPassSts "副驾侧门状态";
CM_ SG_ 389 DoorRiReSts "右后侧门状态";
CM_ SG_ 389 HoodOpenClsSts "Hood Open Close Status
前舱盖开启关闭状态";
CM_ SG_ 389 LeKnobCounter "方向盘左滚轮滚动Counter值";
CM_ SG_ 389 LeKnobRotDir "方向盘左侧滚轮滚动方向
0x0 Idle
0x1 Up
0x2 Down";
CM_ SG_ 389 LeMFctActSgCe "方向盘面板左侧开关滚轮松压状态";
CM_ SG_ 389 LeMFctActSgLe "方向盘面板左侧开关区左侧按键状态";
CM_ SG_ 389 LeMFctActSgRi "方向盘面板左侧开关区右侧按键状态";
CM_ SG_ 389 RiMFctActSgCe "方向盘面板右侧开关滚轮松压状态";
CM_ SG_ 389 TrOpenClsSts "Trunk Open Close Status";
CM_ SG_ 520 ARSPosnSts "Active Rear Spoiler Position Status";
CM_ SG_ 520 HvBattSoCDisp "HV battery State Of Energy for HMI Display / 高压电池剩余可用能量百分比状态信息用于HMI人机交互显示";
CM_ SG_ 520 RlsLinComFltSts "Rls LIN node communication fault status.";
CM_ SG_ 768 FLRLLoPwrSplySts "FLRL Low Power Supply Status
长距激光雷达配电状态";
CM_ SG_ 768 FrntShdADCameraDefrstErrFb "前风挡玻璃局部除雾状态故障反馈";
CM_ SG_ 768 FrntShdADCameraDefrstSts "前风挡智驾摄像头加热状态";
CM_ SG_ 768 IMULoPwrSplySts "IMU Low Power Supply Status
IMU低压配电状态";
CM_ SG_ 768 LockgCenLockSts "中控锁状态";
CM_ SG_ 768 RSRLoPwrSplySts "RSR Low Power Supply Status
后毫米波雷达配电状态";
CM_ SG_ 1313 VCCDChassisBkpActiveWakeup "Active Wakeup Bit";
CM_ SG_ 1313 VCCDChassisBkpNodeAddress "Node source address";
CM_ SG_ 1313 VCCDChassisBkpRepeatMsgReq "Repeat Message Request Bit";
CM_ SG_ 1313 VCCDChassisBkpRepeatMsgSt "Repeat Message State indication";
CM_ SG_ 2047 VCCDToChassisBkpFuncDiagReq "VCCDToChassisBkpCanfdFuncDiagReqNpdu";
BA_DEF_ BO_  "CANFD_BRS" ENUM  "0","1";
BA_DEF_ BO_  "GenMsgCycleTime" FLOAT 0 300000;
BA_DEF_ BO_  "GenMsgCycleTimeFast" FLOAT 0 300000;
BA_DEF_ BO_  "GenMsgDelayTime" FLOAT 0 300000;
BA_DEF_ BO_  "GenMsgNrOfRepetition" INT 0 100000;
BA_DEF_ BO_  "GenMsgSendType" ENUM  "cyclic","spontaneous","cyclicIfActive","spontaneousWithDelay","cyclicAndSpontaneous","cyclicAndSpontaneousWithDelay","IfActive","NoMsgSendType";
BA_DEF_ BO_  "GenMsgStartDelayTime" FLOAT 0 300000;
BA_DEF_ BO_  "VFrameFormat" ENUM  "StandardCAN","ExtendedCAN","reserved","J1939PG","reserved","reserved","reserved","reserved","reserved","reserved","reserved","reserved","reserved","reserved","StandardCAN_FD","ExtendedCAN_FD";
BA_DEF_ SG_  "GenSigSendType" ENUM  "Cyclic","OnWrite","OnWriteWithRepetition","OnChange","OnChangeWithRepetition","IfActive","IfActiveWithRepetition","NoSigSendType";
BA_DEF_ SG_  "GenSigStartValue" FLOAT -1.79769313486232E+308 1.84467440737096E+019;
BA_DEF_ SG_  "SystemSignalLongSymbol" STRING ;
BA_DEF_DEF_  "CANFD_BRS" "1";
BA_DEF_DEF_  "GenMsgCycleTime" 0;
BA_DEF_DEF_  "GenMsgCycleTimeFast" 0;
BA_DEF_DEF_  "GenMsgDelayTime" 0;
BA_DEF_DEF_  "GenMsgNrOfRepetition" 0;
BA_DEF_DEF_  "GenMsgSendType" "";
BA_DEF_DEF_  "GenMsgStartDelayTime" 0;
BA_DEF_DEF_  "VFrameFormat" "J1939PG";
BA_DEF_DEF_  "GenSigSendType" "Cyclic";
BA_DEF_DEF_  "GenSigStartValue" 0;
BA_DEF_DEF_  "SystemSignalLongSymbol" "";
BA_ "GenMsgCycleTime" BO_ 186 10;
BA_ "GenMsgSendType" BO_ 186 0;
BA_ "VFrameFormat" BO_ 186 14;
BA_ "GenMsgCycleTime" BO_ 190 10;
BA_ "GenMsgSendType" BO_ 190 0;
BA_ "VFrameFormat" BO_ 190 14;
BA_ "GenMsgDelayTime" BO_ 1315 20;
BA_ "GenMsgSendType" BO_ 1315 1;
BA_ "VFrameFormat" BO_ 1315 0;
BA_ "GenMsgCycleTime" BO_ 444 20;
BA_ "GenMsgSendType" BO_ 444 0;
BA_ "VFrameFormat" BO_ 444 14;
BA_ "GenMsgCycleTime" BO_ 657 50;
BA_ "GenMsgSendType" BO_ 657 0;
BA_ "VFrameFormat" BO_ 657 14;
BA_ "GenMsgDelayTime" BO_ 663 5;
BA_ "GenMsgSendType" BO_ 663 1;
BA_ "VFrameFormat" BO_ 663 14;
BA_ "GenMsgCycleTime" BO_ 665 50;
BA_ "GenMsgSendType" BO_ 665 0;
BA_ "VFrameFormat" BO_ 665 14;
BA_ "GenMsgCycleTime" BO_ 758 100;
BA_ "GenMsgSendType" BO_ 758 0;
BA_ "VFrameFormat" BO_ 758 14;
BA_ "GenMsgCycleTime" BO_ 817 50;
BA_ "GenMsgSendType" BO_ 817 0;
BA_ "VFrameFormat" BO_ 817 14;
BA_ "GenMsgDelayTime" BO_ 825 5;
BA_ "GenMsgSendType" BO_ 825 1;
BA_ "VFrameFormat" BO_ 825 14;
BA_ "GenMsgCycleTime" BO_ 826 50;
BA_ "GenMsgSendType" BO_ 826 0;
BA_ "VFrameFormat" BO_ 826 14;
BA_ "GenMsgDelayTime" BO_ 827 5;
BA_ "GenMsgSendType" BO_ 827 1;
BA_ "VFrameFormat" BO_ 827 14;
BA_ "GenMsgCycleTime" BO_ 579 50;
BA_ "GenMsgSendType" BO_ 579 0;
BA_ "VFrameFormat" BO_ 579 14;
BA_ "GenMsgCycleTime" BO_ 581 50;
BA_ "GenMsgSendType" BO_ 581 0;
BA_ "VFrameFormat" BO_ 581 14;
BA_ "GenMsgCycleTime" BO_ 912 500;
BA_ "GenMsgSendType" BO_ 912 0;
BA_ "VFrameFormat" BO_ 912 14;
BA_ "GenMsgCycleTime" BO_ 355 20;
BA_ "GenMsgSendType" BO_ 355 0;
BA_ "VFrameFormat" BO_ 355 14;
BA_ "GenMsgCycleTime" BO_ 994 1000;
BA_ "GenMsgSendType" BO_ 994 0;
BA_ "VFrameFormat" BO_ 994 14;
BA_ "GenMsgCycleTime" BO_ 181 10;
BA_ "GenMsgSendType" BO_ 181 0;
BA_ "VFrameFormat" BO_ 181 14;
BA_ "GenMsgCycleTime" BO_ 200 10;
BA_ "GenMsgSendType" BO_ 200 0;
BA_ "VFrameFormat" BO_ 200 14;
BA_ "GenMsgDelayTime" BO_ 1322 20;
BA_ "GenMsgSendType" BO_ 1322 1;
BA_ "VFrameFormat" BO_ 1322 0;
BA_ "GenMsgDelayTime" BO_ 1576 10;
BA_ "GenMsgSendType" BO_ 1576 1;
BA_ "VFrameFormat" BO_ 1576 14;
BA_ "GenMsgCycleTime" BO_ 347 20;
BA_ "GenMsgSendType" BO_ 347 0;
BA_ "VFrameFormat" BO_ 347 14;
BA_ "GenMsgCycleTime" BO_ 515 50;
BA_ "GenMsgSendType" BO_ 515 0;
BA_ "VFrameFormat" BO_ 515 14;
BA_ "GenMsgDelayTime" BO_ 533 10;
BA_ "GenMsgSendType" BO_ 533 1;
BA_ "VFrameFormat" BO_ 533 14;
BA_ "GenMsgCycleTime" BO_ 656 100;
BA_ "GenMsgSendType" BO_ 656 0;
BA_ "VFrameFormat" BO_ 656 14;
BA_ "GenMsgCycleTime" BO_ 144 10;
BA_ "GenMsgSendType" BO_ 144 0;
BA_ "VFrameFormat" BO_ 144 14;
BA_ "GenMsgCycleTime" BO_ 188 10;
BA_ "GenMsgSendType" BO_ 188 0;
BA_ "VFrameFormat" BO_ 188 14;
BA_ "GenMsgDelayTime" BO_ 1403 20;
BA_ "GenMsgSendType" BO_ 1403 1;
BA_ "VFrameFormat" BO_ 1403 0;
BA_ "GenMsgCycleTime" BO_ 607 50;
BA_ "GenMsgSendType" BO_ 607 0;
BA_ "VFrameFormat" BO_ 607 14;
BA_ "GenMsgCycleTime" BO_ 892 200;
BA_ "GenMsgSendType" BO_ 892 0;
BA_ "VFrameFormat" BO_ 892 14;
BA_ "GenMsgCycleTime" BO_ 616 50;
BA_ "GenMsgSendType" BO_ 616 0;
BA_ "VFrameFormat" BO_ 616 14;
BA_ "GenMsgCycleTime" BO_ 893 200;
BA_ "GenMsgSendType" BO_ 893 0;
BA_ "VFrameFormat" BO_ 893 14;
BA_ "GenMsgCycleTime" BO_ 342 20;
BA_ "GenMsgSendType" BO_ 342 0;
BA_ "VFrameFormat" BO_ 342 14;
BA_ "GenMsgCycleTime" BO_ 359 20;
BA_ "GenMsgSendType" BO_ 359 0;
BA_ "VFrameFormat" BO_ 359 14;
BA_ "GenMsgCycleTime" BO_ 699 1000;
BA_ "GenMsgCycleTimeFast" BO_ 699 100;
BA_ "GenMsgNrOfRepetition" BO_ 699 3;
BA_ "GenMsgSendType" BO_ 699 4;
BA_ "VFrameFormat" BO_ 699 14;
BA_ "GenMsgDelayTime" BO_ 1000 10;
BA_ "GenMsgSendType" BO_ 1000 1;
BA_ "VFrameFormat" BO_ 1000 14;
BA_ "GenMsgDelayTime" BO_ 1446 5;
BA_ "GenMsgSendType" BO_ 1446 1;
BA_ "VFrameFormat" BO_ 1446 14;
BA_ "GenMsgDelayTime" BO_ 156 10;
BA_ "GenMsgSendType" BO_ 156 1;
BA_ "VFrameFormat" BO_ 156 14;
BA_ "GenMsgDelayTime" BO_ 157 10;
BA_ "GenMsgSendType" BO_ 157 1;
BA_ "VFrameFormat" BO_ 157 14;
BA_ "GenMsgCycleTime" BO_ 182 10;
BA_ "GenMsgSendType" BO_ 182 0;
BA_ "VFrameFormat" BO_ 182 14;
BA_ "GenMsgCycleTime" BO_ 192 10;
BA_ "GenMsgSendType" BO_ 192 0;
BA_ "VFrameFormat" BO_ 192 14;
BA_ "GenMsgDelayTime" BO_ 1323 20;
BA_ "GenMsgSendType" BO_ 1323 1;
BA_ "VFrameFormat" BO_ 1323 0;
BA_ "GenMsgDelayTime" BO_ 1572 10;
BA_ "GenMsgSendType" BO_ 1572 1;
BA_ "VFrameFormat" BO_ 1572 14;
BA_ "GenMsgCycleTime" BO_ 419 20;
BA_ "GenMsgSendType" BO_ 419 0;
BA_ "VFrameFormat" BO_ 419 14;
BA_ "GenMsgDelayTime" BO_ 1319 20;
BA_ "GenMsgSendType" BO_ 1319 1;
BA_ "VFrameFormat" BO_ 1319 0;
BA_ "GenMsgDelayTime" BO_ 1573 10;
BA_ "GenMsgSendType" BO_ 1573 1;
BA_ "VFrameFormat" BO_ 1573 14;
BA_ "GenMsgDelayTime" BO_ 1761 10;
BA_ "GenMsgSendType" BO_ 1761 1;
BA_ "VFrameFormat" BO_ 1761 14;
BA_ "GenMsgDelayTime" BO_ 1286 20;
BA_ "GenMsgSendType" BO_ 1286 1;
BA_ "VFrameFormat" BO_ 1286 0;
BA_ "GenMsgCycleTime" BO_ 263 100;
BA_ "GenMsgSendType" BO_ 263 0;
BA_ "VFrameFormat" BO_ 263 14;
BA_ "GenMsgCycleTime" BO_ 345 20;
BA_ "GenMsgSendType" BO_ 345 0;
BA_ "VFrameFormat" BO_ 345 14;
BA_ "GenMsgDelayTime" BO_ 529 2;
BA_ "GenMsgSendType" BO_ 529 1;
BA_ "VFrameFormat" BO_ 529 14;
BA_ "GenMsgCycleTime" BO_ 549 50;
BA_ "GenMsgSendType" BO_ 549 0;
BA_ "VFrameFormat" BO_ 549 14;
BA_ "GenMsgCycleTime" BO_ 864 200;
BA_ "GenMsgSendType" BO_ 864 0;
BA_ "VFrameFormat" BO_ 864 14;
BA_ "GenMsgDelayTime" BO_ 910 10;
BA_ "GenMsgSendType" BO_ 910 1;
BA_ "VFrameFormat" BO_ 910 14;
BA_ "GenMsgCycleTime" BO_ 914 500;
BA_ "GenMsgSendType" BO_ 914 0;
BA_ "VFrameFormat" BO_ 914 14;
BA_ "GenMsgCycleTime" BO_ 931 1000;
BA_ "GenMsgCycleTimeFast" BO_ 931 40;
BA_ "GenMsgNrOfRepetition" BO_ 931 3;
BA_ "GenMsgSendType" BO_ 931 4;
BA_ "VFrameFormat" BO_ 931 14;
BA_ "GenMsgCycleTime" BO_ 997 1000;
BA_ "GenMsgSendType" BO_ 997 0;
BA_ "VFrameFormat" BO_ 997 14;
BA_ "GenMsgCycleTime" BO_ 1023 1000;
BA_ "GenMsgSendType" BO_ 1023 0;
BA_ "VFrameFormat" BO_ 1023 14;
BA_ "GenMsgDelayTime" BO_ 135 10;
BA_ "GenMsgSendType" BO_ 135 1;
BA_ "VFrameFormat" BO_ 135 14;
BA_ "GenMsgCycleTime" BO_ 389 20;
BA_ "GenMsgSendType" BO_ 389 0;
BA_ "VFrameFormat" BO_ 389 14;
BA_ "GenMsgCycleTime" BO_ 520 50;
BA_ "GenMsgSendType" BO_ 520 0;
BA_ "VFrameFormat" BO_ 520 14;
BA_ "GenMsgCycleTime" BO_ 768 100;
BA_ "GenMsgSendType" BO_ 768 0;
BA_ "VFrameFormat" BO_ 768 14;
BA_ "GenMsgDelayTime" BO_ 1313 20;
BA_ "GenMsgSendType" BO_ 1313 1;
BA_ "VFrameFormat" BO_ 1313 0;
BA_ "GenMsgDelayTime" BO_ 2047 2;
BA_ "GenMsgSendType" BO_ 2047 1;
BA_ "VFrameFormat" BO_ 2047 14;
BA_ "GenMsgDelayTime" BO_ 1832 2;
BA_ "GenMsgSendType" BO_ 1832 1;
BA_ "VFrameFormat" BO_ 1832 14;
BA_ "GenMsgDelayTime" BO_ 1828 10;
BA_ "GenMsgSendType" BO_ 1828 1;
BA_ "VFrameFormat" BO_ 1828 14;
BA_ "GenMsgDelayTime" BO_ 1829 10;
BA_ "GenMsgSendType" BO_ 1829 1;
BA_ "VFrameFormat" BO_ 1829 14;
BA_ "GenMsgDelayTime" BO_ 1760 10;
BA_ "GenMsgSendType" BO_ 1760 1;
BA_ "VFrameFormat" BO_ 1760 14;
BA_ "GenSigStartValue" SG_ 186 BrkSysMstCylP 100;
BA_ "SystemSignalLongSymbol" SG_ 190 BrkSysAPCMain2BkpStCom2SigGrpChk "BrkSysAPCMain2BkpStCom2SigGrpChks";
BA_ "SystemSignalLongSymbol" SG_ 190 BrkSysAPCMain2BkpStCom2SigGrpCnt "BrkSysAPCMain2BkpStCom2SigGrpCntr";
BA_ "GenSigStartValue" SG_ 190 RPBMstCylP 100;
BA_ "GenSigSendType" SG_ 1315 BCSChassisBkpActiveWakeup 1;
BA_ "GenSigSendType" SG_ 1315 BCSChassisBkpNodeAddress 1;
BA_ "GenSigSendType" SG_ 1315 BCSChassisBkpRepeatMsgReq 1;
BA_ "GenSigSendType" SG_ 1315 BCSChassisBkpRepeatMsgSt 1;
BA_ "GenSigSendType" SG_ 1315 NMKeepAwkRsnBCS 1;
BA_ "GenSigSendType" SG_ 1315 UDB17BCS 1;
BA_ "GenSigSendType" SG_ 1315 UDB18BCS 1;
BA_ "GenSigSendType" SG_ 1315 UDB19BCS 1;
BA_ "GenSigSendType" SG_ 1315 UDB20BCS 1;
BA_ "GenSigSendType" SG_ 1315 UDB21BCS 1;
BA_ "GenSigSendType" SG_ 1315 UDB22BCS 1;
BA_ "GenSigSendType" SG_ 1315 UDB23BCS 1;
BA_ "GenSigSendType" SG_ 1315 UDB24BCS 1;
BA_ "GenSigSendType" SG_ 1315 UDB25BCS 1;
BA_ "GenSigSendType" SG_ 1315 UDB26BCS 1;
BA_ "GenSigSendType" SG_ 1315 UDB27BCS 1;
BA_ "GenSigSendType" SG_ 1315 UDB28BCS 1;
BA_ "GenSigSendType" SG_ 1315 UDB29BCS 1;
BA_ "GenSigSendType" SG_ 1315 UDB30BCS 1;
BA_ "GenSigSendType" SG_ 1315 UDB31BCS 1;
BA_ "GenSigSendType" SG_ 1315 UDB32BCS 1;
BA_ "GenSigSendType" SG_ 1315 UDB33BCS 1;
BA_ "GenSigSendType" SG_ 1315 UDB34BCS 1;
BA_ "GenSigSendType" SG_ 1315 UDB35BCS 1;
BA_ "GenSigSendType" SG_ 1315 UDB36BCS 1;
BA_ "GenSigSendType" SG_ 1315 UDB37BCS 1;
BA_ "GenSigSendType" SG_ 1315 UDB38BCS 1;
BA_ "GenSigSendType" SG_ 1315 UDB39BCS 1;
BA_ "GenSigSendType" SG_ 1315 UDB40BCS 1;
BA_ "GenSigSendType" SG_ 1315 UDB41BCS 1;
BA_ "GenSigSendType" SG_ 1315 UDB42BCS 1;
BA_ "GenSigSendType" SG_ 1315 UDB43BCS 1;
BA_ "GenSigSendType" SG_ 1315 UDB44BCS 1;
BA_ "GenSigSendType" SG_ 1315 UDB45BCS 1;
BA_ "GenSigSendType" SG_ 1315 UDB46BCS 1;
BA_ "GenSigSendType" SG_ 1315 UDB47BCS 1;
BA_ "GenSigSendType" SG_ 663 DltAllKeyFb 1;
BA_ "GenSigSendType" SG_ 663 DltAllKeyFbFV 1;
BA_ "GenSigSendType" SG_ 663 DltAllKeyFbMAC 1;
BA_ "GenSigSendType" SG_ 663 SndBLEKeyPosnToRPA 1;
BA_ "GenSigStartValue" SG_ 758 FrntLeTyrePVal 254;
BA_ "GenSigStartValue" SG_ 758 FrntRiTyrePVal 254;
BA_ "GenSigStartValue" SG_ 758 ReLeTyrePVal 254;
BA_ "GenSigStartValue" SG_ 758 ReRiTyrePVal 254;
BA_ "GenSigSendType" SG_ 825 BLEM2ADDForRPA00 1;
BA_ "GenSigSendType" SG_ 825 BLEM2ADDForRPA00FV 1;
BA_ "GenSigSendType" SG_ 825 BLEM2ADDForRPA00MAC 1;
BA_ "GenSigSendType" SG_ 825 BLEM2ADDForRPA01 1;
BA_ "GenSigSendType" SG_ 825 BLEM2ADDForRPA02 1;
BA_ "GenSigSendType" SG_ 825 BLEM2ADDForRPA03 1;
BA_ "GenSigSendType" SG_ 827 BLEM2VCCDForRkeReq00 1;
BA_ "GenSigSendType" SG_ 827 BLEM2VCCDForRkeReq01 1;
BA_ "GenSigSendType" SG_ 827 BLEM2VCCDForRkeReq02 1;
BA_ "GenSigSendType" SG_ 827 BLEM2VCCDForRkeReq03 1;
BA_ "GenSigSendType" SG_ 827 BLEM2VCCDForRkeReq04 1;
BA_ "GenSigSendType" SG_ 827 BLEM2VCCDForRkeReq05 1;
BA_ "GenSigSendType" SG_ 827 BLEM2VCCDForRkeReq06 1;
BA_ "GenSigSendType" SG_ 827 BLEM2VCCDForRkeReq07 1;
BA_ "GenSigSendType" SG_ 827 BLEM2VCCDForRkeReq08 1;
BA_ "GenSigSendType" SG_ 827 BLEM2VCCDForRkeReq09 1;
BA_ "GenSigSendType" SG_ 827 BLEM2VCCDForRkeReq10 1;
BA_ "GenSigSendType" SG_ 827 BLEM2VCCDForRkeReq11 1;
BA_ "GenSigSendType" SG_ 827 BLEM2VCCDForRkeReq12 1;
BA_ "GenSigSendType" SG_ 827 BLEM2VCCDForRkeReq13 1;
BA_ "GenSigSendType" SG_ 827 BLEM2VCCDForRkeReq14 1;
BA_ "GenSigSendType" SG_ 827 BLEM2VCCDForRkeReqFV 1;
BA_ "GenSigSendType" SG_ 827 BLEM2VCCDForRkeReqMAC 1;
BA_ "GenSigStartValue" SG_ 579 BattSocRaw 800;
BA_ "GenSigStartValue" SG_ 579 BattURaw 13200;
BA_ "GenSigStartValue" SG_ 581 BattSoh 900;
BA_ "GenSigStartValue" SG_ 912 HvBattCellMaxSocErrIdx 1;
BA_ "GenSigStartValue" SG_ 912 HvBattCellMaxSocIdx 1;
BA_ "GenSigStartValue" SG_ 912 HvBattCellMinSocIdx 1;
BA_ "GenSigStartValue" SG_ 994 CwEOTValueBkp 12480;
BA_ "GenSigSendType" SG_ 1322 EPSChassisBkpActiveWakeup 1;
BA_ "GenSigSendType" SG_ 1322 EPSChassisBkpNodeAddress 1;
BA_ "GenSigSendType" SG_ 1322 EPSChassisBkpRepeatMsgReq 1;
BA_ "GenSigSendType" SG_ 1322 EPSChassisBkpRepeatMsgSt 1;
BA_ "GenSigSendType" SG_ 1322 NMKeepAwkRsnEPS 1;
BA_ "GenSigSendType" SG_ 1322 UDB17EPS 1;
BA_ "GenSigSendType" SG_ 1322 UDB18EPS 1;
BA_ "GenSigSendType" SG_ 1322 UDB19EPS 1;
BA_ "GenSigSendType" SG_ 1322 UDB20EPS 1;
BA_ "GenSigSendType" SG_ 1322 UDB21EPS 1;
BA_ "GenSigSendType" SG_ 1322 UDB22EPS 1;
BA_ "GenSigSendType" SG_ 1322 UDB23EPS 1;
BA_ "GenSigSendType" SG_ 1322 UDB24EPS 1;
BA_ "GenSigSendType" SG_ 1322 UDB25EPS 1;
BA_ "GenSigSendType" SG_ 1322 UDB26EPS 1;
BA_ "GenSigSendType" SG_ 1322 UDB27EPS 1;
BA_ "GenSigSendType" SG_ 1322 UDB28EPS 1;
BA_ "GenSigSendType" SG_ 1322 UDB29EPS 1;
BA_ "GenSigSendType" SG_ 1322 UDB30EPS 1;
BA_ "GenSigSendType" SG_ 1322 UDB31EPS 1;
BA_ "GenSigSendType" SG_ 1322 UDB32EPS 1;
BA_ "GenSigSendType" SG_ 1322 UDB33EPS 1;
BA_ "GenSigSendType" SG_ 1322 UDB34EPS 1;
BA_ "GenSigSendType" SG_ 1322 UDB35EPS 1;
BA_ "GenSigSendType" SG_ 1322 UDB36EPS 1;
BA_ "GenSigSendType" SG_ 1322 UDB37EPS 1;
BA_ "GenSigSendType" SG_ 1322 UDB38EPS 1;
BA_ "GenSigSendType" SG_ 1322 UDB39EPS 1;
BA_ "GenSigSendType" SG_ 1322 UDB40EPS 1;
BA_ "GenSigSendType" SG_ 1322 UDB41EPS 1;
BA_ "GenSigSendType" SG_ 1322 UDB42EPS 1;
BA_ "GenSigSendType" SG_ 1322 UDB43EPS 1;
BA_ "GenSigSendType" SG_ 1322 UDB44EPS 1;
BA_ "GenSigSendType" SG_ 1322 UDB45EPS 1;
BA_ "GenSigSendType" SG_ 1322 UDB46EPS 1;
BA_ "GenSigSendType" SG_ 1322 UDB47EPS 1;
BA_ "GenSigSendType" SG_ 1576 EPSToVCCDChassisBkpDiagResp 1;
BA_ "GenSigStartValue" SG_ 347 MIACurAirDrgVal 1000;
BA_ "GenSigStartValue" SG_ 347 MIACurCdVal 240;
BA_ "GenSigSendType" SG_ 533 FZCUSyncFVReq1 1;
BA_ "GenSigStartValue" SG_ 656 VCUEgyCnsInCurDrvCyc 20000;
BA_ "GenSigStartValue" SG_ 144 PwrModSts 1;
BA_ "GenSigStartValue" SG_ 144 VCUDrvModSteerAsstPrmSts 3;
BA_ "GenSigStartValue" SG_ 144 VCUDrvModSuspDampgPrmSts 2;
BA_ "GenSigStartValue" SG_ 144 VCUDrvModSuspLvlgPrmSts 3;
BA_ "GenSigStartValue" SG_ 144 VCUFrntEmTqRdy 1;
BA_ "GenSigStartValue" SG_ 144 VCUReEmTqRdy 1;
BA_ "GenSigStartValue" SG_ 188 VCUFrntDesTqWoIntv 16383;
BA_ "GenSigStartValue" SG_ 188 VCUFrntMotActSpd 32767;
BA_ "GenSigStartValue" SG_ 188 VCUFrntMotActTq 16383;
BA_ "GenSigStartValue" SG_ 188 VCUFrntMotWhlTqReq 16383;
BA_ "GenSigStartValue" SG_ 188 VCUFrntWhlTqMinAvl 16383;
BA_ "GenSigStartValue" SG_ 188 VCUOperModFAOfDMC 2;
BA_ "GenSigStartValue" SG_ 188 VCUOperModRAOfDMC 2;
BA_ "GenSigStartValue" SG_ 188 VCUReDesTqWoIntv 16383;
BA_ "GenSigStartValue" SG_ 188 VCUReMotActSpd 32767;
BA_ "GenSigStartValue" SG_ 188 VCUReMotActTq 16383;
BA_ "GenSigStartValue" SG_ 188 VCUReMotWhlTqReq 16383;
BA_ "GenSigStartValue" SG_ 188 VCUReWhlTqMinAvl 16383;
BA_ "GenSigSendType" SG_ 1403 NMKeepAwkRsnFZCU 1;
BA_ "GenSigSendType" SG_ 1403 UDB17FZCU 1;
BA_ "GenSigSendType" SG_ 1403 UDB18FZCU 1;
BA_ "GenSigSendType" SG_ 1403 UDB19FZCU 1;
BA_ "GenSigSendType" SG_ 1403 UDB20FZCU 1;
BA_ "GenSigSendType" SG_ 1403 UDB21FZCU 1;
BA_ "GenSigSendType" SG_ 1403 UDB22FZCU 1;
BA_ "GenSigSendType" SG_ 1403 UDB23FZCU 1;
BA_ "GenSigSendType" SG_ 1403 UDB24FZCU 1;
BA_ "GenSigSendType" SG_ 1403 UDB25FZCU 1;
BA_ "GenSigSendType" SG_ 1403 UDB26FZCU 1;
BA_ "GenSigSendType" SG_ 1403 UDB27FZCU 1;
BA_ "GenSigSendType" SG_ 1403 UDB28FZCU 1;
BA_ "GenSigSendType" SG_ 1403 UDB29FZCU 1;
BA_ "GenSigSendType" SG_ 1403 UDB30FZCU 1;
BA_ "GenSigSendType" SG_ 1403 UDB31FZCU 1;
BA_ "GenSigSendType" SG_ 1403 UDB32FZCU 1;
BA_ "GenSigSendType" SG_ 1403 UDB33FZCU 1;
BA_ "GenSigSendType" SG_ 1403 UDB34FZCU 1;
BA_ "GenSigSendType" SG_ 1403 UDB35FZCU 1;
BA_ "GenSigSendType" SG_ 1403 UDB36FZCU 1;
BA_ "GenSigSendType" SG_ 1403 UDB37FZCU 1;
BA_ "GenSigSendType" SG_ 1403 UDB38FZCU 1;
BA_ "GenSigSendType" SG_ 1403 UDB39FZCU 1;
BA_ "GenSigSendType" SG_ 1403 UDB40FZCU 1;
BA_ "GenSigSendType" SG_ 1403 UDB41FZCU 1;
BA_ "GenSigSendType" SG_ 1403 UDB42FZCU 1;
BA_ "GenSigSendType" SG_ 1403 UDB43FZCU 1;
BA_ "GenSigSendType" SG_ 1403 UDB44FZCU 1;
BA_ "GenSigSendType" SG_ 1403 UDB45FZCU 1;
BA_ "GenSigSendType" SG_ 1403 UDB46FZCU 1;
BA_ "GenSigSendType" SG_ 1403 UDB47FZCU 1;
BA_ "GenSigStartValue" SG_ 342 CurDampgCtrlMod 1;
BA_ "GenSigStartValue" SG_ 342 LvlModAct 3;
BA_ "GenSigStartValue" SG_ 342 SuspHeiSetSts 2;
BA_ "GenSigStartValue" SG_ 342 TarLvlChg 3;
BA_ "GenSigStartValue" SG_ 359 CurDampgCtrlMod2 1;
BA_ "GenSigStartValue" SG_ 359 LvlModAct2 3;
BA_ "GenSigSendType" SG_ 699 SCUBFaultInfoFlag 1;
BA_ "GenSigSendType" SG_ 1000 AccumIntkAirM 1;
BA_ "GenSigSendType" SG_ 1000 AccumNrFillg 1;
BA_ "GenSigSendType" SG_ 1000 AccumWtrIntkWght 1;
BA_ "GenSigSendType" SG_ 1000 AsuCrtlDataClctReq 1;
BA_ "GenSigSendType" SG_ 1000 AsuCrtlDataClctSts 1;
BA_ "GenSigSendType" SG_ 1000 ASULftDataClctReq 1;
BA_ "GenSigSendType" SG_ 1000 CmpOperModCntrDwnLvlg 1;
BA_ "GenSigSendType" SG_ 1000 CmpOperModCntrOvfDwnLvlg 1;
BA_ "GenSigSendType" SG_ 1000 CmpOperModCntrOvfUpLvlg 1;
BA_ "GenSigSendType" SG_ 1000 CmpOperModCntrResvFillg 1;
BA_ "GenSigSendType" SG_ 1000 CmpOperModCntrUpLvlg 1;
BA_ "GenSigSendType" SG_ 1000 CmpRtCntrDwnLvlg 1;
BA_ "GenSigSendType" SG_ 1000 CmpRtCntrTot 1;
BA_ "GenSigSendType" SG_ 1000 CmpRtCntrTotResvFillg 1;
BA_ "GenSigSendType" SG_ 1000 CmpRtCntrUpLvlg 1;
BA_ "GenSigSendType" SG_ 1000 CtrlActnFbAvFL 1;
BA_ "GenSigSendType" SG_ 1000 CtrlActnFbAvFR 1;
BA_ "GenSigSendType" SG_ 1000 CtrlActnFbAvRL 1;
BA_ "GenSigSendType" SG_ 1000 CtrlActnFbAvRR 1;
BA_ "GenSigSendType" SG_ 1000 CtrlActnFbEv 1;
BA_ "GenSigSendType" SG_ 1000 CtrlActnFbMot 1;
BA_ "GenSigSendType" SG_ 1000 CtrlActnFbSv1 1;
BA_ "GenSigSendType" SG_ 1000 CtrlActnFbSv2 1;
BA_ "GenSigSendType" SG_ 1000 CtrlActnFbSv3 1;
BA_ "GenSigSendType" SG_ 1000 CtrlActnFbSv4 1;
BA_ "GenSigSendType" SG_ 1000 NrActvnAv1Vlv 1;
BA_ "GenSigSendType" SG_ 1000 NrActvnAv2Vlv 1;
BA_ "GenSigSendType" SG_ 1000 NrActvnAv3Vlv 1;
BA_ "GenSigSendType" SG_ 1000 NrActvnAv4Vlv 1;
BA_ "GenSigSendType" SG_ 1000 NrActvnCmp 1;
BA_ "GenSigSendType" SG_ 1000 NrActvnEvVlv 1;
BA_ "GenSigSendType" SG_ 1000 NrActvnSv1Vlv 1;
BA_ "GenSigSendType" SG_ 1000 NrActvnSv2Vlv 1;
BA_ "GenSigSendType" SG_ 1000 NrActvnSv3Vlv 1;
BA_ "GenSigSendType" SG_ 1000 NrActvnSv4Vlv 1;
BA_ "GenSigSendType" SG_ 1000 PrsntAirMData 1;
BA_ "GenSigSendType" SG_ 1000 PrsntLoadData 1;
BA_ "GenSigSendType" SG_ 1000 ScuAcMode 1;
BA_ "GenSigSendType" SG_ 1000 SuspAirMDataClctReq 1;
BA_ "GenSigSendType" SG_ 1000 SuspAirMDataClctSts 1;
BA_ "GenSigSendType" SG_ 1000 SuspClctCurAmbHum 1;
BA_ "GenSigSendType" SG_ 1000 SuspClctCurAmbPSOA 1;
BA_ "GenSigSendType" SG_ 1000 SuspClctCurAmbT 1;
BA_ "GenSigSendType" SG_ 1000 SuspClctCurAmbTSOA 1;
BA_ "GenSigSendType" SG_ 1000 SuspWthrFcstAuthnSts 1;
BA_ "GenSigSendType" SG_ 1446 SCUEvntTrackFrame1Byte0to3 1;
BA_ "GenSigSendType" SG_ 1446 SCUEvntTrackFrame1Byte12to15 1;
BA_ "GenSigSendType" SG_ 1446 SCUEvntTrackFrame1Byte16to19 1;
BA_ "GenSigSendType" SG_ 1446 SCUEvntTrackFrame1Byte20to23 1;
BA_ "GenSigSendType" SG_ 1446 SCUEvntTrackFrame1Byte24to27 1;
BA_ "GenSigSendType" SG_ 1446 SCUEvntTrackFrame1Byte28to31 1;
BA_ "GenSigSendType" SG_ 1446 SCUEvntTrackFrame1Byte4to7 1;
BA_ "GenSigSendType" SG_ 1446 SCUEvntTrackFrame1Byte8to11 1;
BA_ "GenSigSendType" SG_ 156 RtcWake1AjustStsFL 1;
BA_ "GenSigSendType" SG_ 156 RtcWake1AjustStsFR 1;
BA_ "GenSigSendType" SG_ 156 RtcWake1AjustStsRL 1;
BA_ "GenSigSendType" SG_ 156 RtcWake1AjustStsRR 1;
BA_ "GenSigSendType" SG_ 156 RtcWake1DateTimeDay 1;
BA_ "GenSigSendType" SG_ 156 RtcWake1DateTimeHr 1;
BA_ "GenSigStartValue" SG_ 156 RtcWake1DateTimeHr 23;
BA_ "GenSigSendType" SG_ 156 RtcWake1DateTimeMins 1;
BA_ "GenSigStartValue" SG_ 156 RtcWake1DateTimeMins 59;
BA_ "GenSigSendType" SG_ 156 RtcWake1DateTimeMth 1;
BA_ "GenSigSendType" SG_ 156 RtcWake1DateTimeYr 1;
BA_ "GenSigSendType" SG_ 156 RtcWake1HeightFL 1;
BA_ "GenSigStartValue" SG_ 156 RtcWake1HeightFL 127;
BA_ "GenSigSendType" SG_ 156 RtcWake1HeightFR 1;
BA_ "GenSigStartValue" SG_ 156 RtcWake1HeightFR 127;
BA_ "GenSigSendType" SG_ 156 RtcWake1HeightRL 1;
BA_ "GenSigStartValue" SG_ 156 RtcWake1HeightRL 127;
BA_ "GenSigSendType" SG_ 156 RtcWake1HeightRR 1;
BA_ "GenSigStartValue" SG_ 156 RtcWake1HeightRR 127;
BA_ "GenSigSendType" SG_ 156 RtcWake1Valid 1;
BA_ "GenSigSendType" SG_ 156 RtcWake2AjustStsFL 1;
BA_ "GenSigSendType" SG_ 156 RtcWake2AjustStsFR 1;
BA_ "GenSigSendType" SG_ 156 RtcWake2AjustStsRL 1;
BA_ "GenSigSendType" SG_ 156 RtcWake2AjustStsRR 1;
BA_ "GenSigSendType" SG_ 156 RtcWake2DateTimeDay 1;
BA_ "GenSigSendType" SG_ 156 RtcWake2DateTimeHr 1;
BA_ "GenSigStartValue" SG_ 156 RtcWake2DateTimeHr 23;
BA_ "GenSigSendType" SG_ 156 RtcWake2DateTimeMins 1;
BA_ "GenSigStartValue" SG_ 156 RtcWake2DateTimeMins 59;
BA_ "GenSigSendType" SG_ 156 RtcWake2DateTimeMth 1;
BA_ "GenSigSendType" SG_ 156 RtcWake2DateTimeYr 1;
BA_ "GenSigSendType" SG_ 156 RtcWake2HeightFL 1;
BA_ "GenSigStartValue" SG_ 156 RtcWake2HeightFL 127;
BA_ "GenSigSendType" SG_ 156 RtcWake2HeightFR 1;
BA_ "GenSigStartValue" SG_ 156 RtcWake2HeightFR 127;
BA_ "GenSigSendType" SG_ 156 RtcWake2HeightRL 1;
BA_ "GenSigStartValue" SG_ 156 RtcWake2HeightRL 127;
BA_ "GenSigSendType" SG_ 156 RtcWake2HeightRR 1;
BA_ "GenSigStartValue" SG_ 156 RtcWake2HeightRR 127;
BA_ "GenSigSendType" SG_ 156 RtcWake2Valid 1;
BA_ "GenSigSendType" SG_ 156 RtcWake3AjustStsFL 1;
BA_ "GenSigSendType" SG_ 156 RtcWake3AjustStsFR 1;
BA_ "GenSigSendType" SG_ 156 RtcWake3AjustStsRL 1;
BA_ "GenSigSendType" SG_ 156 RtcWake3AjustStsRR 1;
BA_ "GenSigSendType" SG_ 156 RtcWake3DateTimeDay 1;
BA_ "GenSigSendType" SG_ 156 RtcWake3DateTimeHr 1;
BA_ "GenSigStartValue" SG_ 156 RtcWake3DateTimeHr 23;
BA_ "GenSigSendType" SG_ 156 RtcWake3DateTimeMins 1;
BA_ "GenSigStartValue" SG_ 156 RtcWake3DateTimeMins 59;
BA_ "GenSigSendType" SG_ 156 RtcWake3DateTimeMth 1;
BA_ "GenSigSendType" SG_ 156 RtcWake3DateTimeYr 1;
BA_ "GenSigSendType" SG_ 156 RtcWake3HeightFL 1;
BA_ "GenSigStartValue" SG_ 156 RtcWake3HeightFL 127;
BA_ "GenSigSendType" SG_ 156 RtcWake3HeightFR 1;
BA_ "GenSigStartValue" SG_ 156 RtcWake3HeightFR 127;
BA_ "GenSigSendType" SG_ 156 RtcWake3HeightRL 1;
BA_ "GenSigStartValue" SG_ 156 RtcWake3HeightRL 127;
BA_ "GenSigSendType" SG_ 156 RtcWake3HeightRR 1;
BA_ "GenSigStartValue" SG_ 156 RtcWake3HeightRR 127;
BA_ "GenSigSendType" SG_ 156 RtcWake3Valid 1;
BA_ "GenSigSendType" SG_ 157 ScuIGOffDateTimeDay 1;
BA_ "GenSigSendType" SG_ 157 ScuIGOffDateTimeHr 1;
BA_ "GenSigStartValue" SG_ 157 ScuIGOffDateTimeHr 23;
BA_ "GenSigSendType" SG_ 157 ScuIGOffDateTimeMins 1;
BA_ "GenSigStartValue" SG_ 157 ScuIGOffDateTimeMins 59;
BA_ "GenSigSendType" SG_ 157 ScuIGOffDateTimeMth 1;
BA_ "GenSigSendType" SG_ 157 ScuIGOffDateTimeYr 1;
BA_ "GenSigSendType" SG_ 157 ScuIGOffTargetFront 1;
BA_ "GenSigStartValue" SG_ 157 ScuIGOffTargetFront 127;
BA_ "GenSigSendType" SG_ 157 ScuIGOffTargetRear 1;
BA_ "GenSigStartValue" SG_ 157 ScuIGOffTargetRear 127;
BA_ "GenSigSendType" SG_ 157 ScuIGOffTime 1;
BA_ "GenSigStartValue" SG_ 182 AccrSnsrAzFrntLe 160;
BA_ "GenSigStartValue" SG_ 182 AccrSnsrAzFrntRi 160;
BA_ "GenSigStartValue" SG_ 182 AccrSnsrAzRe 160;
BA_ "GenSigStartValue" SG_ 182 BodyVertVFL 4000;
BA_ "GenSigStartValue" SG_ 182 BodyVertVFR 4000;
BA_ "GenSigStartValue" SG_ 182 BodyVertVRL 4000;
BA_ "GenSigStartValue" SG_ 182 BodyVertVRR 4000;
BA_ "GenSigStartValue" SG_ 182 FrntLeCurHei 127;
BA_ "GenSigStartValue" SG_ 182 FrntRiCurHei 127;
BA_ "GenSigStartValue" SG_ 182 ReLeCurHei 127;
BA_ "GenSigStartValue" SG_ 182 ReRiCurHei 127;
BA_ "GenSigStartValue" SG_ 192 BodyVertVFL2 4000;
BA_ "GenSigStartValue" SG_ 192 BodyVertVFR2 4000;
BA_ "GenSigStartValue" SG_ 192 BodyVertVRL2 4000;
BA_ "GenSigStartValue" SG_ 192 BodyVertVRR2 4000;
BA_ "GenSigStartValue" SG_ 192 FrntLeCurHei2 127;
BA_ "GenSigStartValue" SG_ 192 FrntRiCurHei2 127;
BA_ "GenSigStartValue" SG_ 192 ReLeCurHei2 127;
BA_ "GenSigStartValue" SG_ 192 ReRiCurHei2 127;
BA_ "GenSigSendType" SG_ 1323 NMKeepAwkRsnSCUB 1;
BA_ "GenSigSendType" SG_ 1323 SCUChassisCanfdActiveWakeup 1;
BA_ "GenSigSendType" SG_ 1323 SCUChassisCanfdNodeAddress 1;
BA_ "GenSigSendType" SG_ 1323 SCUChassisCanfdRepeatMsgReq 1;
BA_ "GenSigSendType" SG_ 1323 SCUChassisCanfdRepeatMsgSt 1;
BA_ "GenSigSendType" SG_ 1323 UDB17SCU 1;
BA_ "GenSigSendType" SG_ 1323 UDB18SCU 1;
BA_ "GenSigSendType" SG_ 1323 UDB19SCU 1;
BA_ "GenSigSendType" SG_ 1323 UDB20SCU 1;
BA_ "GenSigSendType" SG_ 1323 UDB21SCU 1;
BA_ "GenSigSendType" SG_ 1323 UDB22SCU 1;
BA_ "GenSigSendType" SG_ 1323 UDB23SCU 1;
BA_ "GenSigSendType" SG_ 1323 UDB24SCU 1;
BA_ "GenSigSendType" SG_ 1323 UDB25SCU 1;
BA_ "GenSigSendType" SG_ 1323 UDB26SCU 1;
BA_ "GenSigSendType" SG_ 1323 UDB27SCU 1;
BA_ "GenSigSendType" SG_ 1323 UDB28SCU 1;
BA_ "GenSigSendType" SG_ 1323 UDB29SCU 1;
BA_ "GenSigSendType" SG_ 1323 UDB30SCU 1;
BA_ "GenSigSendType" SG_ 1323 UDB31SCU 1;
BA_ "GenSigSendType" SG_ 1323 UDB32SCU 1;
BA_ "GenSigSendType" SG_ 1323 UDB33SCU 1;
BA_ "GenSigSendType" SG_ 1323 UDB34SCU 1;
BA_ "GenSigSendType" SG_ 1323 UDB35SCU 1;
BA_ "GenSigSendType" SG_ 1323 UDB36SCU 1;
BA_ "GenSigSendType" SG_ 1323 UDB37SCU 1;
BA_ "GenSigSendType" SG_ 1323 UDB38SCU 1;
BA_ "GenSigSendType" SG_ 1323 UDB39SCU 1;
BA_ "GenSigSendType" SG_ 1323 UDB40SCU 1;
BA_ "GenSigSendType" SG_ 1323 UDB41SCU 1;
BA_ "GenSigSendType" SG_ 1323 UDB42SCU 1;
BA_ "GenSigSendType" SG_ 1323 UDB43SCU 1;
BA_ "GenSigSendType" SG_ 1323 UDB44SCU 1;
BA_ "GenSigSendType" SG_ 1323 UDB45SCU 1;
BA_ "GenSigSendType" SG_ 1323 UDB46SCU 1;
BA_ "GenSigSendType" SG_ 1323 UDB47SCU 1;
BA_ "GenSigSendType" SG_ 1572 SCUToVCCDDiagResp 1;
BA_ "GenSigSendType" SG_ 1319 NMKeepAwkRsnSWM 1;
BA_ "GenSigSendType" SG_ 1319 SWMActiveWakeup 1;
BA_ "GenSigSendType" SG_ 1319 SWMNodeAddress 1;
BA_ "GenSigSendType" SG_ 1319 SWMRepeatMsgReq 1;
BA_ "GenSigSendType" SG_ 1319 SWMRepeatMsgSt 1;
BA_ "GenSigSendType" SG_ 1319 UDB17SWM 1;
BA_ "GenSigSendType" SG_ 1319 UDB18SWM 1;
BA_ "GenSigSendType" SG_ 1319 UDB19SWM 1;
BA_ "GenSigSendType" SG_ 1319 UDB20SWM 1;
BA_ "GenSigSendType" SG_ 1319 UDB21SWM 1;
BA_ "GenSigSendType" SG_ 1319 UDB22SWM 1;
BA_ "GenSigSendType" SG_ 1319 UDB23SWM 1;
BA_ "GenSigSendType" SG_ 1319 UDB24SWM 1;
BA_ "GenSigSendType" SG_ 1319 UDB25SWM 1;
BA_ "GenSigSendType" SG_ 1319 UDB26SWM 1;
BA_ "GenSigSendType" SG_ 1319 UDB27SWM 1;
BA_ "GenSigSendType" SG_ 1319 UDB28SWM 1;
BA_ "GenSigSendType" SG_ 1319 UDB29SWM 1;
BA_ "GenSigSendType" SG_ 1319 UDB30SWM 1;
BA_ "GenSigSendType" SG_ 1319 UDB31SWM 1;
BA_ "GenSigSendType" SG_ 1319 UDB32SWM 1;
BA_ "GenSigSendType" SG_ 1319 UDB33SWM 1;
BA_ "GenSigSendType" SG_ 1319 UDB34SWM 1;
BA_ "GenSigSendType" SG_ 1319 UDB35SWM 1;
BA_ "GenSigSendType" SG_ 1319 UDB36SWM 1;
BA_ "GenSigSendType" SG_ 1319 UDB37SWM 1;
BA_ "GenSigSendType" SG_ 1319 UDB38SWM 1;
BA_ "GenSigSendType" SG_ 1319 UDB39SWM 1;
BA_ "GenSigSendType" SG_ 1319 UDB40SWM 1;
BA_ "GenSigSendType" SG_ 1319 UDB41SWM 1;
BA_ "GenSigSendType" SG_ 1319 UDB42SWM 1;
BA_ "GenSigSendType" SG_ 1319 UDB43SWM 1;
BA_ "GenSigSendType" SG_ 1319 UDB44SWM 1;
BA_ "GenSigSendType" SG_ 1319 UDB45SWM 1;
BA_ "GenSigSendType" SG_ 1319 UDB46SWM 1;
BA_ "GenSigSendType" SG_ 1319 UDB47SWM 1;
BA_ "GenSigSendType" SG_ 1573 SWMToVCCDDiagResp 1;
BA_ "GenSigSendType" SG_ 1761 SWMToVCCDResp 1;
BA_ "GenSigStartValue" SG_ 263 DateTiHr 24;
BA_ "GenSigStartValue" SG_ 263 DateTiMilsec 1000;
BA_ "GenSigStartValue" SG_ 263 DateTiMins 60;
BA_ "GenSigStartValue" SG_ 263 DateTiSec 60;
BA_ "GenSigSendType" SG_ 529 SecOCMAC1 1;
BA_ "GenSigSendType" SG_ 529 SecOCMAC2 1;
BA_ "GenSigSendType" SG_ 529 SecOCMAC3 1;
BA_ "GenSigSendType" SG_ 529 SecOCResetCnt 1;
BA_ "GenSigSendType" SG_ 529 SecOCTripCnt 1;
BA_ "GenSigSendType" SG_ 910 SuspHeiSetSoa 1;
BA_ "GenSigSendType" SG_ 931 AVHBtn 1;
BA_ "GenSigSendType" SG_ 931 AVHSet 1;
BA_ "GenSigSendType" SG_ 931 CSTOnOffBtn 1;
BA_ "GenSigSendType" SG_ 931 CSTOnOffSet 1;
BA_ "GenSigSendType" SG_ 931 DCDBattHlthMngtFcnSwt 1;
BA_ "GenSigSendType" SG_ 931 DCDEasyEntryHeiSet 1;
BA_ "GenSigSendType" SG_ 931 DCDHDCSet 1;
BA_ "GenSigSendType" SG_ 931 DCDJackModSet 1;
BA_ "GenSigSendType" SG_ 931 DCDStdLvlSpdSwt 1;
BA_ "GenSigSendType" SG_ 931 EasyEntryModReqBtn 1;
BA_ "GenSigSendType" SG_ 931 EasyEntryModSet 1;
BA_ "GenSigSendType" SG_ 931 EasyLoadgFuncCouplSet 1;
BA_ "GenSigSendType" SG_ 931 EasyLoadgModReqBtn 1;
BA_ "GenSigSendType" SG_ 931 EasyLoadgModSet 1;
BA_ "GenSigSendType" SG_ 931 EPBSwtSet 1;
BA_ "GenSigSendType" SG_ 931 ESCOffSet 1;
BA_ "GenSigSendType" SG_ 931 SuspHeiSet 1;
BA_ "GenSigStartValue" SG_ 1023 VidBlkId 1;
BA_ "GenSigStartValue" SG_ 1023 VinVINBlkID 1;
BA_ "GenSigSendType" SG_ 135 VehCfgPrmBlkIDBytePosn1 1;
BA_ "GenSigStartValue" SG_ 135 VehCfgPrmBlkIDBytePosn1 1;
BA_ "GenSigSendType" SG_ 135 VehCfgPrmCCPBytePosn2 1;
BA_ "GenSigSendType" SG_ 135 VehCfgPrmCCPBytePosn3 1;
BA_ "GenSigSendType" SG_ 135 VehCfgPrmCCPBytePosn4 1;
BA_ "GenSigSendType" SG_ 135 VehCfgPrmCCPBytePosn5 1;
BA_ "GenSigSendType" SG_ 135 VehCfgPrmCCPBytePosn6 1;
BA_ "GenSigSendType" SG_ 135 VehCfgPrmCCPBytePosn7 1;
BA_ "GenSigSendType" SG_ 135 VehCfgPrmCCPBytePosn8 1;
BA_ "GenSigSendType" SG_ 1313 NMKeepAwkRsnVCCD 1;
BA_ "GenSigSendType" SG_ 1313 UDB17VCCD 1;
BA_ "GenSigSendType" SG_ 1313 UDB18VCCD 1;
BA_ "GenSigSendType" SG_ 1313 UDB19VCCD 1;
BA_ "GenSigSendType" SG_ 1313 UDB20VCCD 1;
BA_ "GenSigSendType" SG_ 1313 UDB21VCCD 1;
BA_ "GenSigSendType" SG_ 1313 UDB22VCCD 1;
BA_ "GenSigSendType" SG_ 1313 UDB23VCCD 1;
BA_ "GenSigSendType" SG_ 1313 UDB24VCCD 1;
BA_ "GenSigSendType" SG_ 1313 UDB25VCCD 1;
BA_ "GenSigSendType" SG_ 1313 UDB26VCCD 1;
BA_ "GenSigSendType" SG_ 1313 UDB27VCCD 1;
BA_ "GenSigSendType" SG_ 1313 UDB28VCCD 1;
BA_ "GenSigSendType" SG_ 1313 UDB29VCCD 1;
BA_ "GenSigSendType" SG_ 1313 UDB30VCCD 1;
BA_ "GenSigSendType" SG_ 1313 UDB31VCCD 1;
BA_ "GenSigSendType" SG_ 1313 UDB32VCCD 1;
BA_ "GenSigSendType" SG_ 1313 UDB33VCCD 1;
BA_ "GenSigSendType" SG_ 1313 UDB34VCCD 1;
BA_ "GenSigSendType" SG_ 1313 UDB35VCCD 1;
BA_ "GenSigSendType" SG_ 1313 UDB36VCCD 1;
BA_ "GenSigSendType" SG_ 1313 UDB37VCCD 1;
BA_ "GenSigSendType" SG_ 1313 UDB38VCCD 1;
BA_ "GenSigSendType" SG_ 1313 UDB39VCCD 1;
BA_ "GenSigSendType" SG_ 1313 UDB40VCCD 1;
BA_ "GenSigSendType" SG_ 1313 UDB41VCCD 1;
BA_ "GenSigSendType" SG_ 1313 UDB42VCCD 1;
BA_ "GenSigSendType" SG_ 1313 UDB43VCCD 1;
BA_ "GenSigSendType" SG_ 1313 UDB44VCCD 1;
BA_ "GenSigSendType" SG_ 1313 UDB45VCCD 1;
BA_ "GenSigSendType" SG_ 1313 UDB46VCCD 1;
BA_ "GenSigSendType" SG_ 1313 UDB47VCCD 1;
BA_ "GenSigSendType" SG_ 1313 UDB49VCCD 1;
BA_ "GenSigSendType" SG_ 1313 UDB50VCCD 1;
BA_ "GenSigSendType" SG_ 1313 UDB51VCCD 1;
BA_ "GenSigSendType" SG_ 1313 UDB52VCCD 1;
BA_ "GenSigSendType" SG_ 1313 UDB53VCCD 1;
BA_ "GenSigSendType" SG_ 1313 VCCDChassisBkpActiveWakeup 1;
BA_ "GenSigSendType" SG_ 1313 VCCDChassisBkpNodeAddress 1;
BA_ "GenSigSendType" SG_ 1313 VCCDChassisBkpRepeatMsgReq 1;
BA_ "GenSigSendType" SG_ 1313 VCCDChassisBkpRepeatMsgSt 1;
BA_ "GenSigSendType" SG_ 2047 VCCDToChassisBkpFuncDiagReq 1;
BA_ "GenSigSendType" SG_ 1832 VCCDToEPSChassisBkpDiagReq 1;
BA_ "GenSigSendType" SG_ 1828 VCCDToSCUDiagReq 1;
BA_ "GenSigSendType" SG_ 1829 VCCDToSWMReq 1;
BA_ "GenSigSendType" SG_ 1760 VCCDToSWMDiagReq 1;
VAL_ 186 ABSAvailability 0 "false" 1 "true" ;
VAL_ 186 BCSModBrakeActType 0 "Dynamic" 1 "Standard" 2 "Comfort_Low" 3 "Comfort_Medium" 4 "Comfort_Max" ;
VAL_ 186 BCSRecuStatusMod 0 "NotInitialized" 1 "Normal" 2 "Faulty" ;
VAL_ 186 BrkSysAbsActv 0 "NotActive" 1 "Active" ;
VAL_ 186 BrkSysDrvrPrsnt 0 "NotPresent" 1 "Present" ;
VAL_ 186 BrkSysLdmGlbStsMod 0 "LdmGlbArb_NotInitialized" 1 "LdmGlbArb_Faulty" 2 "LdmGlbArb_Normal" ;
VAL_ 186 BrkSysMstCylPVld 0 "NotInitialized" 1 "Normal" 2 "Faulty" 3 "NotMonitored" 4 "TemporarilyFrozen" ;
VAL_ 186 BrkSysRntSpprtAvl 0 "NotAvailable" 1 "Available" ;
VAL_ 186 BrkSysVehDirInfo 0 "NotDefined" 1 "Stop" 2 "Forward" 3 "Backward" ;
VAL_ 186 BrkSysVehDirInfoVld 0 "NotInitialized" 1 "Normal" 2 "Faulty" 3 "DiffCalculated" 4 "ReducedMonitor" 5 "NotCalculated" 6 "InvalidUnderVoltage" ;
VAL_ 186 BrkSysVehSpdVld 0 "NotInitialized" 1 "Normal" 2 "Faulty" 3 "DiffCalculated" 4 "ReducedMonitor" 5 "NotCalculated" 6 "InvalidUnderVoltage" ;
VAL_ 186 BrkSysVolSuctnActv 0 "NotActive" 1 "Active" ;
VAL_ 186 MaxTarSpdFrntAxleRels 0 "ModeDMC_Off" 1 "ModeDMC_Rpm" 2 "ModeDMC_Trq" 3 "RpmSplit" ;
VAL_ 186 MaxTarSpdReAxleRels 0 "ModeDMC_Off" 1 "ModeDMC_Rpm" 2 "ModeDMC_Trq" 3 "RpmSplit" ;
VAL_ 186 VehicleStandStill 0 "false" 1 "true" ;
VAL_ 186 VehicleStandStillQ 0 "NotInitialized" 1 "Faulty" 2 "Normal" ;
VAL_ 190 BrkSysAPCBkpStgyReqCom2 0 "NotActive" 1 "Active" ;
VAL_ 190 BrkSysAPCMain2BkpStCom2 0 "NotAvailable_temporary" 1 "NotAvailable_NotReleased" 2 "NotAvailable_permanent" 3 "NotActivated_FullAvailable" 4 "Activation_Preparation" 5 "Activation_Pending" 6 "Activation_PendingRedundancyLost" 7 "Activation_PendingFailOperation" 8 "Activated_FullAvailable" 9 "Activated_FailOperation" 10 "Activated_RedundancyLost" 11 "Deactivation_pending" ;
VAL_ 190 RPBHpsAck 0 "NotAcknowledged" 1 "Acknowledged" ;
VAL_ 190 RPBHpsAvl 0 "NotAvailable" 1 "Available" ;
VAL_ 190 RPBMstCylPVld 0 "NotInitialized" 1 "Normal" 2 "Faulty" 3 "Reserve" ;
VAL_ 190 RPBWhlPFrntLeVld 0 "Invalid" 1 "Valid" ;
VAL_ 190 RPBWhlPFrntRiVld 0 "Invalid" 1 "Valid" ;
VAL_ 190 RPBWhlPReLeVld 0 "Invalid" 1 "Valid" ;
VAL_ 190 RPBWhlPReRiVld 0 "Invalid" 1 "Valid" ;
VAL_ 190 RPBWhlSpdFrntLeVld 0 "Invalid" 1 "Valid" ;
VAL_ 190 RPBWhlSpdFrntRiVld 0 "Invalid" 1 "Valid" ;
VAL_ 190 RPBWhlSpdReLeVld 0 "Invalid" 1 "Valid" ;
VAL_ 190 RPBWhlSpdReRiVld 0 "Invalid" 1 "Valid" ;
VAL_ 1315 BCSChassisBkpActiveWakeup 0 "passive_wakeup" 1 "active_Wakeup" ;
VAL_ 1315 BCSChassisBkpRepeatMsgReq 0 "Repeat_Message_State_not_requested" 1 "Repeat_Message_State_requested" ;
VAL_ 1315 BCSChassisBkpRepeatMsgSt 0 "Not_in_Repeat_Message_State" 1 "In_Repeat_Message_State" ;
VAL_ 444 RCAvailable 0 "Not_Available" 1 "Available" ;
VAL_ 444 RPARemReq 0 "No_Request" 1 "RPA_Request" 2 "Reserved1" 3 "Reserved1" ;
VAL_ 663 DltAllKeyFb 0 "Idle" 1 "Success" 2 "NFC_card_certificated" 3 "NFC_card_certificate_fail" 4 "Certificate_timeout" 5 "No_feedback_from_server" 6 "Wait_for_NFC_card" ;
VAL_ 663 SndBLEKeyPosnToRPA 0 "Initial_value" 1 "R0_distance" 2 "R1_distance" 3 "R2_distance" 4 "R3_distance" 5 "R4_distance" ;
VAL_ 758 FrntLeTyrePSnsrLoBattWarn 0 "Not_Active" 1 "Active" ;
VAL_ 758 FrntLeTyrePSnsrLostWarn 0 "Not_Active" 1 "Active" ;
VAL_ 758 FrntLeTyrePSnsrLrngSts 0 "Not_Active" 1 "Active" 2 "Reserved" 3 "Invalid" ;
VAL_ 758 FrntLeTyrePVal 255 "Invalid" ;
VAL_ 758 FrntLeTyrePWarn 0 "Not_Active" 1 "Low_Pressure" 2 "High_Pressure" 3 "Invalid" ;
VAL_ 758 FrntLeTyreTWarn 0 "Not_Active" 1 "High_Temperature" 2 "Reserved" 3 "Invalid" ;
VAL_ 758 FrntRiTyrePSnsrLoBattWarn 0 "Not_Active" 1 "Active" ;
VAL_ 758 FrntRiTyrePSnsrLostWarn 0 "Not_Active" 1 "Active" ;
VAL_ 758 FrntRiTyrePSnsrLrngSts 0 "Not_Active" 1 "Active" 2 "Reserved" 3 "Invalid" ;
VAL_ 758 FrntRiTyrePVal 255 "Invalid" ;
VAL_ 758 FrntRiTyrePWarn 0 "Not_Active" 1 "Low_Pressure" 2 "High_Pressure" 3 "Invalid" ;
VAL_ 758 FrntRiTyreTWarn 0 "Not_Active" 1 "High_Temperature" 2 "Reserved" 3 "Invalid" ;
VAL_ 758 ReLeTyrePSnsrLoBattWarn 0 "Not_Active" 1 "Active" ;
VAL_ 758 ReLeTyrePSnsrLostWarn 0 "Not_Active" 1 "Active" ;
VAL_ 758 ReLeTyrePSnsrLrngSts 0 "Not_Active" 1 "Active" 2 "Reserved" 3 "Invalid" ;
VAL_ 758 ReLeTyrePVal 255 "Invalid" ;
VAL_ 758 ReLeTyrePWarn 0 "Not_Active" 1 "Low_Pressure" 2 "High_Pressure" 3 "Invalid" ;
VAL_ 758 ReLeTyreTWarn 0 "Not_Active" 1 "High_Temperature" 2 "Reserved" 3 "Invalid" ;
VAL_ 758 ReRiTyrePSnsrLoBattWarn 0 "Not_Active" 1 "Active" ;
VAL_ 758 ReRiTyrePSnsrLostWarn 0 "Not_Active" 1 "Active" ;
VAL_ 758 ReRiTyrePSnsrLrngSts 0 "Not_Active" 1 "Active" 2 "Reserved" 3 "Invalid" ;
VAL_ 758 ReRiTyrePVal 255 "Invalid" ;
VAL_ 758 ReRiTyrePWarn 0 "Not_Active" 1 "Low_Pressure" 2 "High_Pressure" 3 "Invalid" ;
VAL_ 758 ReRiTyreTWarn 0 "Not_Active" 1 "High_Temperature" 2 "Reserved" 3 "Invalid" ;
VAL_ 758 TyrePwarnSts 0 "Not_Warn" 1 "Warn" 2 "Reserved" ;
VAL_ 581 BMDMAcvDcnMosSt 0 "default" 1 "power_off" 2 "unable_to_perform_power_off" 3 "reserved" ;
VAL_ 912 HvBattPressureInsdPack 4095 "Invalid" ;
VAL_ 355 AVPHPPCtrlAvlStsBkp 0 "Normal" 1 "Degraded" 2 "LossOfRedundancy" 3 "Reserved" ;
VAL_ 355 AVPHPPCtrStsBkp 0 "Prim" 1 "Sec" ;
VAL_ 355 AVPHPPReqFbStsBkp 0 "Initial" 1 "Ready" 2 "Active" 3 "Fault" 4 "Notused" 5 "Notused" 6 "Notused" 7 "Notused" ;
VAL_ 355 AVPHPPReqFltStsBkp 0 "Normal" 1 "VehicleSpeedOutOfRange" 2 "SteeringWheelTorqueOutOfRange" 3 "ImproperHandshaking" 4 "HandshakeTimeout" 5 "EPSInternalFault" 6 "Reserved" 7 "Reserved" 8 "Reserved" 9 "Reserved" 10 "Reserved" 11 "Reserved" 12 "Reserved" 13 "Reserved" 14 "Reserved" 15 "Reserved" ;
VAL_ 355 EPSBkpFaultInfoFlag 0 "No_Fault" 1 "Fault" ;
VAL_ 355 FailrStsBkp 0 "SteerNormal" 1 "SteerAssitTempRed" 2 "SteerAssitServReq" 3 "SteerAssitErrStopVehicle" 4 "Notused" 5 "Notused" 6 "Notused" 7 "Notused" ;
VAL_ 994 CcwEOTDetBkp 0 "Not_Learned" 1 "Learned" ;
VAL_ 994 CwEOTDetBkp 0 "Not_Learned" 1 "Learned" ;
VAL_ 181 ADASReqFbStsADD 0 "Initial" 1 "Ready" 2 "Open" 3 "Active" 4 "Fault" 5 "Notused" 6 "Notused" 7 "Notused" ;
VAL_ 181 ADASReqFltStsADD 0 "Normal" 1 "ADAS_Control_not_available" 2 "EPS_RevError" 3 "EPS_IrrevError" 4 "Caused_by_ADAS_failure" 5 "Reserved" 6 "Reserved" 7 "Reserved" ;
VAL_ 181 DrvrSteerActvADD 0 "Notactive" 1 "Active" ;
VAL_ 181 EstimdRkFVld 0 "Valid" 1 "Invalid" ;
VAL_ 181 PinionSteerAglSpdVld 0 "Valid" 1 "Invalid" ;
VAL_ 181 PinionSteerAglSpdVldV2C 0 "Valid" 1 "Invalid" ;
VAL_ 181 PinionSteerAglVld 0 "Valid" 1 "Invalid" ;
VAL_ 181 PinionSteerAglVldV2C 0 "Valid" 1 "Invalid" ;
VAL_ 181 SteerWhlTqVld 0 "Valid" 1 "Invalid" ;
VAL_ 181 SteerWhlVibStsADD 0 "NotActive" 1 "Active" ;
VAL_ 200 PinionSteerAglSpdVldBkp 0 "Valid" 1 "Invalid" ;
VAL_ 200 PinionSteerAglSpdVldBkpV2C 0 "Valid" 1 "Invalid" ;
VAL_ 200 PinionSteerAglVldBkp 0 "Valid" 1 "Invalid" ;
VAL_ 200 PinionSteerAglVldBkpV2C 0 "Valid" 1 "Invalid" ;
VAL_ 200 SteerWhlTqVldBkp 0 "Valid" 1 "Invalid" ;
VAL_ 1322 EPSChassisBkpActiveWakeup 0 "passive_wakeup" 1 "active_Wakeup" ;
VAL_ 1322 EPSChassisBkpRepeatMsgReq 0 "Repeat_Message_State_not_requested" 1 "Repeat_Message_State_requested" ;
VAL_ 1322 EPSChassisBkpRepeatMsgSt 0 "Not_in_Repeat_Message_State" 1 "In_Repeat_Message_State" ;
VAL_ 347 MIACurMod 0 "Unknow" 1 "Basic" 2 "Eco" 3 "Sport" 4 "Brake" 5 "Stability" 6 "Reserve1" 7 "Reserve2" ;
VAL_ 347 VCUReElsdLvlReq 15 "Invalid" ;
VAL_ 347 VCUReElsdOpenReq 0 "No_Req" 1 "Req_Open" 2 "Reserved1" 3 "Invalid" ;
VAL_ 515 VCUExtmPfmncMod 0 "Not_active" 1 "Active" ;
VAL_ 515 VCULnchPlusSts 0 "Not_active" 1 "Launch_Ready" 2 "Launch_Active" ;
VAL_ 515 VCUTrlrModStSts 0 "not_active" 1 "active" ;
VAL_ 515 VCUWashModStSts 0 "not_active" 1 "active" ;
VAL_ 656 AmbTEstimdVld 0 "Not_Valid" 1 "Valid" ;
VAL_ 656 AmbTRawVld 0 "Not_Valid" 1 "Valid" ;
VAL_ 656 EdsCircCooltTVld 0 "Not_Valid" 1 "Valid" ;
VAL_ 656 LRRLoPwrSplySts 0 "Off" 1 "On" ;
VAL_ 656 VCUBattOverHeatWarn 0 "not_active" 1 "active" ;
VAL_ 656 VCUChrgnModSts 0 "Not_in_charging" 1 "In_preparation" 2 "Charging_in_progress" 3 "Charging_done" 4 "Charging_fault" 5 "Driving_charging" 6 "Charging_stop" 7 "Booking_charging_waiting" 8 "Preheating_in_process" 9 "Warming_in_progress" ;
VAL_ 656 VCUDrvMotFltWarn 0 "not_active" 1 "active" ;
VAL_ 656 VCUDrvMotOverHeatWarn 0 "Not_active" 1 "Active" ;
VAL_ 656 VCUDrvSysLimdWarn 0 "not_active" 1 "active" ;
VAL_ 656 VCUEstimdCrsRng 2047 "Invalid" ;
VAL_ 656 VCUEstimdCrsRngVld 0 "invalid" 1 "valid" ;
VAL_ 656 VCUGearChgFailInde 0 "No_request" 1 "Please_brake" 2 "Vehicle_speed_high" 3 "Charging_plug_insertion" 4 "EPB_failure" 5 "E_motor_failure" 6 "Connect_the_key_and_press_SSB" 7 "Press_SSB" 8 "Show_Room_Keep_Park" 9 "LV_System_Failure" 10 "HV_System_Failure" 11 "Immobilizer_Not_Pass" 12 "Trailer_Mode_Not_Shift" 13 "Shifter_Failure" ;
VAL_ 656 VCUHvBattSysFltIndcr 0 "not_active" 1 "active" ;
VAL_ 656 VCUHvBattSysFltWarn 0 "not_active" 1 "active" ;
VAL_ 656 VCUHvPwrSysCutOff 0 "not_active" 1 "active" ;
VAL_ 656 VCUHVSysFltWarnSts 0 "no_warning" 1 "reserved" 2 "HV_System_Fault_warning_Level2" 3 "reserved" 4 "HV_System_Fault_warning_Level4" 5 "HV_System_Fault_warning_Level5" 6 "HV_System_Fault_warning_Level6" 7 "reserved" 8 "HV_System_Fault_warning_Level8" 9 "HV_System_Fault_warning_Level9" 10 "reserved" 11 "reserved" 12 "reserved" 13 "reserved" 14 "reserved" 15 "reserved" ;
VAL_ 656 VCUInsEgyCnsFlg 0 "Park_status" 1 "driving_status" ;
VAL_ 656 VCULoSocWarngMsg 0 "Not_active" 1 "Level1_warning" 2 "Level2_warning" ;
VAL_ 656 VCUPrpsnPwrDrt 0 "not_active" 1 "active" ;
VAL_ 656 VCUThermRunawayErrAlrm 0 "not_active" 1 "active" ;
VAL_ 656 VCUVehSysFltWarn 0 "not_active" 1 "active" ;
VAL_ 144 CarModSts 0 "Normal" 1 "Fcy" 2 "Trsnp" 3 "Showroom" 4 "Dyno" 5 "TestDrv" 6 "Service" 7 "Reserved3" ;
VAL_ 144 PwrModSts 0 "OFF" 1 "Awake" 2 "ACC" 3 "RUN" ;
VAL_ 144 PwrModVld 0 "Valid" 1 "NotValid" ;
VAL_ 144 VCUAccrPedlRatVld 0 "invalid" 1 "valid" ;
VAL_ 144 VCUActDrvMod 0 "Comfort_Mode" 1 "Sport_Mode" 2 "Individual_Mode1" 3 "Individual_Mode2" 4 "Individual_Mode3" 5 "Snow_Mode" 6 "Mountain_Mode" 7 "Battle_Mode" 8 "Extreme_Eco_mode" 9 "Sport_plus_mode" 10 "Off_road_Mode" 11 "Wet_Mode" 12 "Standard_Mode" 13 "AntMtnsick_Mode" ;
VAL_ 144 VCUActGearLvr 0 "P_Park_gear" 1 "R_Reverse_gear" 2 "N_Neutral_gear" 3 "D_Drive_gear" ;
VAL_ 144 VCUActGearLvrVld 0 "Invalid" 1 "Valid" ;
VAL_ 144 VCUDrvModSteerAsstPrmSts 0 "No_Request" 1 "SteerAsscLvl_Lvl1" 2 "SteerAsscLvl_Lvl2" 3 "SteerAsscLvl_Lvl3" 4 "SteerAsscLvl_Lvl4" 5 "SteerAsscLvl_Lvl5" ;
VAL_ 144 VCUDrvModSuspDampgPrmSts 0 "No_Command" 1 "Comfort" 2 "Normal" 3 "Sport" ;
VAL_ 144 VCUDrvModSuspLvlgPrmSts 0 "Not_use" 1 "HL2_target" 2 "HL1_target" 3 "NL_target" 4 "LL1_target" 5 "LL2_target" ;
VAL_ 144 VCUDrvOffFcnLim 0 "Normal;" 1 "PowerLimited_Fault." ;
VAL_ 144 VCUFrntEmTqRdy 0 "Not_ready" 1 "Ready" ;
VAL_ 144 VCUGearLvrAvail 0 "Not_Available" 1 "Available" ;
VAL_ 144 VCUPrkgBtnPsd 0 "Not_Active" 1 "active" ;
VAL_ 144 VCUPrkgBtnPsdVld 0 "Invalid" 1 "Valid" ;
VAL_ 144 VCUPtRdyFlg 0 "not_active" 1 "active" ;
VAL_ 144 VCUReEmTqRdy 0 "Not_ready" 1 "Ready" ;
VAL_ 144 VCUStsModCst 0 "OPedl_No_RgL1" 1 "OPedl_No_RgL2" 2 "OPedl_No_RgL3" 3 "OPedl_No_RgL4" 4 "OPedl_No_RgL5" 5 "OPedl_No_ADASactive" 6 "OPedl_No_RoadGradientInhbit" 7 "OPedl_No_PowerDown" 16 "OPedl_Stop_RgL1" 17 "OPedl_Stop_RgL2" 18 "OPedl_Stop_RgL3" 19 "OPedl_Stop_RgL4" 20 "OPedl_Stop_RgL5" 21 "OPedl_Crp_RgL1" 22 "OPedl_Crp_RgL2" 23 "OPedl_Crp_RgL3" 24 "OPedl_Crp_RgL4" 25 "OPedl_Crp_RgL5" 26 "OPedl_FW_RgL1" 27 "OPedl_FW_RgL2" 28 "OPedl_FW_RgL3" 29 "OPedl_FW_RgL4" 30 "OPedl_FW_RgL5" ;
VAL_ 144 VCUTarGearLvr 0 "P_Park_gear" 1 "R_Reverse_gear" 2 "N_Neutral_gear" 3 "D_Drive_gear" ;
VAL_ 144 VCUTarGearLvrVld 0 "Invalid" 1 "Valid" ;
VAL_ 144 VCUVirtAccrPedlVld 0 "Invalid" 1 "Valid" ;
VAL_ 188 PreDampgCtrlReqFL 0 "PreCtrlOff" 1 "PreCtrlOn" ;
VAL_ 188 PreDampgCtrlReqFR 0 "PreCtrlOff" 1 "PreCtrlOn" ;
VAL_ 188 PreDampgCtrlReqRL 0 "PreCtrlOff" 1 "PreCtrlOn" ;
VAL_ 188 PreDampgCtrlReqRR 0 "PreCtrlOff" 1 "PreCtrlOn" ;
VAL_ 188 SuspRoadConditionForADD 0 "NA" 1 "减速带" 2 "大起伏路" 3 "小起伏路" 4 "上坡" 5 "下坡" 6 "平整路面" 7 "小粗糙路" 8 "中等粗糙路" 9 "大粗糙路" 16 "越野路" ;
VAL_ 188 VCUFrntDesTqWoIntvVld 0 "Invalid" 1 "Valid" ;
VAL_ 188 VCUFrntMotActSpdVld 0 "Invalid" 1 "Valid" ;
VAL_ 188 VCUFrntMotActTqVld 0 "Invalid" 1 "Valid" ;
VAL_ 188 VCUFrntMotWhlTqReqVld 0 "Invalid" 1 "Valid" ;
VAL_ 188 VCUFrntWhlTqMaxAvlVld 0 "Invalid" 1 "Valid" ;
VAL_ 188 VCUFrntWhlTqMinAvlVld 0 "Invalid" 1 "Valid" ;
VAL_ 188 VCULnchPlusAcvFlg 0 "Not_Active" 1 "Active" ;
VAL_ 188 VCUOperModFAOfDMC 0 "DMC_Init" 1 "DMC_On" 2 "DMC_Off" 3 "DMC_Fault" ;
VAL_ 188 VCUOperModRAOfDMC 0 "DMC_Init" 1 "DMC_On" 2 "DMC_Off" 3 "DMC_Fault" ;
VAL_ 188 VCUReDesTqWoIntvVld 0 "Invalid" 1 "Valid" ;
VAL_ 188 VCUReMotActSpdVld 0 "Invalid" 1 "Valid" ;
VAL_ 188 VCUReMotActTqVld 0 "Invalid" 1 "Valid" ;
VAL_ 188 VCUReMotWhlTqReqVld 0 "Invalid" 1 "Valid" ;
VAL_ 188 VCUReWhlTqMaxAvlVld 0 "Invalid" 1 "Valid" ;
VAL_ 188 VCUReWhlTqMinAvlVld 0 "Invalid" 1 "Valid" ;
VAL_ 188 VCUWhlTqMaxAvlVld 0 "Not_validate;" 1 "Valiate;" ;
VAL_ 188 VehLatSpdEstdVld 0 "NotValid" 1 "Valid" ;
VAL_ 188 VehLgtSpdEstdVld 0 "NotValid" 1 "Valid" ;
VAL_ 607 AswmLinComFltSts 0 "No_Fault" 1 "Node_Miss" ;
VAL_ 607 HandOnDetnStsSigGrpLinErr 0 "NoErr" 1 "CounterErr" 2 "CRCErr" 3 "CounterErr_CRCErr" ;
VAL_ 607 HandsOnDetectionErrorStatus 0 "NoError" 1 "Error" ;
VAL_ 607 HandsOnDetectionStatus 0 "No_Detect" 1 "Detect" ;
VAL_ 607 StsOfBSDLampLe 0 "Off" 1 "On" 2 "Err" 3 "Resd" ;
VAL_ 892 DrvrOcupcySts 0 "Empty" 1 "Occupied" 2 "Invaild_STG" 3 "Invaild_STB_OL" ;
VAL_ 892 HfaftApplyHldCurSts 0 "Actuator_Coils_Not_Energised" 1 "Actuator_Coils_Energised" 2 "Reserved" 3 "Signal_Invalid" ;
VAL_ 892 HfaftElecDfctErr 0 "No_Defect" 1 "Electrical_Defect_Present" 2 "Permanent_Electrical_Defect_Present" 3 "Signal_Invalid" ;
VAL_ 892 HfaftEmgyRunOccurred 0 "No_Emergency_Run_Occurred" 1 "Emergency_Run_Occurred" 2 "Reserved" 3 "Signal_Invalid" ;
VAL_ 892 HfaftEmgyRunPosnSts 0 "Lower_Stop" 1 "Upper_Stop" 2 "Reserved" 3 "Signal_Invalid" ;
VAL_ 892 HfaftEmgyRunRelsSts 0 "Emergency_Run_Off" 1 "Emergency_Run_On" 2 "Reserved" 3 "Signal_Invalid" ;
VAL_ 892 HfaftLinComFltSts 0 "No_Fault" 1 "Node_Miss" 2 "Checksum_Error" ;
VAL_ 892 HfaftMoveDir 0 "Direction_Smaller_Step_Position" 1 "Direction_Larger_Step_Position" 2 "Init" 3 "Signal_Invalid" ;
VAL_ 892 HfaftOverTempErr 0 "No_Over_Temperature" 1 "Over_Temperature" 2 "Reserved" 3 "Signal_Invalid" ;
VAL_ 892 HfaftPosnSpcnSts 0 "Set_Position_Valid" 1 "Start_Position_Valid" 2 "No_Position_Specification_Valid" 3 "Signal_Invalid" ;
VAL_ 892 HfaftRespErr 0 "No_Error" 1 "Error_Present" ;
VAL_ 892 HfaftRotDirSts 0 "CW" 1 "CCW" 2 "Reserved" 3 "Signal_Invalid" ;
VAL_ 892 HfaftRst 0 "No_Reset" 1 "Reset_Performed" 2 "Reserved" 3 "Signal_Invalid" ;
VAL_ 892 HfaftSelfHldTq 0 "Without_Self_Holding_Torque" 1 "With_Self_Holding_Torque" 2 "Reserved" 3 "Signal_Invalid" ;
VAL_ 892 HfaftSpclFcns 0 "No_Special_Function_Active" 1 "Special_Function1_Active" 2 "Reserved" 3 "Signal_Invalid" ;
VAL_ 892 HfaftSpdSts 0 "Actuator_stopped" 1 "Speed_Level_1" 2 "Speed_Level_2" 3 "Speed_Level_3" 4 "Speed_Level_4" 5 "Auto_Speed" ;
VAL_ 892 HfaftSplyVoltErr 0 "Voltage_In_Permissible_Range" 1 "Under_Voltage" 2 "Over_Voltage" 3 "Signal_Invalid" ;
VAL_ 892 HfaftStallDetnRelsSts 0 "Stall_Detection_Off" 1 "Stall_Detection_On" 2 "Reserved" 3 "Signal_Invalid" ;
VAL_ 892 HfaftStallOccurred 0 "No_Stall" 1 "Stall_Detected" 2 "Reserved" 3 "Signal_Invalid" ;
VAL_ 892 HfaftStopModSts 0 "Normal_Mode" 1 "Stop_Mode" 2 "Reserved" 3 "Signal_Invalid" ;
VAL_ 892 SecRowLeOcupcySts 0 "Empty" 1 "Occupied" 2 "Invaild_STG" 3 "Invaild_STB_OL" ;
VAL_ 616 RlsAutWinWipgSpdCmd 0 "Switch_wiper_off" 1 "40_times_per_minute" 2 "45_times_per_minute" 3 "48_times_per_minute" 4 "51_times_per_minute" 5 "54_times_per_minute" 6 "57_times_per_minute" 7 "60_times_per_minute" ;
VAL_ 616 RlsFwdLiSnsrVal 32767 "Invalid" ;
VAL_ 616 RlsFwdLiSnsrValUnit 0 "1lux" 1 "10lux" 2 "100lux" 3 "1000lux" ;
VAL_ 616 RlsHudSnsrVal 32767 "Invalid" ;
VAL_ 616 RlsHudSnsrValUnit 0 "1lux" 1 "10lux" 2 "100lux" 3 "1000lux" ;
VAL_ 616 RlsLiSigGrpLinErr 0 "NoErr" 1 "CounterErr" 2 "CRCErr" 3 "CounterErr_CRCErr" ;
VAL_ 616 RlsLiSnsrFwdFlt 0 "No_Fault" 1 "Fault" ;
VAL_ 616 RlsLiSnsrIRFlt 0 "No_Fault" 1 "Fault" ;
VAL_ 616 RlsLiSnsrTopFlt 0 "No_Fault" 1 "Fault" ;
VAL_ 616 RlsLiSwtReq 0 "Switch_ligt_off" 1 "Switch_ligt_on" 2 "Reserved" 3 "Invalid" ;
VAL_ 616 RlsOutdBriSts 0 "Day" 1 "Night" 2 "Tunnel" 3 "Darkstart" 4 "Invalid" ;
VAL_ 616 RlsSts 0 "Rls_normal" 1 "Rls_Low_voltage" 2 "Rls_Over_voltage" 3 "Rls_Over_Temperature" 4 "Rls_communication_error" 5 "Rls_Hardware_fault" 6 "Not_determined" 7 "Invld" ;
VAL_ 616 RlsTopLiSnsrVal 32767 "Invalid" ;
VAL_ 616 RlsTopLiSnsrValUnit 0 "1lux" 1 "10lux" 2 "100lux" 3 "1000lux" ;
VAL_ 616 StsOfBSDLampRi 0 "Off" 1 "On" 2 "Err" 3 "Resd" ;
VAL_ 893 PassOcupcySts 0 "Empty" 1 "Occupied" 2 "Invaild_STG" 3 "Invaild_STB_OL" ;
VAL_ 893 SecRowMidOcupcySts 0 "Empty" 1 "Occupied" 2 "Invaild_STG" 3 "Invaild_STB_OL" ;
VAL_ 893 SecRowRiOcupcySts 0 "Empty" 1 "Occupied" 2 "Invaild_STG" 3 "Invaild_STB_OL" ;
VAL_ 893 ThrdRowMidOcupcySts 0 "Empty" 1 "Occupied" 2 "Invaild_STG" 3 "Invaild_STB_OL" ;
VAL_ 893 ThrdRowRiOcupcySts 0 "Empty" 1 "Occupied" 2 "Invaild_STG" 3 "Invaild_STB_OL" ;
VAL_ 342 AirPResvSts 0 "InValid" 1 "Valid" ;
VAL_ 342 ASCFltSts 0 "No_Fault" 1 "Level_control_restriction" 2 "Level_control_not_available" 3 "Level_control_not_available_caused_by_system_over_heated" ;
VAL_ 342 BatDamprModAllwd 0 "not_allow" 1 "allow" ;
VAL_ 342 CDCFltSts 0 "No_Fault" 1 "Damper_control_restriction" 2 "Damper_control_not_available" 3 "Damper_control_not_available_caused_by_system_over_heated" ;
VAL_ 342 CmftDamprModAllwd 0 "not_allow" 1 "allow" ;
VAL_ 342 CurDampgCtrlMod 0 "Comfort" 1 "Normal" 2 "Sport" 3 "Battle" ;
VAL_ 342 EasyEntryEnaSts 0 "not_allow" 1 "allow" ;
VAL_ 342 EasyEntryHeiSetSts 0 "Not_Set" 1 "HL2" 2 "HL1" 3 "NL" 4 "LL1" 5 "LL2" ;
VAL_ 342 EasyEntrySts 0 "Esay_Entry_OFF" 1 "Esay_Entry_ON" ;
VAL_ 342 EasyLoadEnaSts 0 "not_allow" 1 "allow" ;
VAL_ 342 EasyLoadgFuncCouplAct 0 "Coupling_OFF" 1 "Coupling_On" ;
VAL_ 342 EasyLoadSts 0 "Esay_Loading_OFF" 1 "Esay_loading_ON" ;
VAL_ 342 ESPEnaReq 0 "No_Request" 1 "Request" ;
VAL_ 342 FrntLeAirSprgPSts 0 "InValid" 1 "Valid" ;
VAL_ 342 FrntRiAirSprgPSts 0 "InValid" 1 "Valid" ;
VAL_ 342 HiLvlMod1Allwd 0 "not_allow" 1 "allow" ;
VAL_ 342 HiLvlMod1RestrcnRsn 0 "No_restriction" 1 "Level_Control_Restriction_by_System_Faulty" 2 "Level_Control_Restriction_by_Actuator_Temperature" 3 "Level_Control_Restriction_by_Voltage_Energy_Too_Low" 4 "Level_Control_Restriction_by_Manually_Disabled" 5 "Level_Control_Restriction_by_Car_Mode" 6 "Level_Control_Restriction_by_High_Speed" 7 "Level_control_restriction_by_Door_State" 8 "Level_control_restriction_by_Hoist_State" 9 "Level_Control_Restriction_by_Definition_Not_Allow" 10 "Level_control_restriction_by_Operation_Mode" ;
VAL_ 342 HiLvlMod2Allwd 0 "not_allow" 1 "allow" ;
VAL_ 342 HiLvlMod2RestrcnRsn 0 "No_restriction" 1 "Level_Control_Restriction_by_System_Faulty" 2 "Level_Control_Restriction_by_Actuator_Temperature" 3 "Level_Control_Restriction_by_Voltage_Energy_Too_Low" 4 "Level_Control_Restriction_by_Manually_Disabled" 5 "Level_Control_Restriction_by_Car_Mode" 6 "Level_Control_Restriction_by_High_Speed" 7 "Level_control_restriction_by_Door_State" 8 "Level_control_restriction_by_Hoist_State" 9 "Level_Control_Restriction_by_Definition_Not_Allow" 10 "Level_control_restriction_by_Operation_Mode" ;
VAL_ 342 JackModEnaSts 0 "InValid" 1 "Valid" ;
VAL_ 342 JackModSts 0 "Jack_Mode_OFF" 1 "Jack_Mode_ON" ;
VAL_ 342 LoLvlMod1Allwd 0 "not_allow" 1 "allow" ;
VAL_ 342 LoLvlMod1RestrcnRsn 0 "No_restriction" 1 "Level_Control_Restriction_by_System_Faulty" 2 "Level_Control_Restriction_by_Actuator_Temperature" 3 "Level_Control_Restriction_by_Voltage_Energy_Too_Low" 4 "Level_Control_Restriction_by_Manually_Disabled" 5 "Level_Control_Restriction_by_Car_Mode" 6 "Level_Control_Restriction_by_High_Speed" 7 "Level_control_restriction_by_Door_State" 8 "Level_control_restriction_by_Hoist_State" 9 "Level_Control_Restriction_by_Definition_Not_Allow" 10 "Level_control_restriction_by_Operation_Mode" ;
VAL_ 342 LoLvlMod2Allwd 0 "not_allow" 1 "allow" ;
VAL_ 342 LoLvlMod2RestrcnRsn 0 "No_restriction" 1 "Level_Control_Restriction_by_System_Faulty" 2 "Level_Control_Restriction_by_Actuator_Temperature" 3 "Level_Control_Restriction_by_Voltage_Energy_Too_Low" 4 "Level_Control_Restriction_by_Manually_Disabled" 5 "Level_Control_Restriction_by_Car_Mode" 6 "Level_Control_Restriction_by_High_Speed" 7 "Level_control_restriction_by_Door_State" 8 "Level_control_restriction_by_Hoist_State" 9 "Level_Control_Restriction_by_Definition_Not_Allow" 10 "Level_control_restriction_by_Operation_Mode" ;
VAL_ 342 LvlAdjmtSts 0 "No_action" 1 "Lowering" 2 "Lifting" 3 "Pending" 4 "Rear_lowering" 5 "Rear_lifting" 6 "Rear_pending" ;
VAL_ 342 LvlCtrlCalCompl 0 "Level_calibration_not_completed" 1 "Level_calibration_completed" ;
VAL_ 342 LvlModAct 0 "EasyLoad" 1 "HL2" 2 "HL1" 3 "NL" 4 "LL1" 5 "LL2" ;
VAL_ 342 NormDamprModAllwd 0 "not_allow" 1 "allow" ;
VAL_ 342 NormLvlModAllwd 0 "not_allow" 1 "allow" ;
VAL_ 342 NormLvlModRestrcnRsn 0 "No_restriction" 1 "Level_Control_Restriction_by_System_Faulty" 2 "Level_Control_Restriction_by_Actuator_Temperature" 3 "Level_Control_Restriction_by_Voltage_Energy_Too_Low" 4 "Level_Control_Restriction_by_Manually_Disabled" 5 "Level_Control_Restriction_by_Car_Mode" 6 "Level_Control_Restriction_by_High_Speed" 7 "Level_control_restriction_by_Door_State" 8 "Level_control_restriction_by_Hoist_State" 9 "Level_Control_Restriction_by_Definition_Not_Allow" 10 "Level_control_restriction_by_Operation_Mode" ;
VAL_ 342 ReLeAirSprgPSts 0 "InValid" 1 "Valid" ;
VAL_ 342 ReRiAirSprgPSts 0 "InValid" 1 "Valid" ;
VAL_ 342 SCUExtmHeiSts 0 "Normal" 1 "Extreme_High" 2 "Extreme_Low" ;
VAL_ 342 SCULimSpdTqReq 0 "No_request" 1 "Request" ;
VAL_ 342 SCUSelfAwkLvlAdjmt 0 "no_adjust_无调节" 1 "adjusting_调节中" ;
VAL_ 342 SCUWarnLampReq 0 "No_Request" 1 "Yellow_warning_light" 2 "Red_warning_light" ;
VAL_ 342 SCUWarnMsgASC 0 "NoRequest" 1 "SCU_ASC_SysFlt_OverHigh_空气悬架系统故障，车辆过高，请低速慢行" 2 "SCU_ASC_SysFlt_OverLow_空气悬架系统故障，车辆过低，离地间隙受限" 3 "SCU_ASC_SysFlt_空气悬架系统故障，请检修" 4 "Reserved0" 5 "SCU_ASC_Overheatd_空气悬架系统过热，请等待系统冷却" 6 "SCU_ASC_SystemFilling_空气悬架系统正在充气" 7 "Reserved" ;
VAL_ 342 SCUWarnMsgCDC 0 "NoRequest" 1 "SCU_CDC_SysFlt_电控减振系统故障，请检修" 2 "SCU_CDC_FcnLim_电控减振系统性能下降" 3 "Reserved" ;
VAL_ 342 SprgRateSts 0 "Low" 1 "High" 2 "FrntLow_ReHigh" 3 "FrntHigh_ReLow" ;
VAL_ 342 SprgRateStsVld 0 "Invalid" 1 "Valid" ;
VAL_ 342 SptDamprModAllwd 0 "not_allow" 1 "allow" ;
VAL_ 342 StdLvlSpdSwtSts 0 "OFF" 1 "ON" ;
VAL_ 342 StdLvlSpdSwtVld 0 "not_allowed" 1 "allowed" ;
VAL_ 342 SuspHeiAdjmtReqSrc 0 "None" 1 "DCD" 2 "DrvMod" 3 "SCUSpdDpdnt" 4 "CarMod" 5 "EasyEntry" 6 "EasyLoad" ;
VAL_ 342 SuspHeiSetSts 0 "HL2" 1 "HL1" 2 "NL" 3 "LL1" 4 "LL2" ;
VAL_ 342 TarLvlChg 0 "EasyLoad" 1 "HL2" 2 "HL1" 3 "NL" 4 "LL1" 5 "LL2" ;
VAL_ 359 ASCFltSts2 0 "No_Fault" 1 "Level_control_restriction" 2 "Level_control_not_available" 3 "Level_control_not_available_caused_by_system_over_heated" ;
VAL_ 359 BatDamprModAllwd2 0 "not_allow" 1 "allow" ;
VAL_ 359 CDCFltSts2 0 "No_Fault" 1 "Damper_control_restriction" 2 "Damper_control_not_available" 3 "Damper_control_not_available_caused_by_system_over_heated" ;
VAL_ 359 CmftDamprModAllwd2 0 "not_allow" 1 "allow" ;
VAL_ 359 CurDampgCtrlMod2 0 "Comfort" 1 "Normal" 2 "Sport" 3 "Battle" ;
VAL_ 359 ESPEnaReq2 0 "No_Request" 1 "Request" ;
VAL_ 359 LvlCtrlCalCompl2 0 "Level_calibration_not_completed" 1 "Level_calibration_completed" ;
VAL_ 359 LvlModAct2 0 "EasyLoad" 1 "HL2" 2 "HL1" 3 "NL" 4 "LL1" 5 "LL2" ;
VAL_ 359 NormDamprModAllwd2 0 "not_allow" 1 "allow" ;
VAL_ 359 SCUActvAwakeReq 0 "False" 1 "True" ;
VAL_ 359 SCUExtmHeiSts2 0 "Normal" 1 "Extreme_High" 2 "Extreme_Low" ;
VAL_ 359 SCULimSpdTqReq2 0 "No_request" 1 "Request" ;
VAL_ 359 SCUWarnLampReq2 0 "No_Request" 1 "Yellow_warning_light" 2 "Red_warning_light" ;
VAL_ 359 SCUWarnMsgASC2 0 "NoRequest" 1 "SCU_ASC_SysFlt_OverHigh_空气悬架系统故障，车辆过高，请低速慢行" 2 "SCU_ASC_SysFlt_OverLow_空气悬架系统故障，车辆过低，离地间隙受限" 3 "SCU_ASC_SysFlt_空气悬架系统故障，请检修" 4 "Reserved0" 5 "SCU_ASC_Overheatd_空气悬架系统过热，请等待系统冷却" 6 "SCU_ASC_SystemFilling_空气悬架系统正在充气" 7 "Reserved" ;
VAL_ 359 SCUWarnMsgCDC2 0 "NoRequest" 1 "SCU_CDC_SysFlt_电控减振系统故障，请检修" 2 "SCU_CDC_FcnLim_电控减振系统性能下降" 3 "Reserved" ;
VAL_ 359 SprgRateSts2 0 "Low" 1 "High" 2 "FrntLow_ReHigh" 3 "FrntHigh_ReLow" ;
VAL_ 359 SprgRateStsVld2 0 "Invalid" 1 "Valid" ;
VAL_ 359 SptDamprModAllwd2 0 "not_allow" 1 "allow" ;
VAL_ 699 SCUBFaultInfoFlag 0 "No_Fault" 1 "Fault" ;
VAL_ 1000 AsuCrtlDataClctReq 0 "false" 1 "true" ;
VAL_ 1000 AsuCrtlDataClctSts 0 "NoRequest" 1 "SprgUp" 2 "SprgDwn" 3 "SprgReadjust" 4 "CdcAdj" 5 "ResFillg" 6 "ResExh" 7 "Reserve" ;
VAL_ 1000 ASULftDataClctReq 0 "false" 1 "true" ;
VAL_ 1000 CtrlActnFbAvFL 0 "false" 1 "true" ;
VAL_ 1000 CtrlActnFbAvFR 0 "false" 1 "true" ;
VAL_ 1000 CtrlActnFbAvRL 0 "false" 1 "true" ;
VAL_ 1000 CtrlActnFbAvRR 0 "false" 1 "true" ;
VAL_ 1000 CtrlActnFbEv 0 "false" 1 "true" ;
VAL_ 1000 CtrlActnFbMot 0 "false" 1 "true" ;
VAL_ 1000 CtrlActnFbSv1 0 "false" 1 "true" ;
VAL_ 1000 CtrlActnFbSv2 0 "false" 1 "true" ;
VAL_ 1000 CtrlActnFbSv3 0 "false" 1 "true" ;
VAL_ 1000 CtrlActnFbSv4 0 "false" 1 "true" ;
VAL_ 1000 ScuAcMode 0 "OFF" 1 "UP_FA" 2 "UP_RA" 3 "UP_FL" 4 "UP_FR" 5 "UP_RL" 6 "UP_RR" 7 "DOWN_FA" 8 "DOWN_RA" 9 "DOWN_FL" 10 "DOWN_FR" 11 "DOWN_RL" 12 "DOWN_RR" 13 "FA_PRESSURE_BALANCE" 14 "RA_PRESSURE_BALANCE" 15 "GET_PRESSURE_RSV" 16 "GET_PRESSURE_FL" 17 "GET_PRESSURE_FR" 18 "GET_PRESSURE_RL" 19 "GET_PRESSURE_RR" 20 "FILL_LPA" 21 "FILL_FA_ONLY_PUMP" 22 "FILL_RA_ONLY_PUMP" 23 "REGEN_LPA_DEFLATE" 24 "DEFLATE_2_AMB_FA" 25 "DEFLATE_2_AMB_RA" 26 "LPA_DEFLATE" 27 "FILL_FL_ONLY_PUMP" 28 "FILL_FR_ONLY_PUMP" 29 "FILL_RL_ONLY_PUMP" 30 "FILL_RR_ONLY_PUMP" 31 "DEFLATE_2_AMB_FL" 32 "DEFLATE_2_AMB_FR" 33 "DEFLATE_2_AMB_RL" 34 "DEFLATE_2_AMB_RR" 35 "OVERFLOW_UP_FARA" 36 "DEFLATE_2_AMB_SYS_SLOW" 37 "DEFLATE_2_AMB_SYS" 38 "OVERFLOW_UP_FA" 39 "OVERFLOW_UP_RA" 40 "OVERFLOW_UP_FL" 41 "OVERFLOW_UP_FR" 42 "OVERFLOW_UP_RL" 43 "OVERFLOW_UP_RR" 44 "OVERFLOW_DOWN_FA" 45 "OVERFLOW_DOWN_RA" 46 "OVERFLOW_DOWN_FL" 47 "OVERFLOW_DOWN_FR" 48 "OVERFLOW_DOWN_RL" 49 "OVERFLOW_DOWN_RR" ;
VAL_ 1000 SuspAirMDataClctReq 0 "NoRequest" 1 "Request" ;
VAL_ 1000 SuspAirMDataClctSts 0 "NoRequest" 1 "InitialPowerOn" 2 "FrcdFillgActv" 3 "FrcdFillgEnd" 4 "SpdFillgActv" 5 "SpdFillgEnd" 6 "ChrgnFillgActv" 7 "ChrgnFillgEnd" 8 "WakeFillgActv" 9 "WakeFillgEnd" 10 "SpdExhActv" 11 "SpdExhEnd" 12 "FrcdExhActv" 13 "FrcdExhEnd" 14 "Leak" 15 "Reserve" ;
VAL_ 1000 SuspWthrFcstAuthnSts 0 "false" 1 "true" ;
VAL_ 156 RtcWake1AjustStsFL 0 "Inactive" 1 "Active" ;
VAL_ 156 RtcWake1AjustStsFR 0 "Inactive" 1 "Active" ;
VAL_ 156 RtcWake1AjustStsRL 0 "Inactive" 1 "Active" ;
VAL_ 156 RtcWake1AjustStsRR 0 "Inactive" 1 "Active" ;
VAL_ 156 RtcWake1DateTimeDay 0 "init" ;
VAL_ 156 RtcWake1DateTimeMth 0 "Invalid" ;
VAL_ 156 RtcWake1DateTimeYr 255 "Invalid" ;
VAL_ 156 RtcWake1Valid 0 "Invalid" 1 "valid" ;
VAL_ 156 RtcWake2AjustStsFL 0 "Inactive" 1 "Active" ;
VAL_ 156 RtcWake2AjustStsFR 0 "Inactive" 1 "Active" ;
VAL_ 156 RtcWake2AjustStsRL 0 "Inactive" 1 "Active" ;
VAL_ 156 RtcWake2AjustStsRR 0 "Inactive" 1 "Active" ;
VAL_ 156 RtcWake2DateTimeDay 0 "init" ;
VAL_ 156 RtcWake2DateTimeMth 0 "Invalid" ;
VAL_ 156 RtcWake2DateTimeYr 255 "Invalid" ;
VAL_ 156 RtcWake2Valid 0 "Invalid" 1 "valid" ;
VAL_ 156 RtcWake3AjustStsFL 0 "Inactive" 1 "Active" ;
VAL_ 156 RtcWake3AjustStsFR 0 "Inactive" 1 "Active" ;
VAL_ 156 RtcWake3AjustStsRL 0 "Inactive" 1 "Active" ;
VAL_ 156 RtcWake3AjustStsRR 0 "Inactive" 1 "Active" ;
VAL_ 156 RtcWake3DateTimeDay 0 "init" ;
VAL_ 156 RtcWake3DateTimeMth 0 "Invalid" ;
VAL_ 156 RtcWake3DateTimeYr 255 "Invalid" ;
VAL_ 156 RtcWake3Valid 0 "Invalid" 1 "valid" ;
VAL_ 157 ScuIGOffDateTimeDay 0 "init" ;
VAL_ 157 ScuIGOffDateTimeMth 0 "Invalid" ;
VAL_ 157 ScuIGOffDateTimeYr 255 "Invalid" ;
VAL_ 182 FrntLeCurHeiSts 0 "InValid" 1 "Valid" ;
VAL_ 182 FrntRiCurHeiSts 0 "InValid" 1 "Valid" ;
VAL_ 182 ReLeCurHeiSts 0 "InValid" 1 "Valid" ;
VAL_ 182 ReRiCurHeiSts 0 "InValid" 1 "Valid" ;
VAL_ 192 FrntLeCurHeiSts2 0 "InValid" 1 "Valid" ;
VAL_ 192 FrntRiCurHeiSts2 0 "InValid" 1 "Valid" ;
VAL_ 192 ReLeCurHeiSts2 0 "InValid" 1 "Valid" ;
VAL_ 192 ReRiCurHeiSts2 0 "InValid" 1 "Valid" ;
VAL_ 1323 SCUChassisCanfdActiveWakeup 0 "passive_wakeup" 1 "active_Wakeup" ;
VAL_ 1323 SCUChassisCanfdRepeatMsgReq 0 "Repeat_Message_State_not_requested" 1 "Repeat_Message_State_requested" ;
VAL_ 1323 SCUChassisCanfdRepeatMsgSt 0 "Not_in_Repeat_Message_State" 1 "In_Repeat_Message_State" ;
VAL_ 419 ColShiftLvrDiagc 0 "No_Failure" 1 "Failure" ;
VAL_ 419 DrvrGearShiftParkReq 0 "Not_Pressed" 1 "Pressed" 2 "Invalid" ;
VAL_ 419 GearShiftPosReq 0 "Center" 1 "Up" 2 "UpUp" 3 "Dwn" 4 "DwnDwn" 5 "Invalid" ;
VAL_ 419 RearWiprPushSwt 0 "Not_Pressed" 1 "RearWiperPressed" 2 "RearWashPressed" 3 "Invalid" ;
VAL_ 419 SWMFaultInfoFlag 0 "No_Fault" 1 "Fault" ;
VAL_ 419 SwtHiBeam 0 "Neutral" 1 "Pull" 2 "Push" 3 "Invalid" ;
VAL_ 419 SwtIndcrRaw 0 "Center" 1 "Up" 2 "UpUp" 3 "Dwn" 4 "DwnDwn" 5 "Invalid" ;
VAL_ 419 WiprPushSwt 0 "Not_Pressed" 1 "1st_Pressed" 2 "2nd_Pressed" 3 "Invalid_" ;
VAL_ 1319 SWMActiveWakeup 0 "passive_wakeup" 1 "active_Wakeup" ;
VAL_ 1319 SWMRepeatMsgReq 0 "Repeat_Message_State_not_requested" 1 "Repeat_Message_State_requested" ;
VAL_ 1319 SWMRepeatMsgSt 0 "Not_in_Repeat_Message_State" 1 "In_Repeat_Message_State" ;
VAL_ 263 DateTiDay 0 "init" ;
VAL_ 263 DateTiHr 24 "Invalid" ;
VAL_ 263 DateTiMilsec 0 "0" 999 "999" 1000 "invalid" ;
VAL_ 263 DateTiMins 60 "Invalid" ;
VAL_ 263 DateTiMth 0 "Invalid" ;
VAL_ 263 DateTiSec 60 "Invalid" ;
VAL_ 263 DateTiYr 255 "Invalid" ;
VAL_ 263 TiDomn 0 "UTC_plus_0" 1 "UTC_plus_1" 2 "UTC_plus_2" 3 "UTC_plus_3" 4 "UTC_plus_4" 5 "UTC_plus_5" 6 "UTC_plus_6" 7 "UTC_plus_7" 8 "UTC_plus_8" 9 "UTC_plus_9" 10 "UTC_plus_10" 11 "UTC_plus_11" 12 "UTC_plus_12" 13 "UTC_plus_13" 14 "UTC_plus_14" 15 "UTC_plus_15" 16 "UTC_plus_16" 17 "UTC_plus_17" 18 "UTC_plus_18" 19 "UTC_plus_19" 20 "UTC_plus_20" 21 "UTC_plus_21" 22 "UTC_plus_22" 23 "UTC_plus_23" 24 "Invalid" ;
VAL_ 345 DiagcExtActv 0 "No" 1 "Yes" ;
VAL_ 345 profileRestoreFactoryReqSoa 0 "None" 1 "Enable" ;
VAL_ 549 ADSELKSwtSet 0 "No_Command" 1 "Off" 2 "Middle" 3 "High" ;
VAL_ 549 ADSFltQuitReqFrmDCD 0 "default" 1 "Quit_Request" 2 "reserved_1" 3 "reserved_2" ;
VAL_ 549 DCDAvmFrCamSts 0 "OFF" 1 "Standby" 2 "Normal" 3 "Blocked(Reserved)" 4 "Error" 5 "Reserved1" 6 "Reserved2" 7 "Reserved3" ;
VAL_ 549 DCDAvmLeCamSts 0 "OFF" 1 "Standby" 2 "Normal" 3 "Blocked(Reserved)" 4 "Error" 5 "Reserved1" 6 "Reserved2" 7 "Reserved3" ;
VAL_ 549 DCDAvmReCamSts 0 "OFF" 1 "Standby" 2 "Normal" 3 "Blocked(Reserved)" 4 "Error" 5 "Reserved1" 6 "Reserved2" 7 "Reserved3" ;
VAL_ 549 DCDAvmRiCamSts 0 "OFF" 1 "Standby" 2 "Normal" 3 "Blocked(Reserved)" 4 "Error" 5 "Reserved1" 6 "Reserved2" 7 "Reserved3" ;
VAL_ 549 DCDDisplayFailSts 0 "No_Failure" 1 "No_Comm_with_CIDM" 2 "CIDM_internal_display_error" 3 "DCD_actively_shutdown_display" 4 "CIDM_freeze_frame_detected" 5 "reserved_1" 6 "reserved_2" 7 "reserved_3" ;
VAL_ 549 DCDDltAllKeyCmd 0 "No_Command" 1 "Delete_all_key" ;
VAL_ 549 ExtrLiFcnSet 0 "No_Command" 1 "Off" 2 "Position_Lamp" 3 "Low_Beam" 4 "Auto" ;
VAL_ 549 WiprSpdAdjCfgSet 0 "No_Command" 1 "OFF" 2 "IntermittentWipingRequest_LowSpeed" 3 "IntermittentWipingRequest_HighSpeed" 4 "LowSpeedWipingRequest" 5 "HighSpeedWipingRequest" 6 "AutoWipingSpeed" 7 "Reserve" ;
VAL_ 864 DCDICVehSrvAuthntSts 0 "Default" 1 "Unauthorized" 2 "Authorized" 3 "Reserved" ;
VAL_ 864 VehInsSpdDispVld 0 "Valid" 1 "Invalid" ;
VAL_ 910 SuspHeiSetSoa 0 "No_Command" 1 "HL2" 2 "HL1" 3 "NL" 4 "LL1" 5 "LL2" ;
VAL_ 914 TotOdoAcrt 16777215 "Invaild" ;
VAL_ 914 TotOdoAcrtLvlM -2147483648 "Invaild" ;
VAL_ 914 TotOdoAcrtLvlMVld 0 "Valid" 1 "Invalid" ;
VAL_ 914 TotOdoAcrtVld 0 "Valid" 1 "Invalid" ;
VAL_ 931 AVHBtn 0 "Not_Pressed" 1 "Pressed" ;
VAL_ 931 AVHSet 0 "No_Command" 1 "AVH_Off" 2 "AVH_On" ;
VAL_ 931 CSTOnOffBtn 0 "Not_Pressed" 1 "Pressed" ;
VAL_ 931 CSTOnOffSet 0 "No_Command" 1 "CST_Off" 2 "CST_On" ;
VAL_ 931 DCDBattHlthMngtFcnSwt 0 "No_command" 1 "Disable_Command" 2 "Enable_Command" ;
VAL_ 931 DCDEasyEntryHeiSet 0 "NoCommand" 1 "HL2" 2 "HL1" 3 "NL" 4 "LL1" 5 "LL2" ;
VAL_ 931 DCDHDCSet 0 "No_command" 1 "Off" 2 "On" ;
VAL_ 931 DCDJackModSet 0 "NoCommand" 1 "JackModOff" 2 "JackModOn" ;
VAL_ 931 DCDStdLvlSpdSwt 0 "NoCommand" 1 "Off" 2 "On" ;
VAL_ 931 EasyEntryModReqBtn 0 "Not_Pressed" 1 "Pressed" ;
VAL_ 931 EasyEntryModSet 0 "No_cmd" 1 "Easy_Entry_OFF" 2 "Easy_Entry_ON" ;
VAL_ 931 EasyLoadgFuncCouplSet 0 "No_Cmd" 1 "Coupling_OFF" 2 "Coupling_On" ;
VAL_ 931 EasyLoadgModReqBtn 0 "Not_Pressed" 1 "Pressed" ;
VAL_ 931 EasyLoadgModSet 0 "No_cmd" 1 "Easy_Loading_OFF" 2 "Easy_Loading_ON" ;
VAL_ 931 EPBSwtSet 0 "no_command" 1 "Release" 2 "Apply" 3 "Not_Used" ;
VAL_ 931 ESCOffSet 0 "No_Command" 1 "ESC_OFF" 2 "ESC_ON" 3 "INVALID" ;
VAL_ 931 SuspHeiSet 0 "No_Command" 1 "HL2" 2 "HL1" 3 "NL" 4 "LL1" 5 "LL2" ;
VAL_ 997 CurAmbHumValSoa 0 "Invalid" 1 "Valid" ;
VAL_ 997 CurAmbTValSoa 0 "Invalid" 1 "Valid" ;
VAL_ 997 LowtAmbTTomwValSoa 0 "Invalid" 1 "Valid" ;
VAL_ 1023 VidBlkId 0 "Invalid" 1 "Block_1" 2 "Block_2" 3 "Block_3" ;
VAL_ 1023 VinVINBlkID 0 "Invalid" 1 "Block_1" 2 "Block_2" 3 "Block_3" ;
VAL_ 389 AdasSwt 0 "Not_Pressed" 1 "Pressed" 2 "Error" 3 "Reserved" ;
VAL_ 389 AdasSwtSigGrpLinErr 0 "NoErr" 1 "CounterErr" 2 "CRCErr" 3 "CounterErr_CRCErr" ;
VAL_ 389 ChrgLidSts 0 "Ukwn" 1 "Open" 2 "Clsd" ;
VAL_ 389 DoorDrvrSts 0 "Ukwn" 1 "Opend" 2 "Clsd" ;
VAL_ 389 DoorLeReSts 0 "Ukwn" 1 "Opend" 2 "Clsd" ;
VAL_ 389 DoorPassSts 0 "Ukwn" 1 "Opend" 2 "Clsd" ;
VAL_ 389 DoorRiReSts 0 "Ukwn" 1 "Opend" 2 "Clsd" ;
VAL_ 389 HoodOpenClsSts 0 "Ukwn" 1 "Open" 2 "Clsd" ;
VAL_ 389 LeKnobCounter 255 "Invalid" ;
VAL_ 389 LeMFctActSgCe 0 "Not_Pressed" 1 "Pressed" 2 "Error" 3 "Reserved" ;
VAL_ 389 LeMFctActSgLe 0 "Not_Pressed" 1 "Pressed" 2 "Error" 3 "Reserved" ;
VAL_ 389 LeMFctActSgRi 0 "Not_Pressed" 1 "Pressed" 2 "Error" 3 "Reserved" ;
VAL_ 389 RiMFctActSgCe 0 "Not_Pressed" 1 "Pressed" 2 "Error" 3 "Reserved" ;
VAL_ 389 TrOpenClsSts 0 "Ukwn" 1 "Open" 2 "Clsd" ;
VAL_ 520 ARSPosnSts 0 "Unknown" 1 "P0" 2 "P1" 3 "P2" 4 "P3" 5 "OpenHardStop" 6 "CloseHardStop" 7 "LessPo" 8 "MoreP3" 9 "OtherPosn" 10 "BtwP0P1" 11 "BtwP1P2" 12 "BtwP2P3" ;
VAL_ 520 RlsLinComFltSts 0 "No_Fault" 1 "Node_Miss" ;
VAL_ 768 FLRLLoPwrSplySts 0 "Off" 1 "On" ;
VAL_ 768 FrntShdADCameraDefrstErrFb 0 "Flt_NoFault" 1 "Flt_Fault" ;
VAL_ 768 FrntShdADCameraDefrstSts 0 "Off" 1 "On" ;
VAL_ 768 IMULoPwrSplySts 0 "Off" 1 "On" ;
VAL_ 768 LockgCenLockSts 0 "Not_defined" 1 "Unlocked" 2 "Locked" 3 "Partially_unlocked" ;
VAL_ 768 RSRLoPwrSplySts 0 "Off" 1 "On" ;
VAL_ 1313 VCCDChassisBkpActiveWakeup 0 "passive_wakeup" 1 "active_Wakeup" ;
VAL_ 1313 VCCDChassisBkpRepeatMsgReq 0 "not_requested" 1 "requested" ;
VAL_ 1313 VCCDChassisBkpRepeatMsgSt 0 "Not_in_Repeat_Message_State" 1 "In_Repeat_Message_State" ;
SIG_GROUP_ 186 BrkSysCtrlBkpSigGrp 1 : BrkSysCtrlBkpSigGrpChks BrkSysCtrlBkpSigGrpCntr BrkSysMstCylP BrkSysMstCylPVld BrkSysPRedActv BrkSysPSysTar BrkSysRntSpprtAvl BrkSysVehDirInfo BrkSysVehDirInfoVld BrkSysVehSpd BrkSysVehSpdVld BrkSysVolSuctnActv VehicleStandStill VehicleStandStillQ;
SIG_GROUP_ 186 BrkSysIndcnBkpSigGrp 1 : ABSAvailability BCSFxTargetMod BCSModBrakeActType BCSRecuFxRedTarget BCSRecuStatusMod BrkSysAbsActv BrkSysDrvrPrsnt BrkSysIndcnBkpSigGrpChks BrkSysIndcnBkpSigGrpCntr BrkSysLdmGlbStsMod BrkSysPEstimnMax;
SIG_GROUP_ 186 MaxTarSpdBkpSigGrp 1 : MaxTarSpdBkpSigGrpChks MaxTarSpdBkpSigGrpCntr MaxTarSpdFrntAxle MaxTarSpdFrntAxleRels MaxTarSpdReAxle MaxTarSpdReAxleRels VehVrnt;
SIG_GROUP_ 190 BrkSysAPCMain2BkpStCom2SigGrp 1 : BrkSysAPCBkpStgyReqCom2 BrkSysAPCMain2BkpStCom2 BrkSysAPCMain2BkpStCom2SigGrpChk BrkSysAPCMain2BkpStCom2SigGrpCnt;
SIG_GROUP_ 190 RpbCtrlBkpSigGrp 1 : RpbCtrlBkpSigGrpChks RpbCtrlBkpSigGrpCntr RPBHpsAck RPBHpsAvl RPBMstCylP RPBMstCylPVld RPBWhlPFrntLe RPBWhlPFrntLeVld RPBWhlPFrntRi RPBWhlPFrntRiVld RPBWhlPReLe RPBWhlPReLeVld RPBWhlPReRi RPBWhlPReRiVld;
SIG_GROUP_ 190 RPBWhlSpdSigGrp 1 : RPBWhlSpdFrntLe RPBWhlSpdFrntLeVld RPBWhlSpdFrntRi RPBWhlSpdFrntRiVld RPBWhlSpdReLe RPBWhlSpdReLeVld RPBWhlSpdReRi RPBWhlSpdReRiVld RPBWhlSpdSigGrpChks RPBWhlSpdSigGrpCntr WhlPulFrntLe WhlPulFrntRi WhlPulReLe WhlPulReRi;
SIG_GROUP_ 355 EPSAVPHPPCtrlStsBkpSigGrp 1 : AVPHPPCtrlAvlStsBkp AVPHPPCtrStsBkp AVPHPPReqFbStsBkp AVPHPPReqFltStsBkp EPSAVPHPPCtrlStsBkpSigGrpChks EPSAVPHPPCtrlStsBkpSigGrpCntr;
SIG_GROUP_ 355 FailrStsBkpSigGrp 1 : FailrStsBkp FailrStsBkpSigGrpChks FailrStsBkpSigGrpCntr;
SIG_GROUP_ 200 SteeringWhlSignalBkpSigGrp 1 : PinionAglSpdBkpV2C PinionSteerAglBkp PinionSteerAglBkpV2C PinionSteerAglSpdBkp PinionSteerAglSpdVldBkp PinionSteerAglSpdVldBkpV2C PinionSteerAglVldBkp PinionSteerAglVldBkpV2C SteeringWhlSignalBkpSigGrpChks SteeringWhlSignalBkpSigGrpCntr SteerWhlTqBkp SteerWhlTqVldBkp;
SIG_GROUP_ 347 ReElsdCtrlSigGrp 1 : VCUReElsdLvlReq VCUReElsdOpenReq;
SIG_GROUP_ 515 ModStsSigGrp 1 : VCUTrlrModStSts;
SIG_GROUP_ 656 InsEgyCnsSigGrp 1 : InsEgyCnsSigGrpChks InsEgyCnsSigGrpCntr VCUEgyCnsInCurDrvCyc VCUEstimdCrsRng VCUEstimdCrsRngForCltc VCUEstimdCrsRngVld VCUInsEgyCnsDurgDrvg VCUInsEgyCnsDurgStsl VCUInsEgyCnsFlg;
SIG_GROUP_ 656 VehSysFltWarnSigGrp 1 : VCUBattOverHeatWarn VCUDrvMotFltWarn VCUDrvMotOverHeatWarn VCUDrvSysLimdWarn VCUGearChgFailInde VCUHvBattSysFltIndcr VCUHvBattSysFltWarn VCUHvPwrSysCutOff VCUHVSysFltWarnSts VCULoSocWarngMsg VCUPrpsnPwrDrt VCUThermRunawayErrAlrm VCUVehSysFltWarn VehSysFltWarnSigGrpChks VehSysFltWarnSigGrpCntr;
SIG_GROUP_ 144 PwrModSigGrp 1 : PwrModSigGrpChks PwrModSigGrpCntr PwrModSts PwrModVld;
SIG_GROUP_ 144 VCUActGearSigGrp 1 : VCUActGearLvr VCUActGearLvrVld VCUActGearSigGrpChks VCUActGearSigGrpCntr;
SIG_GROUP_ 144 VcuDrvModCtrlSigGrp 1 : VCUDrvModSteerAsstPrmSts VCUDrvModSuspDampgPrmSts;
SIG_GROUP_ 144 VcuInpSigGrp 1 : VCUAccrPedlRat VCUAccrPedlRatVld VCUDrvOffFcnLim VCUFrntEmTqRdy VCUGearLvrAvail VcuInpSigGrpChks VcuInpSigGrpCntr VCUPrkgBtnPsd VCUReEmTqRdy VCURgnTqCorrnFac VCUShifterMoveFlg VCUStsModCst VCUTarGearLvr VCUTarGearLvrVld VCUVirtAccrPedl VCUVirtAccrPedlVld;
SIG_GROUP_ 188 DmcModMonSigGrp 1 : DmcModMonSigGrpChks DmcModMonSigGrpCntr VCUOperModFAOfDMC VCUOperModRAOfDMC VCUSWVersOfDMC VCUTarTqFAAOfDMC VCUTarTqRAOfDMC;
SIG_GROUP_ 188 FrntMotCtrlSigGrp 1 : FrntMotCtrlSigGrpChks FrntMotCtrlSigGrpCntr VCUFrntDesTqWoIntv VCUFrntDesTqWoIntvVld VCUFrntMotActSpd VCUFrntMotActSpdVld VCUFrntMotActTq VCUFrntMotActTqVld VCUFrntMotWhlTqReq VCUFrntMotWhlTqReqVld VCUFrntWhlTqMaxAvl VCUFrntWhlTqMaxAvlVld VCUFrntWhlTqMinAvl VCUFrntWhlTqMinAvlVld;
SIG_GROUP_ 188 ReMotCtrlSigGrp 1 : ReMotCtrlSigGrpChks ReMotCtrlSigGrpCntr VCUReDesTqWoIntv VCUReDesTqWoIntvVld VCUReMotActSpd VCUReMotActSpdVld VCUReMotActTq VCUReMotActTqVld VCUReMotWhlTqReq VCUReMotWhlTqReqVld VCUReWhlTqMaxAvl VCUReWhlTqMaxAvlVld VCUReWhlTqMinAvl VCUReWhlTqMinAvlVld VCUWhlTqMaxAvl VCUWhlTqMaxAvlVld;
SIG_GROUP_ 188 VDMVehSpdEstmGrp 1 : VDMLgtWhlSpdFL VDMLgtWhlSpdFR VDMLgtWhlSpdRL VDMLgtWhlSpdRR VDMVehSpdEstmGrpChks VDMVehSpdEstmGrpCntr VehBodySideSlipAng VehLatSpdEstd VehLatSpdEstdVld VehLgtSpdEstd VehLgtSpdEstdVld;
SIG_GROUP_ 342 SCUWarnSigGrp 1 : ASCFltSts CDCFltSts ESPEnaReq SCUExtmHeiSts SCULimSpdTqReq SCUWarnLampReq SCUWarnMsgASC SCUWarnMsgCDC SCUWarnSigGrpChks SCUWarnSigGrpCntr;
SIG_GROUP_ 359 SCUWarnSigGrp2 1 : ASCFltSts2 CDCFltSts2 ESPEnaReq2 SCUExtmHeiSts2 SCULimSpdTqReq2 SCUWarnLampReq2 SCUWarnMsgASC2 SCUWarnMsgCDC2 SCUWarnSigGrp2Chks SCUWarnSigGrp2Cntr;
SIG_GROUP_ 1000 AirMassBigData 1 : AccumIntkAirM AccumNrFillg AccumWtrIntkWght PrsntAirMData PrsntLoadData SuspAirMDataClctSts SuspClctCurAmbHum SuspClctCurAmbPSOA SuspClctCurAmbT SuspClctCurAmbTSOA SuspWthrFcstAuthnSts;
SIG_GROUP_ 1000 AsuCtrlBigData 1 : AsuCrtlDataClctSts CtrlActnFbAvFL CtrlActnFbAvFR CtrlActnFbAvRL CtrlActnFbAvRR CtrlActnFbEv CtrlActnFbMot CtrlActnFbSv1 CtrlActnFbSv2 CtrlActnFbSv3 CtrlActnFbSv4 ScuAcMode;
SIG_GROUP_ 1000 CmpOperModCntr 1 : CmpOperModCntrDwnLvlg CmpOperModCntrOvfDwnLvlg CmpOperModCntrOvfUpLvlg CmpOperModCntrResvFillg CmpOperModCntrUpLvlg;
SIG_GROUP_ 1000 CmpRtCntr 1 : CmpRtCntrDwnLvlg CmpRtCntrTot CmpRtCntrTotResvFillg CmpRtCntrUpLvlg;
SIG_GROUP_ 1000 NrActvnVlv 1 : NrActvnAv1Vlv NrActvnAv2Vlv NrActvnAv3Vlv NrActvnAv4Vlv NrActvnEvVlv NrActvnSv1Vlv NrActvnSv2Vlv NrActvnSv3Vlv NrActvnSv4Vlv;
SIG_GROUP_ 1000 ScuBigDataClctReq 1 : AsuCrtlDataClctReq ASULftDataClctReq SuspAirMDataClctReq;
SIG_GROUP_ 182 CurHeiSigGrp 1 : CurHeiSigGrpChks CurHeiSigGrpCntr FrntLeCurHei FrntLeCurHeiSts FrntRiCurHei FrntRiCurHeiSts ReLeCurHei ReLeCurHeiSts ReRiCurHei ReRiCurHeiSts;
SIG_GROUP_ 182 SCUAccrSnsr 1 : AccrSnsrAzFrntLe AccrSnsrAzFrntRi AccrSnsrAzRe SCUAccrSnsrChks SCUAccrSnsrCntr;
SIG_GROUP_ 192 CurHeiSigGrp2 1 : CurHeiSigGrp2Chks CurHeiSigGrp2Cntr FrntLeCurHei2 FrntLeCurHeiSts2 FrntRiCurHei2 FrntRiCurHeiSts2 ReLeCurHei2 ReLeCurHeiSts2 ReRiCurHei2 ReRiCurHeiSts2;
SIG_GROUP_ 419 DrvrGearShiftParkReqSigGrp 1 : DrvrGearShiftParkReq DrvrGearShiftParkReqSigGrpChks DrvrGearShiftParkReqSigGrpCntr;
SIG_GROUP_ 419 GearShiftPosReqSigGrp 1 : GearShiftPosReq GearShiftPosReqSigGrpChks GearShiftPosReqSigGrpCntr;
SIG_GROUP_ 419 SwtIndcrRawSigGrp 1 : SwtIndcrRaw SwtIndcrRawSigGrpChks SwtIndcrRawSigGrpCntr;
SIG_GROUP_ 549 DCDAvmCamE2ESigGrp 1 : DCDAvmCamE2ESigGrpChks DCDAvmCamE2ESigGrpCntr DCDAvmFrCamSts DCDAvmLeCamSts DCDAvmReCamSts DCDAvmRiCamSts;
SIG_GROUP_ 549 DCDHmiE2ESigGrp 1 : ExtrLiFcnSet ExtrLiFcnSetSigGrpChks ExtrLiFcnSetSigGrpCntr WiprSpdAdjCfgSet;
SIG_GROUP_ 1023 Vid 1 : VidBlkId VidSignalPos1 VidSignalPos2 VidSignalPos3 VidSignalPos4 VidSignalPos5 VidSignalPos6 VidSignalPos7;
SIG_GROUP_ 135 VehCfgPrm 1 : VehCfgPrmBlkIDBytePosn1 VehCfgPrmCCPBytePosn2 VehCfgPrmCCPBytePosn3 VehCfgPrmCCPBytePosn4 VehCfgPrmCCPBytePosn5 VehCfgPrmCCPBytePosn6 VehCfgPrmCCPBytePosn7 VehCfgPrmCCPBytePosn8;
SIG_GROUP_ 389 AdasSwtSigGrp 1 : AdasSwt AdasSwtSigGrpChks AdasSwtSigGrpCntr AdasSwtSigGrpLinErr;
